AUTOSAR XML (schema 4-3-0)
package /MICROSAR/Dem_swc/DataTypes
  22 x impl type:
    Dem_EventIdType: range raw 1..65535, implementation-data-type=uint16
    Dem_RatioIdType: range raw 1..65535, implementation-data-type=uint16
    Dem_DTCStatusMaskType: range raw 0..255, implementation-data-type=uint8
    Dem_OperationCycleIdType: range raw 0..255, implementation-data-type=uint8
    Dem_DTCGroupType: range raw 0..16777215, implementation-data-type=uint32
    Dem_MaxDataValueType: category=ARRAY, sw-calibration-access=READ-ONLY
      element Dem_MaxDataValueTypeElement: array-size=1, array-size-semantics=FIXED-SIZE, implementation-data-type=uint8
    Dem_UdsStatusByteType: compu {mask 1: 1=DEM_UDS_STATUS_TF, mask 2: 2=DEM_UDS_STATUS_TFTOC, mask 4: 4=DEM_UDS_STATUS_PDTC, mask 8: 8=DEM_UDS_STATUS_CDTC, mask 16: 16=DEM_UDS_STATUS_TNCSLC, mask 32: 32=DEM_UDS_STATUS_TFSLC, mask 64: 64=DEM_UDS_STATUS_TNCTOC, mask 128: 128=DEM_UDS_STATUS_WIR}, range raw 0..255, implementation-data-type=uint8
    Dem_InitMonitorReasonType: compu {1=DEM_INIT_MONITOR_CLEAR, 2=DEM_INIT_MONITOR_RESTART, 3=DEM_INIT_MONITOR_REENABLED, 4=DEM_INIT_MONITOR_STORAGE_REENABLED}, implementation-data-type=uint8
    Dem_DTCFormatType: compu {0=DEM_DTC_FORMAT_OBD, 1=DEM_DTC_FORMAT_UDS, 2=DEM_DTC_FORMAT_J1939}, implementation-data-type=uint8
    Dem_OperationCycleStateType: compu {0=DEM_CYCLE_STATE_START, 1=DEM_CYCLE_STATE_END}, implementation-data-type=uint8
    Dem_IndicatorStatusType: compu {0=DEM_INDICATOR_OFF, 1=DEM_INDICATOR_CONTINUOUS, 2=DEM_INDICATOR_BLINKING, 3=DEM_INDICATOR_BLINK_CONT, 4=DEM_INDICATOR_SLOW_FLASH, 5=DEM_INDICATOR_FAST_FLASH, 6=DEM_INDICATOR_ON_DEMAND, 7=DEM_INDICATOR_SHORT}, implementation-data-type=uint8
    Dem_DTCKindType: compu {1=DEM_DTC_KIND_ALL_DTCS, 2=DEM_DTC_KIND_EMISSION_REL_DTCS}, implementation-data-type=uint8
    Dem_IumprDenomCondIdType: compu {1=DEM_IUMPR_GENERAL_DENOMINATOR, 2=DEM_IUMPR_DEN_COND_COLDSTART, 3=DEM_IUMPR_DEN_COND_EVAP, 4=DEM_IUMPR_DEN_COND_500MI}, implementation-data-type=uint8
    Dem_IumprDenomCondStatusType: compu {0=DEM_IUMPR_DEN_STATUS_NOT_REACHED, 1=DEM_IUMPR_DEN_STATUS_REACHED, 2=DEM_IUMPR_DEN_STATUS_INHIBITED}, implementation-data-type=uint8
    Dem_DebounceResetStatusType: compu {0=DEM_DEBOUNCE_STATUS_FREEZE, 1=DEM_DEBOUNCE_STATUS_RESET}, implementation-data-type=uint8
    Dem_DebouncingStateType: compu {mask 1: 1=DEM_TEMPORARILY_DEFECTIVE, mask 2: 2=DEM_FINALLY_DEFECTIVE, mask 4: 4=DEM_TEMPORARILY_HEALED, mask 8: 8=DEM_TEST_COMPLETE, mask 16: 16=DEM_DTR_UPDATE}, range raw 0..255, implementation-data-type=uint8
    Dem_EventStatusType: compu {0=DEM_EVENT_STATUS_PASSED, 1=DEM_EVENT_STATUS_FAILED, 2=DEM_EVENT_STATUS_PREPASSED, 3=DEM_EVENT_STATUS_PREFAILED, 4=DEM_EVENT_STATUS_FDC_THRESHOLD_REACHED, 5=DEM_EVENT_STATUS_PASSED_CONDITIONS_NOT_FULFILLED, 6=DEM_EVENT_STATUS_FAILED_CONDITIONS_NOT_FULFILLED, 7=DEM_EVENT_STATUS_PREPASSED_CONDITIONS_NOT_FULFILLED, 8=DEM_EVENT_STATUS_PREFAILED_CONDITIONS_NOT_FULFILLED}, implementation-data-type=uint8
    Dem_DTCOriginType: compu {1=DEM_DTC_ORIGIN_PRIMARY_MEMORY, 2=DEM_DTC_ORIGIN_MIRROR_MEMORY, 3=DEM_DTC_ORIGIN_PERMANENT_MEMORY, 4=DEM_DTC_ORIGIN_OBD_RELEVANT_MEMORY, 5=DEM_DTC_ORIGIN_SECONDARY_MEMORY, 5=DEM_DTC_ORIGIN_USERDEFINED_MEMORY_10, 5=DEM_DTC_ORIGIN_USERDEFINED_MEMORY_11, 5=DEM_DTC_ORIGIN_USERDEFINED_MEMORY_12, 5=DEM_DTC_ORIGIN_USERDEFINED_MEMORY_13, 5=DEM_DTC_ORIGIN_USERDEFINED_MEMORY_14, 5=DEM_DTC_ORIGIN_USERDEFINED_MEMORY_15, 5=DEM_DTC_ORIGIN_USERDEFINED_MEMORY_16, 5=DEM_DTC_ORIGIN_USERDEFINED_MEMORY_17, 5=DEM_DTC_ORIGIN_USERDEFINED_MEMORY_18, 5=DEM_DTC_ORIGIN_USERDEFINED_MEMORY_19, 5=DEM_DTC_ORIGIN_USERDEFINED_MEMORY_1A, 5=DEM_DTC_ORIGIN_USERDEFINED_MEMORY_1B, 5=DEM_DTC_ORIGIN_USERDEFINED_MEMORY_1C, 5=DEM_DTC_ORIGIN_USERDEFINED_MEMORY_1D, 5=DEM_DTC_ORIGIN_USERDEFINED_MEMORY_1E, 5=DEM_DTC_ORIGIN_USERDEFINED_MEMORY_1F, 5=DEM_DTC_ORIGIN_USERDEFINED_MEMORY_20, 5=DEM_DTC_ORIGIN_USERDEFINED_MEMORY_21, 5=DEM_DTC_ORIGIN_USERDEFINED_MEMORY_22, 5=DEM_DTC_ORIGIN_USERDEFINED_MEMORY_23, 5=DEM_DTC_ORIGIN_USERDEFINED_MEMORY_24, 5=DEM_DTC_ORIGIN_USERDEFINED_MEMORY_25, 5=DEM_DTC_ORIGIN_USERDEFINED_MEMORY_26, 5=DEM_DTC_ORIGIN_USERDEFINED_MEMORY_27, 5=DEM_DTC_ORIGIN_USERDEFINED_MEMORY_28, 5=DEM_DTC_ORIGIN_USERDEFINED_MEMORY_29, 5=DEM_DTC_ORIGIN_USERDEFINED_MEMORY_2A, 5=DEM_DTC_ORIGIN_USERDEFINED_MEMORY_2B, 5=DEM_DTC_ORIGIN_USERDEFINED_MEMORY_2C, 5=DEM_DTC_ORIGIN_USERDEFINED_MEMORY_2D, 5=DEM_DTC_ORIGIN_USERDEFINED_MEMORY_2E, 5=DEM_DTC_ORIGIN_USERDEFINED_MEMORY_2F, 5=DEM_DTC_ORIGIN_USERDEFINED_MEMORY_30, 5=DEM_DTC_ORIGIN_USERDEFINED_MEMORY_31, 5=DEM_DTC_ORIGIN_USERDEFINED_MEMORY_32, 5=DEM_DTC_ORIGIN_USERDEFINED_MEMORY_33, 5=DEM_DTC_ORIGIN_USERDEFINED_MEMORY_34, 5=DEM_DTC_ORIGIN_USERDEFINED_MEMORY_35, 5=DEM_DTC_ORIGIN_USERDEFINED_MEMORY_36, 5=DEM_DTC_ORIGIN_USERDEFINED_MEMORY_37, 5=DEM_DTC_ORIGIN_USERDEFINED_MEMORY_38, 5=DEM_DTC_ORIGIN_USERDEFINED_MEMORY_39, 5=DEM_DTC_ORIGIN_USERDEFINED_MEMORY_3A, 5=DEM_DTC_ORIGIN_USERDEFINED_MEMORY_3B, 5=DEM_DTC_ORIGIN_USERDEFINED_MEMORY_3C, 5=DEM_DTC_ORIGIN_USERDEFINED_MEMORY_3D, 5=DEM_DTC_ORIGIN_USERDEFINED_MEMORY_3E, 5=DEM_DTC_ORIGIN_USERDEFINED_MEMORY_3F, 5=DEM_DTC_ORIGIN_USERDEFINED_MEMORY_40, 5=DEM_DTC_ORIGIN_USERDEFINED_MEMORY_41, 5=DEM_DTC_ORIGIN_USERDEFINED_MEMORY_42, 5=DEM_DTC_ORIGIN_USERDEFINED_MEMORY_43, 5=DEM_DTC_ORIGIN_USERDEFINED_MEMORY_44, 5=DEM_DTC_ORIGIN_USERDEFINED_MEMORY_45, 5=DEM_DTC_ORIGIN_USERDEFINED_MEMORY_46, 5=DEM_DTC_ORIGIN_USERDEFINED_MEMORY_47, 5=DEM_DTC_ORIGIN_USERDEFINED_MEMORY_48, 5=DEM_DTC_ORIGIN_USERDEFINED_MEMORY_49, 5=DEM_DTC_ORIGIN_USERDEFINED_MEMORY_4A, 5=DEM_DTC_ORIGIN_USERDEFINED_MEMORY_4B, 5=DEM_DTC_ORIGIN_USERDEFINED_MEMORY_4C, 5=DEM_DTC_ORIGIN_USERDEFINED_MEMORY_4D, 5=DEM_DTC_ORIGIN_USERDEFINED_MEMORY_4E, 5=DEM_DTC_ORIGIN_USERDEFINED_MEMORY_4F, 5=DEM_DTC_ORIGIN_USERDEFINED_MEMORY_50, 5=DEM_DTC_ORIGIN_USERDEFINED_MEMORY_51, 5=DEM_DTC_ORIGIN_USERDEFINED_MEMORY_52, 5=DEM_DTC_ORIGIN_USERDEFINED_MEMORY_53, 5=DEM_DTC_ORIGIN_USERDEFINED_MEMORY_54, 5=DEM_DTC_ORIGIN_USERDEFINED_MEMORY_55, 5=DEM_DTC_ORIGIN_USERDEFINED_MEMORY_56, 5=DEM_DTC_ORIGIN_USERDEFINED_MEMORY_57, 5=DEM_DTC_ORIGIN_USERDEFINED_MEMORY_58, 5=DEM_DTC_ORIGIN_USERDEFINED_MEMORY_59, 5=DEM_DTC_ORIGIN_USERDEFINED_MEMORY_5A, 5=DEM_DTC_ORIGIN_USERDEFINED_MEMORY_5B, 5=DEM_DTC_ORIGIN_USERDEFINED_MEMORY_5C, 5=DEM_DTC_ORIGIN_USERDEFINED_MEMORY_5D, 5=DEM_DTC_ORIGIN_USERDEFINED_MEMORY_5E, 5=DEM_DTC_ORIGIN_USERDEFINED_MEMORY_5F, 5=DEM_DTC_ORIGIN_USERDEFINED_MEMORY_60, 5=DEM_DTC_ORIGIN_USERDEFINED_MEMORY_61, 5=DEM_DTC_ORIGIN_USERDEFINED_MEMORY_62, 5=DEM_DTC_ORIGIN_USERDEFINED_MEMORY_63, 5=DEM_DTC_ORIGIN_USERDEFINED_MEMORY_64, 5=DEM_DTC_ORIGIN_USERDEFINED_MEMORY_65, 5=DEM_DTC_ORIGIN_USERDEFINED_MEMORY_66, 5=DEM_DTC_ORIGIN_USERDEFINED_MEMORY_67, 5=DEM_DTC_ORIGIN_USERDEFINED_MEMORY_68, 5=DEM_DTC_ORIGIN_USERDEFINED_MEMORY_69, 5=DEM_DTC_ORIGIN_USERDEFINED_MEMORY_6A, 5=DEM_DTC_ORIGIN_USERDEFINED_MEMORY_6B, 5=DEM_DTC_ORIGIN_USERDEFINED_MEMORY_6C, 5=DEM_DTC_ORIGIN_USERDEFINED_MEMORY_6D, 5=DEM_DTC_ORIGIN_USERDEFINED_MEMORY_6E, 5=DEM_DTC_ORIGIN_USERDEFINED_MEMORY_6F, 5=DEM_DTC_ORIGIN_USERDEFINED_MEMORY_70, 5=DEM_DTC_ORIGIN_USERDEFINED_MEMORY_71, 5=DEM_DTC_ORIGIN_USERDEFINED_MEMORY_72, 5=DEM_DTC_ORIGIN_USERDEFINED_MEMORY_73, 5=DEM_DTC_ORIGIN_USERDEFINED_MEMORY_74, 5=DEM_DTC_ORIGIN_USERDEFINED_MEMORY_75, 5=DEM_DTC_ORIGIN_USERDEFINED_MEMORY_76, 5=DEM_DTC_ORIGIN_USERDEFINED_MEMORY_77, 5=DEM_DTC_ORIGIN_USERDEFINED_MEMORY_78, 5=DEM_DTC_ORIGIN_USERDEFINED_MEMORY_79, 5=DEM_DTC_ORIGIN_USERDEFINED_MEMORY_7A, 5=DEM_DTC_ORIGIN_USERDEFINED_MEMORY_7B, 5=DEM_DTC_ORIGIN_USERDEFINED_MEMORY_7C, 5=DEM_DTC_ORIGIN_USERDEFINED_MEMORY_7D, 5=DEM_DTC_ORIGIN_USERDEFINED_MEMORY_7E, 5=DEM_DTC_ORIGIN_USERDEFINED_MEMORY_7F, 5=DEM_DTC_ORIGIN_USERDEFINED_MEMORY_80, 5=DEM_DTC_ORIGIN_USERDEFINED_MEMORY_81, 5=DEM_DTC_ORIGIN_USERDEFINED_MEMORY_82, 5=DEM_DTC_ORIGIN_USERDEFINED_MEMORY_83, 5=DEM_DTC_ORIGIN_USERDEFINED_MEMORY_84, 5=DEM_DTC_ORIGIN_USERDEFINED_MEMORY_85, 5=DEM_DTC_ORIGIN_USERDEFINED_MEMORY_86, 5=DEM_DTC_ORIGIN_USERDEFINED_MEMORY_87, 5=DEM_DTC_ORIGIN_USERDEFINED_MEMORY_88, 5=DEM_DTC_ORIGIN_USERDEFINED_MEMORY_89, 5=DEM_DTC_ORIGIN_USERDEFINED_MEMORY_8A, 5=DEM_DTC_ORIGIN_USERDEFINED_MEMORY_8B, 5=DEM_DTC_ORIGIN_USERDEFINED_MEMORY_8C, 5=DEM_DTC_ORIGIN_USERDEFINED_MEMORY_8D, 5=DEM_DTC_ORIGIN_USERDEFINED_MEMORY_8E, 5=DEM_DTC_ORIGIN_USERDEFINED_MEMORY_8F, 5=DEM_DTC_ORIGIN_USERDEFINED_MEMORY_90, 5=DEM_DTC_ORIGIN_USERDEFINED_MEMORY_91, 5=DEM_DTC_ORIGIN_USERDEFINED_MEMORY_92, 5=DEM_DTC_ORIGIN_USERDEFINED_MEMORY_93, 5=DEM_DTC_ORIGIN_USERDEFINED_MEMORY_94, 5=DEM_DTC_ORIGIN_USERDEFINED_MEMORY_95, 5=DEM_DTC_ORIGIN_USERDEFINED_MEMORY_96, 5=DEM_DTC_ORIGIN_USERDEFINED_MEMORY_97, 5=DEM_DTC_ORIGIN_USERDEFINED_MEMORY_98, 5=DEM_DTC_ORIGIN_USERDEFINED_MEMORY_99, 5=DEM_DTC_ORIGIN_USERDEFINED_MEMORY_9A, 5=DEM_DTC_ORIGIN_USERDEFINED_MEMORY_9B, 5=DEM_DTC_ORIGIN_USERDEFINED_MEMORY_9C, 5=DEM_DTC_ORIGIN_USERDEFINED_MEMORY_9D, 5=DEM_DTC_ORIGIN_USERDEFINED_MEMORY_9E, 5=DEM_DTC_ORIGIN_USERDEFINED_MEMORY_9F, 5=DEM_DTC_ORIGIN_USERDEFINED_MEMORY_A0, 5=DEM_DTC_ORIGIN_USERDEFINED_MEMORY_A1, 5=DEM_DTC_ORIGIN_USERDEFINED_MEMORY_A2, 5=DEM_DTC_ORIGIN_USERDEFINED_MEMORY_A3, 5=DEM_DTC_ORIGIN_USERDEFINED_MEMORY_A4, 5=DEM_DTC_ORIGIN_USERDEFINED_MEMORY_A5, 5=DEM_DTC_ORIGIN_USERDEFINED_MEMORY_A6, 5=DEM_DTC_ORIGIN_USERDEFINED_MEMORY_A7, 5=DEM_DTC_ORIGIN_USERDEFINED_MEMORY_A8, 5=DEM_DTC_ORIGIN_USERDEFINED_MEMORY_A9, 5=DEM_DTC_ORIGIN_USERDEFINED_MEMORY_AA, 5=DEM_DTC_ORIGIN_USERDEFINED_MEMORY_AB, 5=DEM_DTC_ORIGIN_USERDEFINED_MEMORY_AC, 5=DEM_DTC_ORIGIN_USERDEFINED_MEMORY_AD, 5=DEM_DTC_ORIGIN_USERDEFINED_MEMORY_AE, 5=DEM_DTC_ORIGIN_USERDEFINED_MEMORY_AF, 5=DEM_DTC_ORIGIN_USERDEFINED_MEMORY_B0, 5=DEM_DTC_ORIGIN_USERDEFINED_MEMORY_B1, 5=DEM_DTC_ORIGIN_USERDEFINED_MEMORY_B2, 5=DEM_DTC_ORIGIN_USERDEFINED_MEMORY_B3, 5=DEM_DTC_ORIGIN_USERDEFINED_MEMORY_B4, 5=DEM_DTC_ORIGIN_USERDEFINED_MEMORY_B5, 5=DEM_DTC_ORIGIN_USERDEFINED_MEMORY_B6, 5=DEM_DTC_ORIGIN_USERDEFINED_MEMORY_B7, 5=DEM_DTC_ORIGIN_USERDEFINED_MEMORY_B8, 5=DEM_DTC_ORIGIN_USERDEFINED_MEMORY_B9, 5=DEM_DTC_ORIGIN_USERDEFINED_MEMORY_BA, 5=DEM_DTC_ORIGIN_USERDEFINED_MEMORY_BB, 5=DEM_DTC_ORIGIN_USERDEFINED_MEMORY_BC, 5=DEM_DTC_ORIGIN_USERDEFINED_MEMORY_BD, 5=DEM_DTC_ORIGIN_USERDEFINED_MEMORY_BE, 5=DEM_DTC_ORIGIN_USERDEFINED_MEMORY_BF, 5=DEM_DTC_ORIGIN_USERDEFINED_MEMORY_C0, 5=DEM_DTC_ORIGIN_USERDEFINED_MEMORY_C1, 5=DEM_DTC_ORIGIN_USERDEFINED_MEMORY_C2, 5=DEM_DTC_ORIGIN_USERDEFINED_MEMORY_C3, 5=DEM_DTC_ORIGIN_USERDEFINED_MEMORY_C4, 5=DEM_DTC_ORIGIN_USERDEFINED_MEMORY_C5, 5=DEM_DTC_ORIGIN_USERDEFINED_MEMORY_C6, 5=DEM_DTC_ORIGIN_USERDEFINED_MEMORY_C7, 5=DEM_DTC_ORIGIN_USERDEFINED_MEMORY_C8, 5=DEM_DTC_ORIGIN_USERDEFINED_MEMORY_C9, 5=DEM_DTC_ORIGIN_USERDEFINED_MEMORY_CA, 5=DEM_DTC_ORIGIN_USERDEFINED_MEMORY_CB, 5=DEM_DTC_ORIGIN_USERDEFINED_MEMORY_CC, 5=DEM_DTC_ORIGIN_USERDEFINED_MEMORY_CD, 5=DEM_DTC_ORIGIN_USERDEFINED_MEMORY_CE, 5=DEM_DTC_ORIGIN_USERDEFINED_MEMORY_CF, 5=DEM_DTC_ORIGIN_USERDEFINED_MEMORY_D0, 5=DEM_DTC_ORIGIN_USERDEFINED_MEMORY_D1, 5=DEM_DTC_ORIGIN_USERDEFINED_MEMORY_D2, 5=DEM_DTC_ORIGIN_USERDEFINED_MEMORY_D3, 5=DEM_DTC_ORIGIN_USERDEFINED_MEMORY_D4, 5=DEM_DTC_ORIGIN_USERDEFINED_MEMORY_D5, 5=DEM_DTC_ORIGIN_USERDEFINED_MEMORY_D6, 5=DEM_DTC_ORIGIN_USERDEFINED_MEMORY_D7, 5=DEM_DTC_ORIGIN_USERDEFINED_MEMORY_D8, 5=DEM_DTC_ORIGIN_USERDEFINED_MEMORY_D9, 5=DEM_DTC_ORIGIN_USERDEFINED_MEMORY_DA, 5=DEM_DTC_ORIGIN_USERDEFINED_MEMORY_DB, 5=DEM_DTC_ORIGIN_USERDEFINED_MEMORY_DC, 5=DEM_DTC_ORIGIN_USERDEFINED_MEMORY_DD, 5=DEM_DTC_ORIGIN_USERDEFINED_MEMORY_DE, 5=DEM_DTC_ORIGIN_USERDEFINED_MEMORY_DF, 5=DEM_DTC_ORIGIN_USERDEFINED_MEMORY_E0, 5=DEM_DTC_ORIGIN_USERDEFINED_MEMORY_E1, 5=DEM_DTC_ORIGIN_USERDEFINED_MEMORY_E2, 5=DEM_DTC_ORIGIN_USERDEFINED_MEMORY_E3, 5=DEM_DTC_ORIGIN_USERDEFINED_MEMORY_E4, 5=DEM_DTC_ORIGIN_USERDEFINED_MEMORY_E5, 5=DEM_DTC_ORIGIN_USERDEFINED_MEMORY_E6, 5=DEM_DTC_ORIGIN_USERDEFINED_MEMORY_E7, 5=DEM_DTC_ORIGIN_USERDEFINED_MEMORY_E8, 5=DEM_DTC_ORIGIN_USERDEFINED_MEMORY_E9, 5=DEM_DTC_ORIGIN_USERDEFINED_MEMORY_EA, 5=DEM_DTC_ORIGIN_USERDEFINED_MEMORY_EB, 5=DEM_DTC_ORIGIN_USERDEFINED_MEMORY_EC, 5=DEM_DTC_ORIGIN_USERDEFINED_MEMORY_ED, 5=DEM_DTC_ORIGIN_USERDEFINED_MEMORY_EE, 5=DEM_DTC_ORIGIN_USERDEFINED_MEMORY_EF, 5=DEM_DTC_ORIGIN_USERDEFINED_MEMORY_F0, 5=DEM_DTC_ORIGIN_USERDEFINED_MEMORY_F1, 5=DEM_DTC_ORIGIN_USERDEFINED_MEMORY_F2, 5=DEM_DTC_ORIGIN_USERDEFINED_MEMORY_F3, 5=DEM_DTC_ORIGIN_USERDEFINED_MEMORY_F4, 5=DEM_DTC_ORIGIN_USERDEFINED_MEMORY_F5, 5=DEM_DTC_ORIGIN_USERDEFINED_MEMORY_F6, 5=DEM_DTC_ORIGIN_USERDEFINED_MEMORY_F7, 5=DEM_DTC_ORIGIN_USERDEFINED_MEMORY_F8, 5=DEM_DTC_ORIGIN_USERDEFINED_MEMORY_F9, 5=DEM_DTC_ORIGIN_USERDEFINED_MEMORY_FA, 5=DEM_DTC_ORIGIN_USERDEFINED_MEMORY_FB, 5=DEM_DTC_ORIGIN_USERDEFINED_MEMORY_FC, 5=DEM_DTC_ORIGIN_USERDEFINED_MEMORY_FD, 5=DEM_DTC_ORIGIN_USERDEFINED_MEMORY_FE, 5=DEM_DTC_ORIGIN_USERDEFINED_MEMORY_FF}, implementation-data-type=uint16
    Dem_IumprReadinessGroupType: compu {0=DEM_IUMPR_BOOSTPRS, 1=DEM_IUMPR_CAT1, 2=DEM_IUMPR_CAT2, 3=DEM_IUMPR_EGR, 4=DEM_IUMPR_EGSENSOR, 5=DEM_IUMPR_EVAP, 6=DEM_IUMPR_NMHCCAT, 7=DEM_IUMPR_NOXADSORB, 8=DEM_IUMPR_NOXCAT, 9=DEM_IUMPR_OXS1, 10=DEM_IUMPR_OXS2, 11=DEM_IUMPR_PMFILTER, 12=DEM_IUMPR_PRIVATE, 13=DEM_IUMPR_SAIR, 14=DEM_IUMPR_SECOXS1, 15=DEM_IUMPR_SECOXS2, 16=DEM_IUMPR_FLSYS, 255=DEM_IUMPR_ALLGROUPS}, implementation-data-type=uint8
    Dem_DTRControlType: compu {0=DEM_DTR_CTL_NORMAL, 1=DEM_DTR_CTL_NO_MAX, 2=DEM_DTR_CTL_NO_MIN, 3=DEM_DTR_CTL_RESET, 4=DEM_DTR_CTL_INVISIBLE}, implementation-data-type=uint8
    Dem_DTCSeverityType:
      compu {mask 255: 0=DEM_SEVERITY_NO_SEVERITY, mask 31: 2=DEM_SEVERITY_WWHOBD_CLASS_A, mask 31: 4=DEM_SEVERITY_WWHOBD_CLASS_B1, mask 31: 8=DEM_SEVERITY_WWHOBD_CLASS_B2, mask 31: 16=DEM_SEVERITY_WWHOBD_CLASS_C, mask 31: 1=DEM_SEVERITY_WWHOBD_CLASS_NO_CLASS, mask 224: 64=DEM_SEVERITY_CHECK_AT_NEXT_HALT, mask 224: 128=DEM_SEVERITY_CHECK_IMMEDIATELY, mask 224: 32=DEM_SEVERITY_MAINTENANCE_ONLY}
      range raw 0..255
      implementation-data-type=uint8
    Dem_MonitorStatusType: compu {mask 1: 1=DEM_MONITOR_STATUS_TF, mask 2: 2=DEM_MONITOR_STATUS_TNCTOC}, range raw 0..255, implementation-data-type=uint8
package /MICROSAR/Dem_swc/Interfaces
  7 x client server interface, all with is-service=true, service-kind=DIAGNOSTIC-EVENT-MANAGER:
    DemServices
      operation GetPostRunRequested: possible-error=DemServices/E_NOT_OK
        arg IsRequested: type=boolean, direction=OUT
      operation GetDTCStatusAvailabilityMask: possible-error=DemServices/E_NOT_OK
        arg ClientId: type=uint8, direction=IN
        arg DTCStatusMask: type=uint8, direction=OUT
      error E_NOT_OK: error-code=1
    EvMemOverflowIndication
      operation GetEventMemoryOverflow: possible-error=EvMemOverflowIndication/E_NOT_OK
        arg OverflowIndication: type=boolean, direction=OUT
      operation GetNumberOfEventMemoryEntries: possible-error=EvMemOverflowIndication/E_NOT_OK
        arg NumberOfEventMemoryEntries: type=uint8, direction=OUT
      error E_NOT_OK: error-code=1
    GeneralDiagnosticInfo
      11 x operation:
        GetEventStatus: possible-error=GeneralDiagnosticInfo/E_NOT_OK
          arg EventId: type=Dem_EventIdType, direction=IN
          arg UDSStatusByte: type=Dem_UdsStatusByteType, direction=OUT
        GetEventFailed: possible-error=GeneralDiagnosticInfo/E_NOT_OK
          arg EventId: type=Dem_EventIdType, direction=IN
          arg EventFailed: type=boolean, direction=OUT
        GetEventTested: possible-error=GeneralDiagnosticInfo/E_NOT_OK
          arg EventId: type=Dem_EventIdType, direction=IN
          arg EventTested: type=boolean, direction=OUT
        GetDTCOfEvent: possible-error=[GeneralDiagnosticInfo/E_NOT_OK, GeneralDiagnosticInfo/DEM_E_NO_DTC_AVAILABLE]
          arg EventId: type=Dem_EventIdType, direction=IN
          arg DTCFormat: type=Dem_DTCFormatType, direction=IN
          arg DTCOfEvent: type=uint32, direction=OUT
        GetFaultDetectionCounter: possible-error=[GeneralDiagnosticInfo/E_NOT_OK, GeneralDiagnosticInfo/DEM_E_NO_FDC_AVAILABLE]
          arg EventId: type=Dem_EventIdType, direction=IN
          arg FaultDetectionCounter: type=sint8, direction=OUT
        GetEventEnableCondition: possible-error=GeneralDiagnosticInfo/E_NOT_OK
          arg EventId: type=Dem_EventIdType, direction=IN
          arg ConditionFullfilled: type=boolean, direction=OUT
        GetDebouncingOfEvent: possible-error=GeneralDiagnosticInfo/E_NOT_OK
          arg EventId: type=Dem_EventIdType, direction=IN
          arg DebouncingState: type=Dem_DebouncingStateType, direction=OUT
        GetEventUdsStatus: possible-error=GeneralDiagnosticInfo/E_NOT_OK
          arg EventId: type=Dem_EventIdType, direction=IN
          arg UDSStatusByte: type=Dem_UdsStatusByteType, direction=OUT
        GetEventFreezeFrameDataEx: possible-error=[GeneralDiagnosticInfo/E_NOT_OK, GeneralDiagnosticInfo/DEM_BUFFER_TOO_SMALL, GeneralDiagnosticInfo/DEM_NO_SUCH_ELEMENT]
          5 x arg:
            EventId: type=Dem_EventIdType, direction=IN
            RecordNumber: type=uint8, direction=IN
            DataId: type=uint16, direction=IN
            DestBuffer: type=Dem_MaxDataValueType, direction=OUT
            BufSize: type=uint16, direction=INOUT
        GetEventExtendedDataRecordEx: possible-error=[GeneralDiagnosticInfo/E_NOT_OK, GeneralDiagnosticInfo/DEM_BUFFER_TOO_SMALL, GeneralDiagnosticInfo/DEM_NO_SUCH_ELEMENT]
          4 x arg:
            EventId: type=Dem_EventIdType, direction=IN
            RecordNumber: type=uint8, direction=IN
            DestBuffer: type=Dem_MaxDataValueType, direction=OUT
            BufSize: type=uint16, direction=INOUT
        GetMonitorStatus: possible-error=GeneralDiagnosticInfo/E_NOT_OK
          arg EventId: type=Dem_EventIdType, direction=IN
          arg MonitorStatus: type=Dem_MonitorStatusType, direction=OUT
      5 x error:
        E_NOT_OK: error-code=1
        DEM_E_NO_DTC_AVAILABLE: error-code=10
        DEM_E_NO_FDC_AVAILABLE: error-code=14
        DEM_BUFFER_TOO_SMALL: error-code=21
        DEM_NO_SUCH_ELEMENT: error-code=48
    DiagnosticInfo
      11 x operation:
        GetEventStatus: possible-error=DiagnosticInfo/E_NOT_OK
          arg UDSStatusByte: type=Dem_UdsStatusByteType, direction=OUT
        GetEventFailed: possible-error=DiagnosticInfo/E_NOT_OK
          arg EventFailed: type=boolean, direction=OUT
        GetEventTested: possible-error=DiagnosticInfo/E_NOT_OK
          arg EventTested: type=boolean, direction=OUT
        GetDTCOfEvent: possible-error=[DiagnosticInfo/E_NOT_OK, DiagnosticInfo/DEM_E_NO_DTC_AVAILABLE]
          arg DTCFormat: type=Dem_DTCFormatType, direction=IN
          arg DTCOfEvent: type=uint32, direction=OUT
        GetFaultDetectionCounter: possible-error=[DiagnosticInfo/E_NOT_OK, DiagnosticInfo/DEM_E_NO_FDC_AVAILABLE]
          arg FaultDetectionCounter: type=sint8, direction=OUT
        GetEventEnableCondition: possible-error=DiagnosticInfo/E_NOT_OK
          arg ConditionFullfilled: type=boolean, direction=OUT
        GetDebouncingOfEvent: possible-error=DiagnosticInfo/E_NOT_OK
          arg DebouncingState: type=Dem_DebouncingStateType, direction=OUT
        GetEventUdsStatus: possible-error=DiagnosticInfo/E_NOT_OK
          arg UDSStatusByte: type=Dem_UdsStatusByteType, direction=OUT
        GetEventFreezeFrameDataEx: possible-error=[DiagnosticInfo/E_NOT_OK, DiagnosticInfo/DEM_BUFFER_TOO_SMALL, DiagnosticInfo/DEM_NO_SUCH_ELEMENT]
          4 x arg:
            RecordNumber: type=uint8, direction=IN
            DataId: type=uint16, direction=IN
            DestBuffer: type=Dem_MaxDataValueType, direction=OUT
            BufSize: type=uint16, direction=INOUT
        GetEventExtendedDataRecordEx: possible-error=[DiagnosticInfo/E_NOT_OK, DiagnosticInfo/DEM_BUFFER_TOO_SMALL, DiagnosticInfo/DEM_NO_SUCH_ELEMENT]
          arg RecordNumber: type=uint8, direction=IN
          arg DestBuffer: type=Dem_MaxDataValueType, direction=OUT
          arg BufSize: type=uint16, direction=INOUT
        GetMonitorStatus: possible-error=DiagnosticInfo/E_NOT_OK
          arg MonitorStatus: type=Dem_MonitorStatusType, direction=OUT
      5 x error:
        E_NOT_OK: error-code=1
        DEM_E_NO_DTC_AVAILABLE: error-code=10
        DEM_E_NO_FDC_AVAILABLE: error-code=14
        DEM_BUFFER_TOO_SMALL: error-code=21
        DEM_NO_SUCH_ELEMENT: error-code=48
    OperationCycle
      operation SetOperationCycleState: possible-error=[OperationCycle/E_OK, OperationCycle/E_NOT_OK]
        arg CycleState: type=Dem_OperationCycleStateType, direction=IN
      operation GetOperationCycleState: possible-error=[OperationCycle/E_OK, OperationCycle/E_NOT_OK]
        arg CycleState: type=Dem_OperationCycleStateType, direction=OUT
      error E_NOT_OK: error-code=1
      error E_OK: error-code=0
    ClearDTC
      operation ClearDTC: possible-error=[ClearDTC/E_NOT_OK, DEM_CLEAR_FAILED, DEM_PENDING, DEM_CLEAR_BUSY, DEM_CLEAR_MEMORY_ERROR, DEM_WRONG_DTC, DEM_WRONG_DTCORIGIN]
      operation SelectDTC: possible-error=[ClearDTC/E_OK, ClearDTC/E_NOT_OK]
        arg DTC: type=uint32, direction=IN
        arg DTCFormat: type=Dem_DTCFormatType, direction=IN
        arg DTCOrigin: type=Dem_DTCOriginType, direction=IN
      8 x error:
        E_OK: error-code=0
        E_NOT_OK: error-code=1
        DEM_CLEAR_FAILED: error-code=7
        DEM_PENDING: error-code=4
        DEM_CLEAR_BUSY: error-code=5
        DEM_CLEAR_MEMORY_ERROR: error-code=6
        DEM_WRONG_DTC: error-code=8
        DEM_WRONG_DTCORIGIN: error-code=9
    DiagnosticMonitor
      11 x operation:
        SetEventStatus: possible-error=DiagnosticMonitor/E_NOT_OK
          arg EventStatus: type=Dem_EventStatusType, direction=IN
        ResetEventStatus: possible-error=DiagnosticMonitor/E_NOT_OK
        ResetEventDebounceStatus: possible-error=DiagnosticMonitor/E_NOT_OK
          arg DebounceResetStatus: type=Dem_DebounceResetStatusType, direction=IN
        GetEventUdsStatus: possible-error=DiagnosticMonitor/E_NOT_OK
          arg UDSStatusByte: type=Dem_UdsStatusByteType, direction=OUT
        GetEventStatus: possible-error=DiagnosticMonitor/E_NOT_OK
          arg UDSStatusByte: type=Dem_UdsStatusByteType, direction=OUT
        GetEventFailed: possible-error=DiagnosticMonitor/E_NOT_OK
          arg EventFailed: type=boolean, direction=OUT
        GetEventTested: possible-error=DiagnosticMonitor/E_NOT_OK
          arg EventTested: type=boolean, direction=OUT
        GetDTCOfEvent: possible-error=[DiagnosticMonitor/E_NOT_OK, DiagnosticMonitor/DEM_E_NO_DTC_AVAILABLE]
          arg DTCFormat: type=Dem_DTCFormatType, direction=IN
          arg DTCOfEvent: type=uint32, direction=OUT
        GetFaultDetectionCounter: possible-error=[DiagnosticMonitor/E_NOT_OK, DiagnosticMonitor/DEM_E_NO_FDC_AVAILABLE]
          arg FaultDetectionCounter: type=sint8, direction=OUT
        GetEventFreezeFrameDataEx: possible-error=[DiagnosticMonitor/E_NOT_OK, DiagnosticMonitor/DEM_BUFFER_TOO_SMALL, DiagnosticMonitor/DEM_NO_SUCH_ELEMENT]
          4 x arg:
            RecordNumber: type=uint8, direction=IN
            DataId: type=uint16, direction=IN
            DestBuffer: type=Dem_MaxDataValueType, direction=OUT
            BufSize: type=uint16, direction=INOUT
        GetEventExtendedDataRecordEx: possible-error=[DiagnosticMonitor/E_NOT_OK, DiagnosticMonitor/DEM_BUFFER_TOO_SMALL, DiagnosticMonitor/DEM_NO_SUCH_ELEMENT]
          arg RecordNumber: type=uint8, direction=IN
          arg DestBuffer: type=Dem_MaxDataValueType, direction=OUT
          arg BufSize: type=uint16, direction=INOUT
      5 x error:
        E_NOT_OK: error-code=1
        DEM_E_NO_DTC_AVAILABLE: error-code=10
        DEM_E_NO_FDC_AVAILABLE: error-code=14
        DEM_BUFFER_TOO_SMALL: error-code=21
        DEM_NO_SUCH_ELEMENT: error-code=48
package /MICROSAR/Dem_swc/ComponentTypes
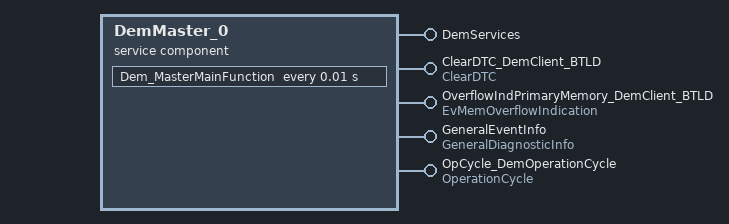
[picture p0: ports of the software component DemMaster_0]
  service sw component type DemMaster_0: category=SERVICE_COMPONENT
    5 x provide port:
      DemServices: provided-interface=DemServices
      ClearDTC_DemClient_BTLD: provided-interface=ClearDTC
      OverflowIndPrimaryMemory_DemClient_BTLD: provided-interface=EvMemOverflowIndication
      GeneralEventInfo: provided-interface=GeneralDiagnosticInfo
      OpCycle_DemOperationCycle: provided-interface=OperationCycle
    behavior DemMaster_0InternalBehavior: handle-termination-and-restart=NO-SUPPORT, included-data-type-set=data-type=[Dem_EventIdType, Dem_RatioIdType, Dem_EventStatusType, Dem_UdsStatusByteType, Dem_DTCFormatType, Dem_InitMonitorReasonType, Dem_OperationCycleStateType, Dem_DTCStatusMaskType, Dem_IndicatorStatusType, Dem_MaxDataValueType, Dem_DTCKindType, Dem_DTCGroupType, Dem_IumprDenomCondIdType, Dem_IumprDenomCondStatusType, Dem_DebounceResetStatusType, Dem_DebouncingStateType, Dem_IumprReadinessGroupType, Dem_DTRControlType, Dem_DTCSeverityType, Dem_MonitorStatusType]
      timing event Timer_Dem_MasterMainFunction: start-on-event=Dem_MasterMainFunction, period=0.01
      19 x operation invoked event:
        OpEventPostRunRequested_GetPostRunRequested_DemServices: start-on-event=PostRunRequested, operation=DemServices.GetPostRunRequested
        OpEventGetDTCStatusAvailabilityMask_GetDTCStatusAvailabilityMask_DemServices: start-on-event=GetDTCStatusAvailabilityMask, operation=DemServices.GetDTCStatusAvailabilityMask
        OpEventClearDTC_ClearDTC_ClearDTC_DemClient_BTLD: start-on-event=ClearDTC, operation=ClearDTC_DemClient_BTLD.ClearDTC
        OpEventSelectDTC_SelectDTC_ClearDTC_DemClient_BTLD: start-on-event=SelectDTC, operation=ClearDTC_DemClient_BTLD.SelectDTC
        OpEventGetEventMemoryOverflow_GetEventMemoryOverflow_OverflowIndPrimaryMemory_DemClient_BTLD: start-on-event=GetEventMemoryOverflow, operation=OverflowIndPrimaryMemory_DemClient_BTLD.GetEventMemoryOverflow
        OpEventGetNumberOfEventMemoryEntries_GetNumberOfEventMemoryEntries_OverflowIndPrimaryMemory_DemClient_BTLD: start-on-event=GetNumberOfEventMemoryEntries, operation=OverflowIndPrimaryMemory_DemClient_BTLD.GetNumberOfEventMemoryEntries
        OpEventGetEventUdsStatus_GetEventUdsStatus_GeneralEventInfo: start-on-event=DemMaster_0InternalBehavior/GetEventUdsStatus, operation=GeneralEventInfo.GetEventUdsStatus
        OpEventGetEventStatus_GetEventStatus_GeneralEventInfo: start-on-event=DemMaster_0InternalBehavior/GetEventStatus, operation=GeneralEventInfo.GetEventStatus
        OpEventGetEventFailed_GetEventFailed_GeneralEventInfo: start-on-event=DemMaster_0InternalBehavior/GetEventFailed, operation=GeneralEventInfo.GetEventFailed
        OpEventGetEventTested_GetEventTested_GeneralEventInfo: start-on-event=DemMaster_0InternalBehavior/GetEventTested, operation=GeneralEventInfo.GetEventTested
        OpEventGetDTCOfEvent_GetDTCOfEvent_GeneralEventInfo: start-on-event=DemMaster_0InternalBehavior/GetDTCOfEvent, operation=GeneralEventInfo.GetDTCOfEvent
        OpEventGetFaultDetectionCounter_GetFaultDetectionCounter_GeneralEventInfo: start-on-event=DemMaster_0InternalBehavior/GetFaultDetectionCounter, operation=GeneralEventInfo.GetFaultDetectionCounter
        OpEventGetEventFreezeFrameDataEx_GetEventFreezeFrameDataEx_GeneralEventInfo: start-on-event=DemMaster_0InternalBehavior/GetEventFreezeFrameDataEx, operation=GeneralEventInfo.GetEventFreezeFrameDataEx
        OpEventGetEventExtendedDataRecordEx_GetEventExtendedDataRecordEx_GeneralEventInfo: start-on-event=DemMaster_0InternalBehavior/GetEventExtendedDataRecordEx, operation=GeneralEventInfo.GetEventExtendedDataRecordEx
        OpEventGetEventEnableCondition_GetEventEnableCondition_GeneralEventInfo: start-on-event=DemMaster_0InternalBehavior/GetEventEnableCondition, operation=GeneralEventInfo.GetEventEnableCondition
        OpEventGetDebouncingOfEvent_GetDebouncingOfEvent_GeneralEventInfo: start-on-event=DemMaster_0InternalBehavior/GetDebouncingOfEvent, operation=GeneralEventInfo.GetDebouncingOfEvent
        OpEventGetMonitorStatus_GetMonitorStatus_GeneralEventInfo: start-on-event=DemMaster_0InternalBehavior/GetMonitorStatus, operation=GeneralEventInfo.GetMonitorStatus
        OpEventGetOperationCycleState_GetOperationCycleState_OpCycle_DemOperationCycle: start-on-event=GetOperationCycleState, operation=OpCycle_DemOperationCycle.GetOperationCycleState
        OpEventSetOperationCycleState_SetOperationCycleState_OpCycle_DemOperationCycle: start-on-event=SetOperationCycleState, operation=OpCycle_DemOperationCycle.SetOperationCycleState
      port-api-options:
        enable-take-address=true, indirect-api=false, port=DemServices
        {enable-take-address=true, indirect-api=false, port-defined-argument-value{value=0, value-type=uint8}, port=ClearDTC_DemClient_BTLD}
        {enable-take-address=true, indirect-api=false, port-arg-values=[{value=0, value-type=uint8}, {value=1, value-type=Dem_DTCOriginType}], port=OverflowIndPrimaryMemory_DemClient_BTLD}
        enable-take-address=true, indirect-api=false, port=DemMaster_0/GeneralEventInfo
        {enable-take-address=true, indirect-api=false, port-defined-argument-value{value=0, value-type=Dem_OperationCycleIdType}, port=OpCycle_DemOperationCycle}
      20 x runnable:
        Dem_MasterMainFunction
        PostRunRequested: can-be-invoked-concurrently=true, symbol=Dem_PostRunRequested
        GetDTCStatusAvailabilityMask: can-be-invoked-concurrently=true, symbol=Dem_GetDTCStatusAvailabilityMask
        ClearDTC: can-be-invoked-concurrently=true, symbol=Dem_ClearDTC
        SelectDTC: can-be-invoked-concurrently=true, symbol=Dem_SelectDTC
        GetEventMemoryOverflow: can-be-invoked-concurrently=true, symbol=Dem_GetEventMemoryOverflow
        GetNumberOfEventMemoryEntries: can-be-invoked-concurrently=true, symbol=Dem_GetNumberOfEventMemoryEntries
        GetEventUdsStatus: can-be-invoked-concurrently=true, symbol=Dem_GetEventUdsStatus
        GetEventStatus: can-be-invoked-concurrently=true, symbol=Dem_GetEventUdsStatus
        GetEventFailed: can-be-invoked-concurrently=true, symbol=Dem_GetEventFailed
        GetEventTested: can-be-invoked-concurrently=true, symbol=Dem_GetEventTested
        GetDTCOfEvent: can-be-invoked-concurrently=true, symbol=Dem_GetDTCOfEvent
        GetFaultDetectionCounter: can-be-invoked-concurrently=true, symbol=Dem_GetFaultDetectionCounter
        GetEventFreezeFrameDataEx: can-be-invoked-concurrently=true, symbol=Dem_GetEventFreezeFrameDataEx
        GetEventExtendedDataRecordEx: can-be-invoked-concurrently=true, symbol=Dem_GetEventExtendedDataRecordEx
        GetEventEnableCondition: can-be-invoked-concurrently=true, symbol=Dem_GetEventEnableCondition
        GetDebouncingOfEvent: can-be-invoked-concurrently=true, symbol=Dem_GetDebouncingOfEvent
        GetMonitorStatus: can-be-invoked-concurrently=true, symbol=Dem_GetMonitorStatus
        GetOperationCycleState: can-be-invoked-concurrently=true, symbol=Dem_GetOperationCycleState
        SetOperationCycleState: can-be-invoked-concurrently=true, symbol=Dem_SetOperationCycleState
  swc implementation DemMaster_0Implementation: programming-language=C, behavior=DemMaster_0InternalBehavior
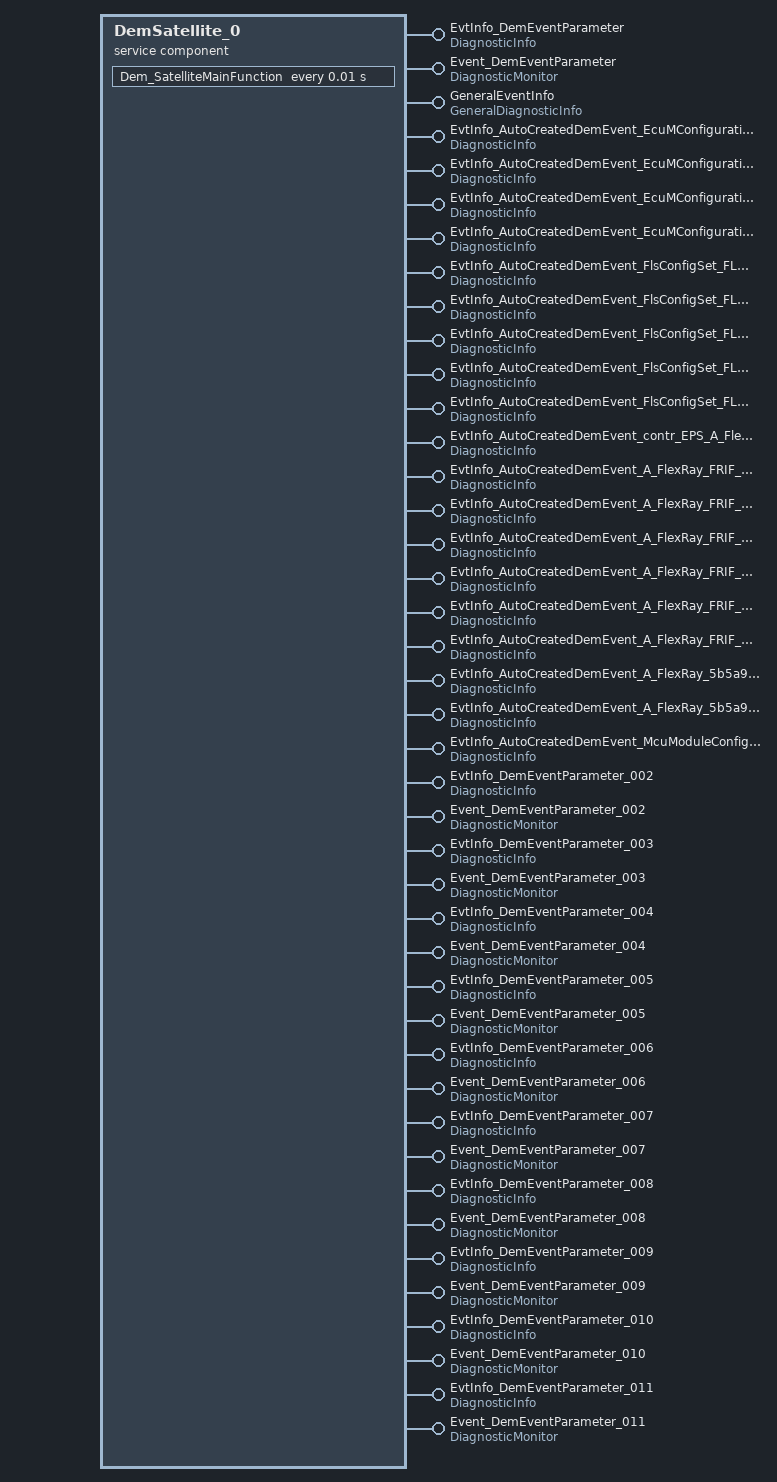
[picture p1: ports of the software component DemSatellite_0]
  service sw component type DemSatellite_0: category=SERVICE_COMPONENT
    42 x provide port:
      EvtInfo_DemEventParameter: provided-interface=DiagnosticInfo
      Event_DemEventParameter: provided-interface=DiagnosticMonitor
      GeneralEventInfo: provided-interface=GeneralDiagnosticInfo
      EvtInfo_AutoCreatedDemEvent_EcuMConfiguration_ECUM_E_ALL_RUN_REQUESTS_KILLED: provided-interface=DiagnosticInfo
      EvtInfo_AutoCreatedDemEvent_EcuMConfiguration_ECUM_E_CONFIGURATION_DATA_INCONSISTENT: provided-interface=DiagnosticInfo
      EvtInfo_AutoCreatedDemEvent_EcuMConfiguration_ECUM_E_RAM_CHECK_FAILED: provided-interface=DiagnosticInfo
      EvtInfo_AutoCreatedDemEvent_EcuMConfiguration_ECUM_E_IMPROPER_CALLER: provided-interface=DiagnosticInfo
      EvtInfo_AutoCreatedDemEvent_FlsConfigSet_FLS_E_COMPARE_FAILED: provided-interface=DiagnosticInfo
      EvtInfo_AutoCreatedDemEvent_FlsConfigSet_FLS_E_ERASE_FAILED: provided-interface=DiagnosticInfo
      EvtInfo_AutoCreatedDemEvent_FlsConfigSet_FLS_E_READ_FAILED: provided-interface=DiagnosticInfo
      EvtInfo_AutoCreatedDemEvent_FlsConfigSet_FLS_E_UNEXPECTED_FLASH_ID: provided-interface=DiagnosticInfo
      EvtInfo_AutoCreatedDemEvent_FlsConfigSet_FLS_E_WRITE_FAILED: provided-interface=DiagnosticInfo
      EvtInfo_AutoCreatedDemEvent_contr_EPS_A_FlexRay_FrDemCtrlTestResultRef: provided-interface=DiagnosticInfo
      EvtInfo_AutoCreatedDemEvent_A_FlexRay_FRIF_E_ACS_CH_A: provided-interface=DiagnosticInfo
      EvtInfo_AutoCreatedDemEvent_A_FlexRay_FRIF_E_ACS_CH_B: provided-interface=DiagnosticInfo
      EvtInfo_AutoCreatedDemEvent_A_FlexRay_FRIF_E_NIT_CH_A: provided-interface=DiagnosticInfo
      EvtInfo_AutoCreatedDemEvent_A_FlexRay_FRIF_E_NIT_CH_B: provided-interface=DiagnosticInfo
      EvtInfo_AutoCreatedDemEvent_A_FlexRay_FRIF_E_SW_CH_A: provided-interface=DiagnosticInfo
      EvtInfo_AutoCreatedDemEvent_A_FlexRay_FRIF_E_SW_CH_B: provided-interface=DiagnosticInfo
      EvtInfo_AutoCreatedDemEvent_A_FlexRay_5b5a9ac2_FRSM_E_CLUSTER_STARTUP: provided-interface=DiagnosticInfo
      EvtInfo_AutoCreatedDemEvent_A_FlexRay_5b5a9ac2_FRSM_E_CLUSTER_SYNC_LOSS: provided-interface=DiagnosticInfo
      EvtInfo_AutoCreatedDemEvent_McuModuleConfiguration_MCU_E_CLOCK_FAILURE: provided-interface=DiagnosticInfo
      EvtInfo_DemEventParameter_002: provided-interface=DiagnosticInfo
      Event_DemEventParameter_002: provided-interface=DiagnosticMonitor
      EvtInfo_DemEventParameter_003: provided-interface=DiagnosticInfo
      Event_DemEventParameter_003: provided-interface=DiagnosticMonitor
      EvtInfo_DemEventParameter_004: provided-interface=DiagnosticInfo
      Event_DemEventParameter_004: provided-interface=DiagnosticMonitor
      EvtInfo_DemEventParameter_005: provided-interface=DiagnosticInfo
      Event_DemEventParameter_005: provided-interface=DiagnosticMonitor
      EvtInfo_DemEventParameter_006: provided-interface=DiagnosticInfo
      Event_DemEventParameter_006: provided-interface=DiagnosticMonitor
      EvtInfo_DemEventParameter_007: provided-interface=DiagnosticInfo
      Event_DemEventParameter_007: provided-interface=DiagnosticMonitor
      EvtInfo_DemEventParameter_008: provided-interface=DiagnosticInfo
      Event_DemEventParameter_008: provided-interface=DiagnosticMonitor
      EvtInfo_DemEventParameter_009: provided-interface=DiagnosticInfo
      Event_DemEventParameter_009: provided-interface=DiagnosticMonitor
      EvtInfo_DemEventParameter_010: provided-interface=DiagnosticInfo
      Event_DemEventParameter_010: provided-interface=DiagnosticMonitor
      EvtInfo_DemEventParameter_011: provided-interface=DiagnosticInfo
      Event_DemEventParameter_011: provided-interface=DiagnosticMonitor
    behavior DemSatellite_0InternalBehavior: handle-termination-and-restart=NO-SUPPORT, included-data-type-set=data-type=[Dem_EventIdType, Dem_RatioIdType, Dem_EventStatusType, Dem_UdsStatusByteType, Dem_DTCFormatType, Dem_InitMonitorReasonType, Dem_OperationCycleStateType, Dem_DTCStatusMaskType, Dem_IndicatorStatusType, Dem_MaxDataValueType, Dem_DTCKindType, Dem_DTCGroupType, Dem_IumprDenomCondIdType, Dem_IumprDenomCondStatusType, Dem_DebounceResetStatusType, Dem_DebouncingStateType, Dem_IumprReadinessGroupType, Dem_DTRControlType, Dem_DTCSeverityType, Dem_MonitorStatusType]
      timing event Timer_Dem_SatelliteMainFunction: start-on-event=Dem_SatelliteMainFunction, period=0.01
      462 x operation invoked event:
        OpEventGetEventUdsStatus_GetEventUdsStatus_EvtInfo_DemEventParameter: start-on-event=DemSatellite_0InternalBehavior/GetEventUdsStatus, operation=EvtInfo_DemEventParameter.GetEventUdsStatus
        OpEventGetEventUdsStatus_GetEventUdsStatus_Event_DemEventParameter: start-on-event=DemSatellite_0InternalBehavior/GetEventUdsStatus, operation=Event_DemEventParameter.GetEventUdsStatus
        OpEventGetEventUdsStatus_GetEventUdsStatus_GeneralEventInfo: start-on-event=DemSatellite_0InternalBehavior/GetEventUdsStatus, operation=GeneralEventInfo.GetEventUdsStatus
        OpEventGetEventStatus_GetEventStatus_EvtInfo_DemEventParameter: start-on-event=DemSatellite_0InternalBehavior/GetEventStatus, operation=EvtInfo_DemEventParameter.GetEventStatus
        OpEventGetEventStatus_GetEventStatus_Event_DemEventParameter: start-on-event=DemSatellite_0InternalBehavior/GetEventStatus, operation=Event_DemEventParameter.GetEventStatus
        OpEventGetEventStatus_GetEventStatus_GeneralEventInfo: start-on-event=DemSatellite_0InternalBehavior/GetEventStatus, operation=GeneralEventInfo.GetEventStatus
        OpEventGetEventFailed_GetEventFailed_EvtInfo_DemEventParameter: start-on-event=DemSatellite_0InternalBehavior/GetEventFailed, operation=EvtInfo_DemEventParameter.GetEventFailed
        OpEventGetEventFailed_GetEventFailed_Event_DemEventParameter: start-on-event=DemSatellite_0InternalBehavior/GetEventFailed, operation=Event_DemEventParameter.GetEventFailed
        OpEventGetEventFailed_GetEventFailed_GeneralEventInfo: start-on-event=DemSatellite_0InternalBehavior/GetEventFailed, operation=GeneralEventInfo.GetEventFailed
        OpEventGetEventTested_GetEventTested_EvtInfo_DemEventParameter: start-on-event=DemSatellite_0InternalBehavior/GetEventTested, operation=EvtInfo_DemEventParameter.GetEventTested
        OpEventGetEventTested_GetEventTested_Event_DemEventParameter: start-on-event=DemSatellite_0InternalBehavior/GetEventTested, operation=Event_DemEventParameter.GetEventTested
        OpEventGetEventTested_GetEventTested_GeneralEventInfo: start-on-event=DemSatellite_0InternalBehavior/GetEventTested, operation=GeneralEventInfo.GetEventTested
        OpEventGetDTCOfEvent_GetDTCOfEvent_EvtInfo_DemEventParameter: start-on-event=DemSatellite_0InternalBehavior/GetDTCOfEvent, operation=EvtInfo_DemEventParameter.GetDTCOfEvent
        OpEventGetDTCOfEvent_GetDTCOfEvent_Event_DemEventParameter: start-on-event=DemSatellite_0InternalBehavior/GetDTCOfEvent, operation=Event_DemEventParameter.GetDTCOfEvent
        OpEventGetDTCOfEvent_GetDTCOfEvent_GeneralEventInfo: start-on-event=DemSatellite_0InternalBehavior/GetDTCOfEvent, operation=GeneralEventInfo.GetDTCOfEvent
        OpEventGetFaultDetectionCounter_GetFaultDetectionCounter_EvtInfo_DemEventParameter: start-on-event=DemSatellite_0InternalBehavior/GetFaultDetectionCounter, operation=EvtInfo_DemEventParameter.GetFaultDetectionCounter
        OpEventGetFaultDetectionCounter_GetFaultDetectionCounter_Event_DemEventParameter: start-on-event=DemSatellite_0InternalBehavior/GetFaultDetectionCounter, operation=Event_DemEventParameter.GetFaultDetectionCounter
        OpEventGetFaultDetectionCounter_GetFaultDetectionCounter_GeneralEventInfo: start-on-event=DemSatellite_0InternalBehavior/GetFaultDetectionCounter, operation=GeneralEventInfo.GetFaultDetectionCounter
        OpEventGetEventFreezeFrameDataEx_GetEventFreezeFrameDataEx_EvtInfo_DemEventParameter: start-on-event=DemSatellite_0InternalBehavior/GetEventFreezeFrameDataEx, operation=EvtInfo_DemEventParameter.GetEventFreezeFrameDataEx
        OpEventGetEventFreezeFrameDataEx_GetEventFreezeFrameDataEx_Event_DemEventParameter: start-on-event=DemSatellite_0InternalBehavior/GetEventFreezeFrameDataEx, operation=Event_DemEventParameter.GetEventFreezeFrameDataEx
        OpEventGetEventFreezeFrameDataEx_GetEventFreezeFrameDataEx_GeneralEventInfo: start-on-event=DemSatellite_0InternalBehavior/GetEventFreezeFrameDataEx, operation=GeneralEventInfo.GetEventFreezeFrameDataEx
        OpEventGetEventExtendedDataRecordEx_GetEventExtendedDataRecordEx_EvtInfo_DemEventParameter: start-on-event=DemSatellite_0InternalBehavior/GetEventExtendedDataRecordEx, operation=EvtInfo_DemEventParameter.GetEventExtendedDataRecordEx
        OpEventGetEventExtendedDataRecordEx_GetEventExtendedDataRecordEx_Event_DemEventParameter: start-on-event=DemSatellite_0InternalBehavior/GetEventExtendedDataRecordEx, operation=Event_DemEventParameter.GetEventExtendedDataRecordEx
        OpEventGetEventExtendedDataRecordEx_GetEventExtendedDataRecordEx_GeneralEventInfo: start-on-event=DemSatellite_0InternalBehavior/GetEventExtendedDataRecordEx, operation=GeneralEventInfo.GetEventExtendedDataRecordEx
        OpEventGetEventEnableCondition_GetEventEnableCondition_EvtInfo_DemEventParameter: start-on-event=DemSatellite_0InternalBehavior/GetEventEnableCondition, operation=EvtInfo_DemEventParameter.GetEventEnableCondition
        OpEventGetEventEnableCondition_GetEventEnableCondition_GeneralEventInfo: start-on-event=DemSatellite_0InternalBehavior/GetEventEnableCondition, operation=GeneralEventInfo.GetEventEnableCondition
        OpEventGetDebouncingOfEvent_GetDebouncingOfEvent_EvtInfo_DemEventParameter: start-on-event=DemSatellite_0InternalBehavior/GetDebouncingOfEvent, operation=EvtInfo_DemEventParameter.GetDebouncingOfEvent
        OpEventGetDebouncingOfEvent_GetDebouncingOfEvent_GeneralEventInfo: start-on-event=DemSatellite_0InternalBehavior/GetDebouncingOfEvent, operation=GeneralEventInfo.GetDebouncingOfEvent
        OpEventGetMonitorStatus_GetMonitorStatus_EvtInfo_DemEventParameter: start-on-event=DemSatellite_0InternalBehavior/GetMonitorStatus, operation=EvtInfo_DemEventParameter.GetMonitorStatus
        OpEventGetMonitorStatus_GetMonitorStatus_GeneralEventInfo: start-on-event=DemSatellite_0InternalBehavior/GetMonitorStatus, operation=GeneralEventInfo.GetMonitorStatus
        OpEventSetEventStatus_SetEventStatus_Event_DemEventParameter: start-on-event=SetEventStatus, operation=Event_DemEventParameter.SetEventStatus
        OpEventResetEventStatus_ResetEventStatus_Event_DemEventParameter: start-on-event=ResetEventStatus, operation=Event_DemEventParameter.ResetEventStatus
        OpEventResetEventDebounceStatus_ResetEventDebounceStatus_Event_DemEventParameter: start-on-event=ResetEventDebounceStatus, operation=Event_DemEventParameter.ResetEventDebounceStatus
        OpEventGetEventUdsStatus_GetEventUdsStatus_EvtInfo_AutoCreatedDemEvent_EcuMConfiguration_ECUM_E_ALL_RUN_REQUESTS_KILLED: start-on-event=DemSatellite_0InternalBehavior/GetEventUdsStatus, operation=EvtInfo_AutoCreatedDemEvent_EcuMConfiguration_ECUM_E_ALL_RUN_REQUESTS_KILLED.GetEventUdsStatus
        OpEventGetEventUdsStatus_GetEventUdsStatus_EvtInfo_AutoCreatedDemEvent_EcuMConfiguration_ECUM_E_CONFIGURATION_DATA_INCONSISTENT: start-on-event=DemSatellite_0InternalBehavior/GetEventUdsStatus, operation=EvtInfo_AutoCreatedDemEvent_EcuMConfiguration_ECUM_E_CONFIGURATION_DATA_INCONSISTENT.GetEventUdsStatus
        OpEventGetEventUdsStatus_GetEventUdsStatus_EvtInfo_AutoCreatedDemEvent_EcuMConfiguration_ECUM_E_RAM_CHECK_FAILED: start-on-event=DemSatellite_0InternalBehavior/GetEventUdsStatus, operation=EvtInfo_AutoCreatedDemEvent_EcuMConfiguration_ECUM_E_RAM_CHECK_FAILED.GetEventUdsStatus
        OpEventGetEventUdsStatus_GetEventUdsStatus_EvtInfo_AutoCreatedDemEvent_EcuMConfiguration_ECUM_E_IMPROPER_CALLER: start-on-event=DemSatellite_0InternalBehavior/GetEventUdsStatus, operation=EvtInfo_AutoCreatedDemEvent_EcuMConfiguration_ECUM_E_IMPROPER_CALLER.GetEventUdsStatus
        OpEventGetEventUdsStatus_GetEventUdsStatus_EvtInfo_AutoCreatedDemEvent_FlsConfigSet_FLS_E_COMPARE_FAILED: start-on-event=DemSatellite_0InternalBehavior/GetEventUdsStatus, operation=EvtInfo_AutoCreatedDemEvent_FlsConfigSet_FLS_E_COMPARE_FAILED.GetEventUdsStatus
        OpEventGetEventUdsStatus_GetEventUdsStatus_EvtInfo_AutoCreatedDemEvent_FlsConfigSet_FLS_E_ERASE_FAILED: start-on-event=DemSatellite_0InternalBehavior/GetEventUdsStatus, operation=EvtInfo_AutoCreatedDemEvent_FlsConfigSet_FLS_E_ERASE_FAILED.GetEventUdsStatus
        OpEventGetEventUdsStatus_GetEventUdsStatus_EvtInfo_AutoCreatedDemEvent_FlsConfigSet_FLS_E_READ_FAILED: start-on-event=DemSatellite_0InternalBehavior/GetEventUdsStatus, operation=EvtInfo_AutoCreatedDemEvent_FlsConfigSet_FLS_E_READ_FAILED.GetEventUdsStatus
        OpEventGetEventUdsStatus_GetEventUdsStatus_EvtInfo_AutoCreatedDemEvent_FlsConfigSet_FLS_E_UNEXPECTED_FLASH_ID: start-on-event=DemSatellite_0InternalBehavior/GetEventUdsStatus, operation=EvtInfo_AutoCreatedDemEvent_FlsConfigSet_FLS_E_UNEXPECTED_FLASH_ID.GetEventUdsStatus
        OpEventGetEventUdsStatus_GetEventUdsStatus_EvtInfo_AutoCreatedDemEvent_FlsConfigSet_FLS_E_WRITE_FAILED: start-on-event=DemSatellite_0InternalBehavior/GetEventUdsStatus, operation=EvtInfo_AutoCreatedDemEvent_FlsConfigSet_FLS_E_WRITE_FAILED.GetEventUdsStatus
        OpEventGetEventUdsStatus_GetEventUdsStatus_EvtInfo_AutoCreatedDemEvent_contr_EPS_A_FlexRay_FrDemCtrlTestResultRef: start-on-event=DemSatellite_0InternalBehavior/GetEventUdsStatus, operation=EvtInfo_AutoCreatedDemEvent_contr_EPS_A_FlexRay_FrDemCtrlTestResultRef.GetEventUdsStatus
        OpEventGetEventUdsStatus_GetEventUdsStatus_EvtInfo_AutoCreatedDemEvent_A_FlexRay_FRIF_E_ACS_CH_A: start-on-event=DemSatellite_0InternalBehavior/GetEventUdsStatus, operation=EvtInfo_AutoCreatedDemEvent_A_FlexRay_FRIF_E_ACS_CH_A.GetEventUdsStatus
        OpEventGetEventUdsStatus_GetEventUdsStatus_EvtInfo_AutoCreatedDemEvent_A_FlexRay_FRIF_E_ACS_CH_B: start-on-event=DemSatellite_0InternalBehavior/GetEventUdsStatus, operation=EvtInfo_AutoCreatedDemEvent_A_FlexRay_FRIF_E_ACS_CH_B.GetEventUdsStatus
        OpEventGetEventUdsStatus_GetEventUdsStatus_EvtInfo_AutoCreatedDemEvent_A_FlexRay_FRIF_E_NIT_CH_A: start-on-event=DemSatellite_0InternalBehavior/GetEventUdsStatus, operation=EvtInfo_AutoCreatedDemEvent_A_FlexRay_FRIF_E_NIT_CH_A.GetEventUdsStatus
        OpEventGetEventUdsStatus_GetEventUdsStatus_EvtInfo_AutoCreatedDemEvent_A_FlexRay_FRIF_E_NIT_CH_B: start-on-event=DemSatellite_0InternalBehavior/GetEventUdsStatus, operation=EvtInfo_AutoCreatedDemEvent_A_FlexRay_FRIF_E_NIT_CH_B.GetEventUdsStatus
        OpEventGetEventUdsStatus_GetEventUdsStatus_EvtInfo_AutoCreatedDemEvent_A_FlexRay_FRIF_E_SW_CH_A: start-on-event=DemSatellite_0InternalBehavior/GetEventUdsStatus, operation=EvtInfo_AutoCreatedDemEvent_A_FlexRay_FRIF_E_SW_CH_A.GetEventUdsStatus
        OpEventGetEventUdsStatus_GetEventUdsStatus_EvtInfo_AutoCreatedDemEvent_A_FlexRay_FRIF_E_SW_CH_B: start-on-event=DemSatellite_0InternalBehavior/GetEventUdsStatus, operation=EvtInfo_AutoCreatedDemEvent_A_FlexRay_FRIF_E_SW_CH_B.GetEventUdsStatus
        OpEventGetEventUdsStatus_GetEventUdsStatus_EvtInfo_AutoCreatedDemEvent_A_FlexRay_5b5a9ac2_FRSM_E_CLUSTER_STARTUP: start-on-event=DemSatellite_0InternalBehavior/GetEventUdsStatus, operation=EvtInfo_AutoCreatedDemEvent_A_FlexRay_5b5a9ac2_FRSM_E_CLUSTER_STARTUP.GetEventUdsStatus
        OpEventGetEventUdsStatus_GetEventUdsStatus_EvtInfo_AutoCreatedDemEvent_A_FlexRay_5b5a9ac2_FRSM_E_CLUSTER_SYNC_LOSS: start-on-event=DemSatellite_0InternalBehavior/GetEventUdsStatus, operation=EvtInfo_AutoCreatedDemEvent_A_FlexRay_5b5a9ac2_FRSM_E_CLUSTER_SYNC_LOSS.GetEventUdsStatus
        OpEventGetEventUdsStatus_GetEventUdsStatus_EvtInfo_AutoCreatedDemEvent_McuModuleConfiguration_MCU_E_CLOCK_FAILURE: start-on-event=DemSatellite_0InternalBehavior/GetEventUdsStatus, operation=EvtInfo_AutoCreatedDemEvent_McuModuleConfiguration_MCU_E_CLOCK_FAILURE.GetEventUdsStatus
        OpEventGetEventStatus_GetEventStatus_EvtInfo_AutoCreatedDemEvent_EcuMConfiguration_ECUM_E_ALL_RUN_REQUESTS_KILLED: start-on-event=DemSatellite_0InternalBehavior/GetEventStatus, operation=EvtInfo_AutoCreatedDemEvent_EcuMConfiguration_ECUM_E_ALL_RUN_REQUESTS_KILLED.GetEventStatus
        OpEventGetEventStatus_GetEventStatus_EvtInfo_AutoCreatedDemEvent_EcuMConfiguration_ECUM_E_CONFIGURATION_DATA_INCONSISTENT: start-on-event=DemSatellite_0InternalBehavior/GetEventStatus, operation=EvtInfo_AutoCreatedDemEvent_EcuMConfiguration_ECUM_E_CONFIGURATION_DATA_INCONSISTENT.GetEventStatus
        OpEventGetEventStatus_GetEventStatus_EvtInfo_AutoCreatedDemEvent_EcuMConfiguration_ECUM_E_RAM_CHECK_FAILED: start-on-event=DemSatellite_0InternalBehavior/GetEventStatus, operation=EvtInfo_AutoCreatedDemEvent_EcuMConfiguration_ECUM_E_RAM_CHECK_FAILED.GetEventStatus
        OpEventGetEventStatus_GetEventStatus_EvtInfo_AutoCreatedDemEvent_EcuMConfiguration_ECUM_E_IMPROPER_CALLER: start-on-event=DemSatellite_0InternalBehavior/GetEventStatus, operation=EvtInfo_AutoCreatedDemEvent_EcuMConfiguration_ECUM_E_IMPROPER_CALLER.GetEventStatus
        OpEventGetEventStatus_GetEventStatus_EvtInfo_AutoCreatedDemEvent_FlsConfigSet_FLS_E_COMPARE_FAILED: start-on-event=DemSatellite_0InternalBehavior/GetEventStatus, operation=EvtInfo_AutoCreatedDemEvent_FlsConfigSet_FLS_E_COMPARE_FAILED.GetEventStatus
        OpEventGetEventStatus_GetEventStatus_EvtInfo_AutoCreatedDemEvent_FlsConfigSet_FLS_E_ERASE_FAILED: start-on-event=DemSatellite_0InternalBehavior/GetEventStatus, operation=EvtInfo_AutoCreatedDemEvent_FlsConfigSet_FLS_E_ERASE_FAILED.GetEventStatus
        OpEventGetEventStatus_GetEventStatus_EvtInfo_AutoCreatedDemEvent_FlsConfigSet_FLS_E_READ_FAILED: start-on-event=DemSatellite_0InternalBehavior/GetEventStatus, operation=EvtInfo_AutoCreatedDemEvent_FlsConfigSet_FLS_E_READ_FAILED.GetEventStatus
        OpEventGetEventStatus_GetEventStatus_EvtInfo_AutoCreatedDemEvent_FlsConfigSet_FLS_E_UNEXPECTED_FLASH_ID: start-on-event=DemSatellite_0InternalBehavior/GetEventStatus, operation=EvtInfo_AutoCreatedDemEvent_FlsConfigSet_FLS_E_UNEXPECTED_FLASH_ID.GetEventStatus
        OpEventGetEventStatus_GetEventStatus_EvtInfo_AutoCreatedDemEvent_FlsConfigSet_FLS_E_WRITE_FAILED: start-on-event=DemSatellite_0InternalBehavior/GetEventStatus, operation=EvtInfo_AutoCreatedDemEvent_FlsConfigSet_FLS_E_WRITE_FAILED.GetEventStatus
        OpEventGetEventStatus_GetEventStatus_EvtInfo_AutoCreatedDemEvent_contr_EPS_A_FlexRay_FrDemCtrlTestResultRef: start-on-event=DemSatellite_0InternalBehavior/GetEventStatus, operation=EvtInfo_AutoCreatedDemEvent_contr_EPS_A_FlexRay_FrDemCtrlTestResultRef.GetEventStatus
        OpEventGetEventStatus_GetEventStatus_EvtInfo_AutoCreatedDemEvent_A_FlexRay_FRIF_E_ACS_CH_A: start-on-event=DemSatellite_0InternalBehavior/GetEventStatus, operation=EvtInfo_AutoCreatedDemEvent_A_FlexRay_FRIF_E_ACS_CH_A.GetEventStatus
        OpEventGetEventStatus_GetEventStatus_EvtInfo_AutoCreatedDemEvent_A_FlexRay_FRIF_E_ACS_CH_B: start-on-event=DemSatellite_0InternalBehavior/GetEventStatus, operation=EvtInfo_AutoCreatedDemEvent_A_FlexRay_FRIF_E_ACS_CH_B.GetEventStatus
        OpEventGetEventStatus_GetEventStatus_EvtInfo_AutoCreatedDemEvent_A_FlexRay_FRIF_E_NIT_CH_A: start-on-event=DemSatellite_0InternalBehavior/GetEventStatus, operation=EvtInfo_AutoCreatedDemEvent_A_FlexRay_FRIF_E_NIT_CH_A.GetEventStatus
        OpEventGetEventStatus_GetEventStatus_EvtInfo_AutoCreatedDemEvent_A_FlexRay_FRIF_E_NIT_CH_B: start-on-event=DemSatellite_0InternalBehavior/GetEventStatus, operation=EvtInfo_AutoCreatedDemEvent_A_FlexRay_FRIF_E_NIT_CH_B.GetEventStatus
        OpEventGetEventStatus_GetEventStatus_EvtInfo_AutoCreatedDemEvent_A_FlexRay_FRIF_E_SW_CH_A: start-on-event=DemSatellite_0InternalBehavior/GetEventStatus, operation=EvtInfo_AutoCreatedDemEvent_A_FlexRay_FRIF_E_SW_CH_A.GetEventStatus
        OpEventGetEventStatus_GetEventStatus_EvtInfo_AutoCreatedDemEvent_A_FlexRay_FRIF_E_SW_CH_B: start-on-event=DemSatellite_0InternalBehavior/GetEventStatus, operation=EvtInfo_AutoCreatedDemEvent_A_FlexRay_FRIF_E_SW_CH_B.GetEventStatus
        OpEventGetEventStatus_GetEventStatus_EvtInfo_AutoCreatedDemEvent_A_FlexRay_5b5a9ac2_FRSM_E_CLUSTER_STARTUP: start-on-event=DemSatellite_0InternalBehavior/GetEventStatus, operation=EvtInfo_AutoCreatedDemEvent_A_FlexRay_5b5a9ac2_FRSM_E_CLUSTER_STARTUP.GetEventStatus
        OpEventGetEventStatus_GetEventStatus_EvtInfo_AutoCreatedDemEvent_A_FlexRay_5b5a9ac2_FRSM_E_CLUSTER_SYNC_LOSS: start-on-event=DemSatellite_0InternalBehavior/GetEventStatus, operation=EvtInfo_AutoCreatedDemEvent_A_FlexRay_5b5a9ac2_FRSM_E_CLUSTER_SYNC_LOSS.GetEventStatus
        OpEventGetEventStatus_GetEventStatus_EvtInfo_AutoCreatedDemEvent_McuModuleConfiguration_MCU_E_CLOCK_FAILURE: start-on-event=DemSatellite_0InternalBehavior/GetEventStatus, operation=EvtInfo_AutoCreatedDemEvent_McuModuleConfiguration_MCU_E_CLOCK_FAILURE.GetEventStatus
        OpEventGetEventFailed_GetEventFailed_EvtInfo_AutoCreatedDemEvent_EcuMConfiguration_ECUM_E_ALL_RUN_REQUESTS_KILLED: start-on-event=DemSatellite_0InternalBehavior/GetEventFailed, operation=EvtInfo_AutoCreatedDemEvent_EcuMConfiguration_ECUM_E_ALL_RUN_REQUESTS_KILLED.GetEventFailed
        OpEventGetEventFailed_GetEventFailed_EvtInfo_AutoCreatedDemEvent_EcuMConfiguration_ECUM_E_CONFIGURATION_DATA_INCONSISTENT: start-on-event=DemSatellite_0InternalBehavior/GetEventFailed, operation=EvtInfo_AutoCreatedDemEvent_EcuMConfiguration_ECUM_E_CONFIGURATION_DATA_INCONSISTENT.GetEventFailed
        OpEventGetEventFailed_GetEventFailed_EvtInfo_AutoCreatedDemEvent_EcuMConfiguration_ECUM_E_RAM_CHECK_FAILED: start-on-event=DemSatellite_0InternalBehavior/GetEventFailed, operation=EvtInfo_AutoCreatedDemEvent_EcuMConfiguration_ECUM_E_RAM_CHECK_FAILED.GetEventFailed
        OpEventGetEventFailed_GetEventFailed_EvtInfo_AutoCreatedDemEvent_EcuMConfiguration_ECUM_E_IMPROPER_CALLER: start-on-event=DemSatellite_0InternalBehavior/GetEventFailed, operation=EvtInfo_AutoCreatedDemEvent_EcuMConfiguration_ECUM_E_IMPROPER_CALLER.GetEventFailed
        OpEventGetEventFailed_GetEventFailed_EvtInfo_AutoCreatedDemEvent_FlsConfigSet_FLS_E_COMPARE_FAILED: start-on-event=DemSatellite_0InternalBehavior/GetEventFailed, operation=EvtInfo_AutoCreatedDemEvent_FlsConfigSet_FLS_E_COMPARE_FAILED.GetEventFailed
        OpEventGetEventFailed_GetEventFailed_EvtInfo_AutoCreatedDemEvent_FlsConfigSet_FLS_E_ERASE_FAILED: start-on-event=DemSatellite_0InternalBehavior/GetEventFailed, operation=EvtInfo_AutoCreatedDemEvent_FlsConfigSet_FLS_E_ERASE_FAILED.GetEventFailed
        OpEventGetEventFailed_GetEventFailed_EvtInfo_AutoCreatedDemEvent_FlsConfigSet_FLS_E_READ_FAILED: start-on-event=DemSatellite_0InternalBehavior/GetEventFailed, operation=EvtInfo_AutoCreatedDemEvent_FlsConfigSet_FLS_E_READ_FAILED.GetEventFailed
        OpEventGetEventFailed_GetEventFailed_EvtInfo_AutoCreatedDemEvent_FlsConfigSet_FLS_E_UNEXPECTED_FLASH_ID: start-on-event=DemSatellite_0InternalBehavior/GetEventFailed, operation=EvtInfo_AutoCreatedDemEvent_FlsConfigSet_FLS_E_UNEXPECTED_FLASH_ID.GetEventFailed
        OpEventGetEventFailed_GetEventFailed_EvtInfo_AutoCreatedDemEvent_FlsConfigSet_FLS_E_WRITE_FAILED: start-on-event=DemSatellite_0InternalBehavior/GetEventFailed, operation=EvtInfo_AutoCreatedDemEvent_FlsConfigSet_FLS_E_WRITE_FAILED.GetEventFailed
        OpEventGetEventFailed_GetEventFailed_EvtInfo_AutoCreatedDemEvent_contr_EPS_A_FlexRay_FrDemCtrlTestResultRef: start-on-event=DemSatellite_0InternalBehavior/GetEventFailed, operation=EvtInfo_AutoCreatedDemEvent_contr_EPS_A_FlexRay_FrDemCtrlTestResultRef.GetEventFailed
        OpEventGetEventFailed_GetEventFailed_EvtInfo_AutoCreatedDemEvent_A_FlexRay_FRIF_E_ACS_CH_A: start-on-event=DemSatellite_0InternalBehavior/GetEventFailed, operation=EvtInfo_AutoCreatedDemEvent_A_FlexRay_FRIF_E_ACS_CH_A.GetEventFailed
        OpEventGetEventFailed_GetEventFailed_EvtInfo_AutoCreatedDemEvent_A_FlexRay_FRIF_E_ACS_CH_B: start-on-event=DemSatellite_0InternalBehavior/GetEventFailed, operation=EvtInfo_AutoCreatedDemEvent_A_FlexRay_FRIF_E_ACS_CH_B.GetEventFailed
        OpEventGetEventFailed_GetEventFailed_EvtInfo_AutoCreatedDemEvent_A_FlexRay_FRIF_E_NIT_CH_A: start-on-event=DemSatellite_0InternalBehavior/GetEventFailed, operation=EvtInfo_AutoCreatedDemEvent_A_FlexRay_FRIF_E_NIT_CH_A.GetEventFailed
        OpEventGetEventFailed_GetEventFailed_EvtInfo_AutoCreatedDemEvent_A_FlexRay_FRIF_E_NIT_CH_B: start-on-event=DemSatellite_0InternalBehavior/GetEventFailed, operation=EvtInfo_AutoCreatedDemEvent_A_FlexRay_FRIF_E_NIT_CH_B.GetEventFailed
        OpEventGetEventFailed_GetEventFailed_EvtInfo_AutoCreatedDemEvent_A_FlexRay_FRIF_E_SW_CH_A: start-on-event=DemSatellite_0InternalBehavior/GetEventFailed, operation=EvtInfo_AutoCreatedDemEvent_A_FlexRay_FRIF_E_SW_CH_A.GetEventFailed
        OpEventGetEventFailed_GetEventFailed_EvtInfo_AutoCreatedDemEvent_A_FlexRay_FRIF_E_SW_CH_B: start-on-event=DemSatellite_0InternalBehavior/GetEventFailed, operation=EvtInfo_AutoCreatedDemEvent_A_FlexRay_FRIF_E_SW_CH_B.GetEventFailed
        OpEventGetEventFailed_GetEventFailed_EvtInfo_AutoCreatedDemEvent_A_FlexRay_5b5a9ac2_FRSM_E_CLUSTER_STARTUP: start-on-event=DemSatellite_0InternalBehavior/GetEventFailed, operation=EvtInfo_AutoCreatedDemEvent_A_FlexRay_5b5a9ac2_FRSM_E_CLUSTER_STARTUP.GetEventFailed
        OpEventGetEventFailed_GetEventFailed_EvtInfo_AutoCreatedDemEvent_A_FlexRay_5b5a9ac2_FRSM_E_CLUSTER_SYNC_LOSS: start-on-event=DemSatellite_0InternalBehavior/GetEventFailed, operation=EvtInfo_AutoCreatedDemEvent_A_FlexRay_5b5a9ac2_FRSM_E_CLUSTER_SYNC_LOSS.GetEventFailed
        OpEventGetEventFailed_GetEventFailed_EvtInfo_AutoCreatedDemEvent_McuModuleConfiguration_MCU_E_CLOCK_FAILURE: start-on-event=DemSatellite_0InternalBehavior/GetEventFailed, operation=EvtInfo_AutoCreatedDemEvent_McuModuleConfiguration_MCU_E_CLOCK_FAILURE.GetEventFailed
        OpEventGetEventTested_GetEventTested_EvtInfo_AutoCreatedDemEvent_EcuMConfiguration_ECUM_E_ALL_RUN_REQUESTS_KILLED: start-on-event=DemSatellite_0InternalBehavior/GetEventTested, operation=EvtInfo_AutoCreatedDemEvent_EcuMConfiguration_ECUM_E_ALL_RUN_REQUESTS_KILLED.GetEventTested
        OpEventGetEventTested_GetEventTested_EvtInfo_AutoCreatedDemEvent_EcuMConfiguration_ECUM_E_CONFIGURATION_DATA_INCONSISTENT: start-on-event=DemSatellite_0InternalBehavior/GetEventTested, operation=EvtInfo_AutoCreatedDemEvent_EcuMConfiguration_ECUM_E_CONFIGURATION_DATA_INCONSISTENT.GetEventTested
        OpEventGetEventTested_GetEventTested_EvtInfo_AutoCreatedDemEvent_EcuMConfiguration_ECUM_E_RAM_CHECK_FAILED: start-on-event=DemSatellite_0InternalBehavior/GetEventTested, operation=EvtInfo_AutoCreatedDemEvent_EcuMConfiguration_ECUM_E_RAM_CHECK_FAILED.GetEventTested
        OpEventGetEventTested_GetEventTested_EvtInfo_AutoCreatedDemEvent_EcuMConfiguration_ECUM_E_IMPROPER_CALLER: start-on-event=DemSatellite_0InternalBehavior/GetEventTested, operation=EvtInfo_AutoCreatedDemEvent_EcuMConfiguration_ECUM_E_IMPROPER_CALLER.GetEventTested
        OpEventGetEventTested_GetEventTested_EvtInfo_AutoCreatedDemEvent_FlsConfigSet_FLS_E_COMPARE_FAILED: start-on-event=DemSatellite_0InternalBehavior/GetEventTested, operation=EvtInfo_AutoCreatedDemEvent_FlsConfigSet_FLS_E_COMPARE_FAILED.GetEventTested
        OpEventGetEventTested_GetEventTested_EvtInfo_AutoCreatedDemEvent_FlsConfigSet_FLS_E_ERASE_FAILED: start-on-event=DemSatellite_0InternalBehavior/GetEventTested, operation=EvtInfo_AutoCreatedDemEvent_FlsConfigSet_FLS_E_ERASE_FAILED.GetEventTested
        OpEventGetEventTested_GetEventTested_EvtInfo_AutoCreatedDemEvent_FlsConfigSet_FLS_E_READ_FAILED: start-on-event=DemSatellite_0InternalBehavior/GetEventTested, operation=EvtInfo_AutoCreatedDemEvent_FlsConfigSet_FLS_E_READ_FAILED.GetEventTested
        OpEventGetEventTested_GetEventTested_EvtInfo_AutoCreatedDemEvent_FlsConfigSet_FLS_E_UNEXPECTED_FLASH_ID: start-on-event=DemSatellite_0InternalBehavior/GetEventTested, operation=EvtInfo_AutoCreatedDemEvent_FlsConfigSet_FLS_E_UNEXPECTED_FLASH_ID.GetEventTested
        OpEventGetEventTested_GetEventTested_EvtInfo_AutoCreatedDemEvent_FlsConfigSet_FLS_E_WRITE_FAILED: start-on-event=DemSatellite_0InternalBehavior/GetEventTested, operation=EvtInfo_AutoCreatedDemEvent_FlsConfigSet_FLS_E_WRITE_FAILED.GetEventTested
        OpEventGetEventTested_GetEventTested_EvtInfo_AutoCreatedDemEvent_contr_EPS_A_FlexRay_FrDemCtrlTestResultRef: start-on-event=DemSatellite_0InternalBehavior/GetEventTested, operation=EvtInfo_AutoCreatedDemEvent_contr_EPS_A_FlexRay_FrDemCtrlTestResultRef.GetEventTested
        OpEventGetEventTested_GetEventTested_EvtInfo_AutoCreatedDemEvent_A_FlexRay_FRIF_E_ACS_CH_A: start-on-event=DemSatellite_0InternalBehavior/GetEventTested, operation=EvtInfo_AutoCreatedDemEvent_A_FlexRay_FRIF_E_ACS_CH_A.GetEventTested
        OpEventGetEventTested_GetEventTested_EvtInfo_AutoCreatedDemEvent_A_FlexRay_FRIF_E_ACS_CH_B: start-on-event=DemSatellite_0InternalBehavior/GetEventTested, operation=EvtInfo_AutoCreatedDemEvent_A_FlexRay_FRIF_E_ACS_CH_B.GetEventTested
        OpEventGetEventTested_GetEventTested_EvtInfo_AutoCreatedDemEvent_A_FlexRay_FRIF_E_NIT_CH_A: start-on-event=DemSatellite_0InternalBehavior/GetEventTested, operation=EvtInfo_AutoCreatedDemEvent_A_FlexRay_FRIF_E_NIT_CH_A.GetEventTested
        OpEventGetEventTested_GetEventTested_EvtInfo_AutoCreatedDemEvent_A_FlexRay_FRIF_E_NIT_CH_B: start-on-event=DemSatellite_0InternalBehavior/GetEventTested, operation=EvtInfo_AutoCreatedDemEvent_A_FlexRay_FRIF_E_NIT_CH_B.GetEventTested
        OpEventGetEventTested_GetEventTested_EvtInfo_AutoCreatedDemEvent_A_FlexRay_FRIF_E_SW_CH_A: start-on-event=DemSatellite_0InternalBehavior/GetEventTested, operation=EvtInfo_AutoCreatedDemEvent_A_FlexRay_FRIF_E_SW_CH_A.GetEventTested
        OpEventGetEventTested_GetEventTested_EvtInfo_AutoCreatedDemEvent_A_FlexRay_FRIF_E_SW_CH_B: start-on-event=DemSatellite_0InternalBehavior/GetEventTested, operation=EvtInfo_AutoCreatedDemEvent_A_FlexRay_FRIF_E_SW_CH_B.GetEventTested
        OpEventGetEventTested_GetEventTested_EvtInfo_AutoCreatedDemEvent_A_FlexRay_5b5a9ac2_FRSM_E_CLUSTER_STARTUP: start-on-event=DemSatellite_0InternalBehavior/GetEventTested, operation=EvtInfo_AutoCreatedDemEvent_A_FlexRay_5b5a9ac2_FRSM_E_CLUSTER_STARTUP.GetEventTested
        OpEventGetEventTested_GetEventTested_EvtInfo_AutoCreatedDemEvent_A_FlexRay_5b5a9ac2_FRSM_E_CLUSTER_SYNC_LOSS: start-on-event=DemSatellite_0InternalBehavior/GetEventTested, operation=EvtInfo_AutoCreatedDemEvent_A_FlexRay_5b5a9ac2_FRSM_E_CLUSTER_SYNC_LOSS.GetEventTested
        OpEventGetEventTested_GetEventTested_EvtInfo_AutoCreatedDemEvent_McuModuleConfiguration_MCU_E_CLOCK_FAILURE: start-on-event=DemSatellite_0InternalBehavior/GetEventTested, operation=EvtInfo_AutoCreatedDemEvent_McuModuleConfiguration_MCU_E_CLOCK_FAILURE.GetEventTested
        OpEventGetDTCOfEvent_GetDTCOfEvent_EvtInfo_AutoCreatedDemEvent_EcuMConfiguration_ECUM_E_ALL_RUN_REQUESTS_KILLED: start-on-event=DemSatellite_0InternalBehavior/GetDTCOfEvent, operation=EvtInfo_AutoCreatedDemEvent_EcuMConfiguration_ECUM_E_ALL_RUN_REQUESTS_KILLED.GetDTCOfEvent
        OpEventGetDTCOfEvent_GetDTCOfEvent_EvtInfo_AutoCreatedDemEvent_EcuMConfiguration_ECUM_E_CONFIGURATION_DATA_INCONSISTENT: start-on-event=DemSatellite_0InternalBehavior/GetDTCOfEvent, operation=EvtInfo_AutoCreatedDemEvent_EcuMConfiguration_ECUM_E_CONFIGURATION_DATA_INCONSISTENT.GetDTCOfEvent
        OpEventGetDTCOfEvent_GetDTCOfEvent_EvtInfo_AutoCreatedDemEvent_EcuMConfiguration_ECUM_E_RAM_CHECK_FAILED: start-on-event=DemSatellite_0InternalBehavior/GetDTCOfEvent, operation=EvtInfo_AutoCreatedDemEvent_EcuMConfiguration_ECUM_E_RAM_CHECK_FAILED.GetDTCOfEvent
        OpEventGetDTCOfEvent_GetDTCOfEvent_EvtInfo_AutoCreatedDemEvent_EcuMConfiguration_ECUM_E_IMPROPER_CALLER: start-on-event=DemSatellite_0InternalBehavior/GetDTCOfEvent, operation=EvtInfo_AutoCreatedDemEvent_EcuMConfiguration_ECUM_E_IMPROPER_CALLER.GetDTCOfEvent
        OpEventGetDTCOfEvent_GetDTCOfEvent_EvtInfo_AutoCreatedDemEvent_FlsConfigSet_FLS_E_COMPARE_FAILED: start-on-event=DemSatellite_0InternalBehavior/GetDTCOfEvent, operation=EvtInfo_AutoCreatedDemEvent_FlsConfigSet_FLS_E_COMPARE_FAILED.GetDTCOfEvent
        OpEventGetDTCOfEvent_GetDTCOfEvent_EvtInfo_AutoCreatedDemEvent_FlsConfigSet_FLS_E_ERASE_FAILED: start-on-event=DemSatellite_0InternalBehavior/GetDTCOfEvent, operation=EvtInfo_AutoCreatedDemEvent_FlsConfigSet_FLS_E_ERASE_FAILED.GetDTCOfEvent
        OpEventGetDTCOfEvent_GetDTCOfEvent_EvtInfo_AutoCreatedDemEvent_FlsConfigSet_FLS_E_READ_FAILED: start-on-event=DemSatellite_0InternalBehavior/GetDTCOfEvent, operation=EvtInfo_AutoCreatedDemEvent_FlsConfigSet_FLS_E_READ_FAILED.GetDTCOfEvent
        OpEventGetDTCOfEvent_GetDTCOfEvent_EvtInfo_AutoCreatedDemEvent_FlsConfigSet_FLS_E_UNEXPECTED_FLASH_ID: start-on-event=DemSatellite_0InternalBehavior/GetDTCOfEvent, operation=EvtInfo_AutoCreatedDemEvent_FlsConfigSet_FLS_E_UNEXPECTED_FLASH_ID.GetDTCOfEvent
        OpEventGetDTCOfEvent_GetDTCOfEvent_EvtInfo_AutoCreatedDemEvent_FlsConfigSet_FLS_E_WRITE_FAILED: start-on-event=DemSatellite_0InternalBehavior/GetDTCOfEvent, operation=EvtInfo_AutoCreatedDemEvent_FlsConfigSet_FLS_E_WRITE_FAILED.GetDTCOfEvent
        OpEventGetDTCOfEvent_GetDTCOfEvent_EvtInfo_AutoCreatedDemEvent_contr_EPS_A_FlexRay_FrDemCtrlTestResultRef: start-on-event=DemSatellite_0InternalBehavior/GetDTCOfEvent, operation=EvtInfo_AutoCreatedDemEvent_contr_EPS_A_FlexRay_FrDemCtrlTestResultRef.GetDTCOfEvent
        OpEventGetDTCOfEvent_GetDTCOfEvent_EvtInfo_AutoCreatedDemEvent_A_FlexRay_FRIF_E_ACS_CH_A: start-on-event=DemSatellite_0InternalBehavior/GetDTCOfEvent, operation=EvtInfo_AutoCreatedDemEvent_A_FlexRay_FRIF_E_ACS_CH_A.GetDTCOfEvent
        OpEventGetDTCOfEvent_GetDTCOfEvent_EvtInfo_AutoCreatedDemEvent_A_FlexRay_FRIF_E_ACS_CH_B: start-on-event=DemSatellite_0InternalBehavior/GetDTCOfEvent, operation=EvtInfo_AutoCreatedDemEvent_A_FlexRay_FRIF_E_ACS_CH_B.GetDTCOfEvent
        OpEventGetDTCOfEvent_GetDTCOfEvent_EvtInfo_AutoCreatedDemEvent_A_FlexRay_FRIF_E_NIT_CH_A: start-on-event=DemSatellite_0InternalBehavior/GetDTCOfEvent, operation=EvtInfo_AutoCreatedDemEvent_A_FlexRay_FRIF_E_NIT_CH_A.GetDTCOfEvent
        OpEventGetDTCOfEvent_GetDTCOfEvent_EvtInfo_AutoCreatedDemEvent_A_FlexRay_FRIF_E_NIT_CH_B: start-on-event=DemSatellite_0InternalBehavior/GetDTCOfEvent, operation=EvtInfo_AutoCreatedDemEvent_A_FlexRay_FRIF_E_NIT_CH_B.GetDTCOfEvent
        OpEventGetDTCOfEvent_GetDTCOfEvent_EvtInfo_AutoCreatedDemEvent_A_FlexRay_FRIF_E_SW_CH_A: start-on-event=DemSatellite_0InternalBehavior/GetDTCOfEvent, operation=EvtInfo_AutoCreatedDemEvent_A_FlexRay_FRIF_E_SW_CH_A.GetDTCOfEvent
        OpEventGetDTCOfEvent_GetDTCOfEvent_EvtInfo_AutoCreatedDemEvent_A_FlexRay_FRIF_E_SW_CH_B: start-on-event=DemSatellite_0InternalBehavior/GetDTCOfEvent, operation=EvtInfo_AutoCreatedDemEvent_A_FlexRay_FRIF_E_SW_CH_B.GetDTCOfEvent
        OpEventGetDTCOfEvent_GetDTCOfEvent_EvtInfo_AutoCreatedDemEvent_A_FlexRay_5b5a9ac2_FRSM_E_CLUSTER_STARTUP: start-on-event=DemSatellite_0InternalBehavior/GetDTCOfEvent, operation=EvtInfo_AutoCreatedDemEvent_A_FlexRay_5b5a9ac2_FRSM_E_CLUSTER_STARTUP.GetDTCOfEvent
        OpEventGetDTCOfEvent_GetDTCOfEvent_EvtInfo_AutoCreatedDemEvent_A_FlexRay_5b5a9ac2_FRSM_E_CLUSTER_SYNC_LOSS: start-on-event=DemSatellite_0InternalBehavior/GetDTCOfEvent, operation=EvtInfo_AutoCreatedDemEvent_A_FlexRay_5b5a9ac2_FRSM_E_CLUSTER_SYNC_LOSS.GetDTCOfEvent
        OpEventGetDTCOfEvent_GetDTCOfEvent_EvtInfo_AutoCreatedDemEvent_McuModuleConfiguration_MCU_E_CLOCK_FAILURE: start-on-event=DemSatellite_0InternalBehavior/GetDTCOfEvent, operation=EvtInfo_AutoCreatedDemEvent_McuModuleConfiguration_MCU_E_CLOCK_FAILURE.GetDTCOfEvent
        OpEventGetFaultDetectionCounter_GetFaultDetectionCounter_EvtInfo_AutoCreatedDemEvent_EcuMConfiguration_ECUM_E_ALL_RUN_R_5c1d7bad: start-on-event=DemSatellite_0InternalBehavior/GetFaultDetectionCounter, operation=EvtInfo_AutoCreatedDemEvent_EcuMConfiguration_ECUM_E_ALL_RUN_REQUESTS_KILLED.GetFaultDetectionCounter
        OpEventGetFaultDetectionCounter_GetFaultDetectionCounter_EvtInfo_AutoCreatedDemEvent_EcuMConfiguration_ECUM_E_CONFIGURA_55d3b4f6: start-on-event=DemSatellite_0InternalBehavior/GetFaultDetectionCounter, operation=EvtInfo_AutoCreatedDemEvent_EcuMConfiguration_ECUM_E_CONFIGURATION_DATA_INCONSISTENT.GetFaultDetectionCounter
        OpEventGetFaultDetectionCounter_GetFaultDetectionCounter_EvtInfo_AutoCreatedDemEvent_EcuMConfiguration_ECUM_E_RAM_CHECK_FAILED: start-on-event=DemSatellite_0InternalBehavior/GetFaultDetectionCounter, operation=EvtInfo_AutoCreatedDemEvent_EcuMConfiguration_ECUM_E_RAM_CHECK_FAILED.GetFaultDetectionCounter
        OpEventGetFaultDetectionCounter_GetFaultDetectionCounter_EvtInfo_AutoCreatedDemEvent_EcuMConfiguration_ECUM_E_IMPROPER_CALLER: start-on-event=DemSatellite_0InternalBehavior/GetFaultDetectionCounter, operation=EvtInfo_AutoCreatedDemEvent_EcuMConfiguration_ECUM_E_IMPROPER_CALLER.GetFaultDetectionCounter
        OpEventGetFaultDetectionCounter_GetFaultDetectionCounter_EvtInfo_AutoCreatedDemEvent_FlsConfigSet_FLS_E_COMPARE_FAILED: start-on-event=DemSatellite_0InternalBehavior/GetFaultDetectionCounter, operation=EvtInfo_AutoCreatedDemEvent_FlsConfigSet_FLS_E_COMPARE_FAILED.GetFaultDetectionCounter
        OpEventGetFaultDetectionCounter_GetFaultDetectionCounter_EvtInfo_AutoCreatedDemEvent_FlsConfigSet_FLS_E_ERASE_FAILED: start-on-event=DemSatellite_0InternalBehavior/GetFaultDetectionCounter, operation=EvtInfo_AutoCreatedDemEvent_FlsConfigSet_FLS_E_ERASE_FAILED.GetFaultDetectionCounter
        OpEventGetFaultDetectionCounter_GetFaultDetectionCounter_EvtInfo_AutoCreatedDemEvent_FlsConfigSet_FLS_E_READ_FAILED: start-on-event=DemSatellite_0InternalBehavior/GetFaultDetectionCounter, operation=EvtInfo_AutoCreatedDemEvent_FlsConfigSet_FLS_E_READ_FAILED.GetFaultDetectionCounter
        OpEventGetFaultDetectionCounter_GetFaultDetectionCounter_EvtInfo_AutoCreatedDemEvent_FlsConfigSet_FLS_E_UNEXPECTED_FLASH_ID: start-on-event=DemSatellite_0InternalBehavior/GetFaultDetectionCounter, operation=EvtInfo_AutoCreatedDemEvent_FlsConfigSet_FLS_E_UNEXPECTED_FLASH_ID.GetFaultDetectionCounter
        OpEventGetFaultDetectionCounter_GetFaultDetectionCounter_EvtInfo_AutoCreatedDemEvent_FlsConfigSet_FLS_E_WRITE_FAILED: start-on-event=DemSatellite_0InternalBehavior/GetFaultDetectionCounter, operation=EvtInfo_AutoCreatedDemEvent_FlsConfigSet_FLS_E_WRITE_FAILED.GetFaultDetectionCounter
        OpEventGetFaultDetectionCounter_GetFaultDetectionCounter_EvtInfo_AutoCreatedDemEvent_contr_EPS_A_FlexRay_FrDemCtrlTestResultRef: start-on-event=DemSatellite_0InternalBehavior/GetFaultDetectionCounter, operation=EvtInfo_AutoCreatedDemEvent_contr_EPS_A_FlexRay_FrDemCtrlTestResultRef.GetFaultDetectionCounter
        OpEventGetFaultDetectionCounter_GetFaultDetectionCounter_EvtInfo_AutoCreatedDemEvent_A_FlexRay_FRIF_E_ACS_CH_A: start-on-event=DemSatellite_0InternalBehavior/GetFaultDetectionCounter, operation=EvtInfo_AutoCreatedDemEvent_A_FlexRay_FRIF_E_ACS_CH_A.GetFaultDetectionCounter
        OpEventGetFaultDetectionCounter_GetFaultDetectionCounter_EvtInfo_AutoCreatedDemEvent_A_FlexRay_FRIF_E_ACS_CH_B: start-on-event=DemSatellite_0InternalBehavior/GetFaultDetectionCounter, operation=EvtInfo_AutoCreatedDemEvent_A_FlexRay_FRIF_E_ACS_CH_B.GetFaultDetectionCounter
        OpEventGetFaultDetectionCounter_GetFaultDetectionCounter_EvtInfo_AutoCreatedDemEvent_A_FlexRay_FRIF_E_NIT_CH_A: start-on-event=DemSatellite_0InternalBehavior/GetFaultDetectionCounter, operation=EvtInfo_AutoCreatedDemEvent_A_FlexRay_FRIF_E_NIT_CH_A.GetFaultDetectionCounter
        OpEventGetFaultDetectionCounter_GetFaultDetectionCounter_EvtInfo_AutoCreatedDemEvent_A_FlexRay_FRIF_E_NIT_CH_B: start-on-event=DemSatellite_0InternalBehavior/GetFaultDetectionCounter, operation=EvtInfo_AutoCreatedDemEvent_A_FlexRay_FRIF_E_NIT_CH_B.GetFaultDetectionCounter
        OpEventGetFaultDetectionCounter_GetFaultDetectionCounter_EvtInfo_AutoCreatedDemEvent_A_FlexRay_FRIF_E_SW_CH_A: start-on-event=DemSatellite_0InternalBehavior/GetFaultDetectionCounter, operation=EvtInfo_AutoCreatedDemEvent_A_FlexRay_FRIF_E_SW_CH_A.GetFaultDetectionCounter
        OpEventGetFaultDetectionCounter_GetFaultDetectionCounter_EvtInfo_AutoCreatedDemEvent_A_FlexRay_FRIF_E_SW_CH_B: start-on-event=DemSatellite_0InternalBehavior/GetFaultDetectionCounter, operation=EvtInfo_AutoCreatedDemEvent_A_FlexRay_FRIF_E_SW_CH_B.GetFaultDetectionCounter
        OpEventGetFaultDetectionCounter_GetFaultDetectionCounter_EvtInfo_AutoCreatedDemEvent_A_FlexRay_5b5a9ac2_FRSM_E_CLUSTER_STARTUP: start-on-event=DemSatellite_0InternalBehavior/GetFaultDetectionCounter, operation=EvtInfo_AutoCreatedDemEvent_A_FlexRay_5b5a9ac2_FRSM_E_CLUSTER_STARTUP.GetFaultDetectionCounter
        OpEventGetFaultDetectionCounter_GetFaultDetectionCounter_EvtInfo_AutoCreatedDemEvent_A_FlexRay_5b5a9ac2_FRSM_E_CLUSTER_SYNC_LOSS: start-on-event=DemSatellite_0InternalBehavior/GetFaultDetectionCounter, operation=EvtInfo_AutoCreatedDemEvent_A_FlexRay_5b5a9ac2_FRSM_E_CLUSTER_SYNC_LOSS.GetFaultDetectionCounter
        OpEventGetFaultDetectionCounter_GetFaultDetectionCounter_EvtInfo_AutoCreatedDemEvent_McuModuleConfiguration_MCU_E_CLOCK_FAILURE: start-on-event=DemSatellite_0InternalBehavior/GetFaultDetectionCounter, operation=EvtInfo_AutoCreatedDemEvent_McuModuleConfiguration_MCU_E_CLOCK_FAILURE.GetFaultDetectionCounter
        OpEventGetEventFreezeFrameDataEx_GetEventFreezeFrameDataEx_EvtInfo_AutoCreatedDemEvent_EcuMConfiguration_ECUM_E_ALL_RUN_993f76de: start-on-event=DemSatellite_0InternalBehavior/GetEventFreezeFrameDataEx, operation=EvtInfo_AutoCreatedDemEvent_EcuMConfiguration_ECUM_E_ALL_RUN_REQUESTS_KILLED.GetEventFreezeFrameDataEx
        OpEventGetEventFreezeFrameDataEx_GetEventFreezeFrameDataEx_EvtInfo_AutoCreatedDemEvent_EcuMConfiguration_ECUM_E_CONFIGU_7d4a80d3: start-on-event=DemSatellite_0InternalBehavior/GetEventFreezeFrameDataEx, operation=EvtInfo_AutoCreatedDemEvent_EcuMConfiguration_ECUM_E_CONFIGURATION_DATA_INCONSISTENT.GetEventFreezeFrameDataEx
        OpEventGetEventFreezeFrameDataEx_GetEventFreezeFrameDataEx_EvtInfo_AutoCreatedDemEvent_EcuMConfiguration_ECUM_E_RAM_CHECK_FAILED: start-on-event=DemSatellite_0InternalBehavior/GetEventFreezeFrameDataEx, operation=EvtInfo_AutoCreatedDemEvent_EcuMConfiguration_ECUM_E_RAM_CHECK_FAILED.GetEventFreezeFrameDataEx
        OpEventGetEventFreezeFrameDataEx_GetEventFreezeFrameDataEx_EvtInfo_AutoCreatedDemEvent_EcuMConfiguration_ECUM_E_IMPROPER_CALLER: start-on-event=DemSatellite_0InternalBehavior/GetEventFreezeFrameDataEx, operation=EvtInfo_AutoCreatedDemEvent_EcuMConfiguration_ECUM_E_IMPROPER_CALLER.GetEventFreezeFrameDataEx
        OpEventGetEventFreezeFrameDataEx_GetEventFreezeFrameDataEx_EvtInfo_AutoCreatedDemEvent_FlsConfigSet_FLS_E_COMPARE_FAILED: start-on-event=DemSatellite_0InternalBehavior/GetEventFreezeFrameDataEx, operation=EvtInfo_AutoCreatedDemEvent_FlsConfigSet_FLS_E_COMPARE_FAILED.GetEventFreezeFrameDataEx
        OpEventGetEventFreezeFrameDataEx_GetEventFreezeFrameDataEx_EvtInfo_AutoCreatedDemEvent_FlsConfigSet_FLS_E_ERASE_FAILED: start-on-event=DemSatellite_0InternalBehavior/GetEventFreezeFrameDataEx, operation=EvtInfo_AutoCreatedDemEvent_FlsConfigSet_FLS_E_ERASE_FAILED.GetEventFreezeFrameDataEx
        OpEventGetEventFreezeFrameDataEx_GetEventFreezeFrameDataEx_EvtInfo_AutoCreatedDemEvent_FlsConfigSet_FLS_E_READ_FAILED: start-on-event=DemSatellite_0InternalBehavior/GetEventFreezeFrameDataEx, operation=EvtInfo_AutoCreatedDemEvent_FlsConfigSet_FLS_E_READ_FAILED.GetEventFreezeFrameDataEx
        OpEventGetEventFreezeFrameDataEx_GetEventFreezeFrameDataEx_EvtInfo_AutoCreatedDemEvent_FlsConfigSet_FLS_E_UNEXPECTED_FLASH_ID: start-on-event=DemSatellite_0InternalBehavior/GetEventFreezeFrameDataEx, operation=EvtInfo_AutoCreatedDemEvent_FlsConfigSet_FLS_E_UNEXPECTED_FLASH_ID.GetEventFreezeFrameDataEx
        OpEventGetEventFreezeFrameDataEx_GetEventFreezeFrameDataEx_EvtInfo_AutoCreatedDemEvent_FlsConfigSet_FLS_E_WRITE_FAILED: start-on-event=DemSatellite_0InternalBehavior/GetEventFreezeFrameDataEx, operation=EvtInfo_AutoCreatedDemEvent_FlsConfigSet_FLS_E_WRITE_FAILED.GetEventFreezeFrameDataEx
        OpEventGetEventFreezeFrameDataEx_GetEventFreezeFrameDataEx_EvtInfo_AutoCreatedDemEvent_contr_EPS_A_FlexRay_FrDemCtrlTes_921ee45e: start-on-event=DemSatellite_0InternalBehavior/GetEventFreezeFrameDataEx, operation=EvtInfo_AutoCreatedDemEvent_contr_EPS_A_FlexRay_FrDemCtrlTestResultRef.GetEventFreezeFrameDataEx
        OpEventGetEventFreezeFrameDataEx_GetEventFreezeFrameDataEx_EvtInfo_AutoCreatedDemEvent_A_FlexRay_FRIF_E_ACS_CH_A: start-on-event=DemSatellite_0InternalBehavior/GetEventFreezeFrameDataEx, operation=EvtInfo_AutoCreatedDemEvent_A_FlexRay_FRIF_E_ACS_CH_A.GetEventFreezeFrameDataEx
        OpEventGetEventFreezeFrameDataEx_GetEventFreezeFrameDataEx_EvtInfo_AutoCreatedDemEvent_A_FlexRay_FRIF_E_ACS_CH_B: start-on-event=DemSatellite_0InternalBehavior/GetEventFreezeFrameDataEx, operation=EvtInfo_AutoCreatedDemEvent_A_FlexRay_FRIF_E_ACS_CH_B.GetEventFreezeFrameDataEx
        OpEventGetEventFreezeFrameDataEx_GetEventFreezeFrameDataEx_EvtInfo_AutoCreatedDemEvent_A_FlexRay_FRIF_E_NIT_CH_A: start-on-event=DemSatellite_0InternalBehavior/GetEventFreezeFrameDataEx, operation=EvtInfo_AutoCreatedDemEvent_A_FlexRay_FRIF_E_NIT_CH_A.GetEventFreezeFrameDataEx
        OpEventGetEventFreezeFrameDataEx_GetEventFreezeFrameDataEx_EvtInfo_AutoCreatedDemEvent_A_FlexRay_FRIF_E_NIT_CH_B: start-on-event=DemSatellite_0InternalBehavior/GetEventFreezeFrameDataEx, operation=EvtInfo_AutoCreatedDemEvent_A_FlexRay_FRIF_E_NIT_CH_B.GetEventFreezeFrameDataEx
        OpEventGetEventFreezeFrameDataEx_GetEventFreezeFrameDataEx_EvtInfo_AutoCreatedDemEvent_A_FlexRay_FRIF_E_SW_CH_A: start-on-event=DemSatellite_0InternalBehavior/GetEventFreezeFrameDataEx, operation=EvtInfo_AutoCreatedDemEvent_A_FlexRay_FRIF_E_SW_CH_A.GetEventFreezeFrameDataEx
        OpEventGetEventFreezeFrameDataEx_GetEventFreezeFrameDataEx_EvtInfo_AutoCreatedDemEvent_A_FlexRay_FRIF_E_SW_CH_B: start-on-event=DemSatellite_0InternalBehavior/GetEventFreezeFrameDataEx, operation=EvtInfo_AutoCreatedDemEvent_A_FlexRay_FRIF_E_SW_CH_B.GetEventFreezeFrameDataEx
        OpEventGetEventFreezeFrameDataEx_GetEventFreezeFrameDataEx_EvtInfo_AutoCreatedDemEvent_A_FlexRay_5b5a9ac2_FRSM_E_CLUSTER_STARTUP: start-on-event=DemSatellite_0InternalBehavior/GetEventFreezeFrameDataEx, operation=EvtInfo_AutoCreatedDemEvent_A_FlexRay_5b5a9ac2_FRSM_E_CLUSTER_STARTUP.GetEventFreezeFrameDataEx
        OpEventGetEventFreezeFrameDataEx_GetEventFreezeFrameDataEx_EvtInfo_AutoCreatedDemEvent_A_FlexRay_5b5a9ac2_FRSM_E_CLUSTE_c423b8fc: start-on-event=DemSatellite_0InternalBehavior/GetEventFreezeFrameDataEx, operation=EvtInfo_AutoCreatedDemEvent_A_FlexRay_5b5a9ac2_FRSM_E_CLUSTER_SYNC_LOSS.GetEventFreezeFrameDataEx
        OpEventGetEventFreezeFrameDataEx_GetEventFreezeFrameDataEx_EvtInfo_AutoCreatedDemEvent_McuModuleConfiguration_MCU_E_CLO_23816e70: start-on-event=DemSatellite_0InternalBehavior/GetEventFreezeFrameDataEx, operation=EvtInfo_AutoCreatedDemEvent_McuModuleConfiguration_MCU_E_CLOCK_FAILURE.GetEventFreezeFrameDataEx
        OpEventGetEventExtendedDataRecordEx_GetEventExtendedDataRecordEx_EvtInfo_AutoCreatedDemEvent_EcuMConfiguration_ECUM_E_A_6cc04a27: start-on-event=DemSatellite_0InternalBehavior/GetEventExtendedDataRecordEx, operation=EvtInfo_AutoCreatedDemEvent_EcuMConfiguration_ECUM_E_ALL_RUN_REQUESTS_KILLED.GetEventExtendedDataRecordEx
        OpEventGetEventExtendedDataRecordEx_GetEventExtendedDataRecordEx_EvtInfo_AutoCreatedDemEvent_EcuMConfiguration_ECUM_E_C_96bd3475: start-on-event=DemSatellite_0InternalBehavior/GetEventExtendedDataRecordEx, operation=EvtInfo_AutoCreatedDemEvent_EcuMConfiguration_ECUM_E_CONFIGURATION_DATA_INCONSISTENT.GetEventExtendedDataRecordEx
        OpEventGetEventExtendedDataRecordEx_GetEventExtendedDataRecordEx_EvtInfo_AutoCreatedDemEvent_EcuMConfiguration_ECUM_E_R_25bd882a: start-on-event=DemSatellite_0InternalBehavior/GetEventExtendedDataRecordEx, operation=EvtInfo_AutoCreatedDemEvent_EcuMConfiguration_ECUM_E_RAM_CHECK_FAILED.GetEventExtendedDataRecordEx
        OpEventGetEventExtendedDataRecordEx_GetEventExtendedDataRecordEx_EvtInfo_AutoCreatedDemEvent_EcuMConfiguration_ECUM_E_I_7db075fd: start-on-event=DemSatellite_0InternalBehavior/GetEventExtendedDataRecordEx, operation=EvtInfo_AutoCreatedDemEvent_EcuMConfiguration_ECUM_E_IMPROPER_CALLER.GetEventExtendedDataRecordEx
        OpEventGetEventExtendedDataRecordEx_GetEventExtendedDataRecordEx_EvtInfo_AutoCreatedDemEvent_FlsConfigSet_FLS_E_COMPARE_FAILED: start-on-event=DemSatellite_0InternalBehavior/GetEventExtendedDataRecordEx, operation=EvtInfo_AutoCreatedDemEvent_FlsConfigSet_FLS_E_COMPARE_FAILED.GetEventExtendedDataRecordEx
        OpEventGetEventExtendedDataRecordEx_GetEventExtendedDataRecordEx_EvtInfo_AutoCreatedDemEvent_FlsConfigSet_FLS_E_ERASE_FAILED: start-on-event=DemSatellite_0InternalBehavior/GetEventExtendedDataRecordEx, operation=EvtInfo_AutoCreatedDemEvent_FlsConfigSet_FLS_E_ERASE_FAILED.GetEventExtendedDataRecordEx
        OpEventGetEventExtendedDataRecordEx_GetEventExtendedDataRecordEx_EvtInfo_AutoCreatedDemEvent_FlsConfigSet_FLS_E_READ_FAILED: start-on-event=DemSatellite_0InternalBehavior/GetEventExtendedDataRecordEx, operation=EvtInfo_AutoCreatedDemEvent_FlsConfigSet_FLS_E_READ_FAILED.GetEventExtendedDataRecordEx
        OpEventGetEventExtendedDataRecordEx_GetEventExtendedDataRecordEx_EvtInfo_AutoCreatedDemEvent_FlsConfigSet_FLS_E_UNEXPEC_679fc3cc: start-on-event=DemSatellite_0InternalBehavior/GetEventExtendedDataRecordEx, operation=EvtInfo_AutoCreatedDemEvent_FlsConfigSet_FLS_E_UNEXPECTED_FLASH_ID.GetEventExtendedDataRecordEx
        OpEventGetEventExtendedDataRecordEx_GetEventExtendedDataRecordEx_EvtInfo_AutoCreatedDemEvent_FlsConfigSet_FLS_E_WRITE_FAILED: start-on-event=DemSatellite_0InternalBehavior/GetEventExtendedDataRecordEx, operation=EvtInfo_AutoCreatedDemEvent_FlsConfigSet_FLS_E_WRITE_FAILED.GetEventExtendedDataRecordEx
        OpEventGetEventExtendedDataRecordEx_GetEventExtendedDataRecordEx_EvtInfo_AutoCreatedDemEvent_contr_EPS_A_FlexRay_FrDemC_703d2ff5: start-on-event=DemSatellite_0InternalBehavior/GetEventExtendedDataRecordEx, operation=EvtInfo_AutoCreatedDemEvent_contr_EPS_A_FlexRay_FrDemCtrlTestResultRef.GetEventExtendedDataRecordEx
        OpEventGetEventExtendedDataRecordEx_GetEventExtendedDataRecordEx_EvtInfo_AutoCreatedDemEvent_A_FlexRay_FRIF_E_ACS_CH_A: start-on-event=DemSatellite_0InternalBehavior/GetEventExtendedDataRecordEx, operation=EvtInfo_AutoCreatedDemEvent_A_FlexRay_FRIF_E_ACS_CH_A.GetEventExtendedDataRecordEx
        OpEventGetEventExtendedDataRecordEx_GetEventExtendedDataRecordEx_EvtInfo_AutoCreatedDemEvent_A_FlexRay_FRIF_E_ACS_CH_B: start-on-event=DemSatellite_0InternalBehavior/GetEventExtendedDataRecordEx, operation=EvtInfo_AutoCreatedDemEvent_A_FlexRay_FRIF_E_ACS_CH_B.GetEventExtendedDataRecordEx
        OpEventGetEventExtendedDataRecordEx_GetEventExtendedDataRecordEx_EvtInfo_AutoCreatedDemEvent_A_FlexRay_FRIF_E_NIT_CH_A: start-on-event=DemSatellite_0InternalBehavior/GetEventExtendedDataRecordEx, operation=EvtInfo_AutoCreatedDemEvent_A_FlexRay_FRIF_E_NIT_CH_A.GetEventExtendedDataRecordEx
        OpEventGetEventExtendedDataRecordEx_GetEventExtendedDataRecordEx_EvtInfo_AutoCreatedDemEvent_A_FlexRay_FRIF_E_NIT_CH_B: start-on-event=DemSatellite_0InternalBehavior/GetEventExtendedDataRecordEx, operation=EvtInfo_AutoCreatedDemEvent_A_FlexRay_FRIF_E_NIT_CH_B.GetEventExtendedDataRecordEx
        OpEventGetEventExtendedDataRecordEx_GetEventExtendedDataRecordEx_EvtInfo_AutoCreatedDemEvent_A_FlexRay_FRIF_E_SW_CH_A: start-on-event=DemSatellite_0InternalBehavior/GetEventExtendedDataRecordEx, operation=EvtInfo_AutoCreatedDemEvent_A_FlexRay_FRIF_E_SW_CH_A.GetEventExtendedDataRecordEx
        OpEventGetEventExtendedDataRecordEx_GetEventExtendedDataRecordEx_EvtInfo_AutoCreatedDemEvent_A_FlexRay_FRIF_E_SW_CH_B: start-on-event=DemSatellite_0InternalBehavior/GetEventExtendedDataRecordEx, operation=EvtInfo_AutoCreatedDemEvent_A_FlexRay_FRIF_E_SW_CH_B.GetEventExtendedDataRecordEx
        OpEventGetEventExtendedDataRecordEx_GetEventExtendedDataRecordEx_EvtInfo_AutoCreatedDemEvent_A_FlexRay_5b5a9ac2_FRSM_E_72b8e425: start-on-event=DemSatellite_0InternalBehavior/GetEventExtendedDataRecordEx, operation=EvtInfo_AutoCreatedDemEvent_A_FlexRay_5b5a9ac2_FRSM_E_CLUSTER_STARTUP.GetEventExtendedDataRecordEx
        OpEventGetEventExtendedDataRecordEx_GetEventExtendedDataRecordEx_EvtInfo_AutoCreatedDemEvent_A_FlexRay_5b5a9ac2_FRSM_E_85c5e157: start-on-event=DemSatellite_0InternalBehavior/GetEventExtendedDataRecordEx, operation=EvtInfo_AutoCreatedDemEvent_A_FlexRay_5b5a9ac2_FRSM_E_CLUSTER_SYNC_LOSS.GetEventExtendedDataRecordEx
        OpEventGetEventExtendedDataRecordEx_GetEventExtendedDataRecordEx_EvtInfo_AutoCreatedDemEvent_McuModuleConfiguration_MCU_c1a2a5db: start-on-event=DemSatellite_0InternalBehavior/GetEventExtendedDataRecordEx, operation=EvtInfo_AutoCreatedDemEvent_McuModuleConfiguration_MCU_E_CLOCK_FAILURE.GetEventExtendedDataRecordEx
        OpEventGetEventEnableCondition_GetEventEnableCondition_EvtInfo_AutoCreatedDemEvent_EcuMConfiguration_ECUM_E_ALL_RUN_REQ_5b1f807c: start-on-event=DemSatellite_0InternalBehavior/GetEventEnableCondition, operation=EvtInfo_AutoCreatedDemEvent_EcuMConfiguration_ECUM_E_ALL_RUN_REQUESTS_KILLED.GetEventEnableCondition
        OpEventGetEventEnableCondition_GetEventEnableCondition_EvtInfo_AutoCreatedDemEvent_EcuMConfiguration_ECUM_E_CONFIGURATI_06f5d14c: start-on-event=DemSatellite_0InternalBehavior/GetEventEnableCondition, operation=EvtInfo_AutoCreatedDemEvent_EcuMConfiguration_ECUM_E_CONFIGURATION_DATA_INCONSISTENT.GetEventEnableCondition
        OpEventGetEventEnableCondition_GetEventEnableCondition_EvtInfo_AutoCreatedDemEvent_EcuMConfiguration_ECUM_E_RAM_CHECK_FAILED: start-on-event=DemSatellite_0InternalBehavior/GetEventEnableCondition, operation=EvtInfo_AutoCreatedDemEvent_EcuMConfiguration_ECUM_E_RAM_CHECK_FAILED.GetEventEnableCondition
        OpEventGetEventEnableCondition_GetEventEnableCondition_EvtInfo_AutoCreatedDemEvent_EcuMConfiguration_ECUM_E_IMPROPER_CALLER: start-on-event=DemSatellite_0InternalBehavior/GetEventEnableCondition, operation=EvtInfo_AutoCreatedDemEvent_EcuMConfiguration_ECUM_E_IMPROPER_CALLER.GetEventEnableCondition
        OpEventGetEventEnableCondition_GetEventEnableCondition_EvtInfo_AutoCreatedDemEvent_FlsConfigSet_FLS_E_COMPARE_FAILED: start-on-event=DemSatellite_0InternalBehavior/GetEventEnableCondition, operation=EvtInfo_AutoCreatedDemEvent_FlsConfigSet_FLS_E_COMPARE_FAILED.GetEventEnableCondition
        OpEventGetEventEnableCondition_GetEventEnableCondition_EvtInfo_AutoCreatedDemEvent_FlsConfigSet_FLS_E_ERASE_FAILED: start-on-event=DemSatellite_0InternalBehavior/GetEventEnableCondition, operation=EvtInfo_AutoCreatedDemEvent_FlsConfigSet_FLS_E_ERASE_FAILED.GetEventEnableCondition
        OpEventGetEventEnableCondition_GetEventEnableCondition_EvtInfo_AutoCreatedDemEvent_FlsConfigSet_FLS_E_READ_FAILED: start-on-event=DemSatellite_0InternalBehavior/GetEventEnableCondition, operation=EvtInfo_AutoCreatedDemEvent_FlsConfigSet_FLS_E_READ_FAILED.GetEventEnableCondition
        OpEventGetEventEnableCondition_GetEventEnableCondition_EvtInfo_AutoCreatedDemEvent_FlsConfigSet_FLS_E_UNEXPECTED_FLASH_ID: start-on-event=DemSatellite_0InternalBehavior/GetEventEnableCondition, operation=EvtInfo_AutoCreatedDemEvent_FlsConfigSet_FLS_E_UNEXPECTED_FLASH_ID.GetEventEnableCondition
        OpEventGetEventEnableCondition_GetEventEnableCondition_EvtInfo_AutoCreatedDemEvent_FlsConfigSet_FLS_E_WRITE_FAILED: start-on-event=DemSatellite_0InternalBehavior/GetEventEnableCondition, operation=EvtInfo_AutoCreatedDemEvent_FlsConfigSet_FLS_E_WRITE_FAILED.GetEventEnableCondition
        OpEventGetEventEnableCondition_GetEventEnableCondition_EvtInfo_AutoCreatedDemEvent_contr_EPS_A_FlexRay_FrDemCtrlTestResultRef: start-on-event=DemSatellite_0InternalBehavior/GetEventEnableCondition, operation=EvtInfo_AutoCreatedDemEvent_contr_EPS_A_FlexRay_FrDemCtrlTestResultRef.GetEventEnableCondition
        OpEventGetEventEnableCondition_GetEventEnableCondition_EvtInfo_AutoCreatedDemEvent_A_FlexRay_FRIF_E_ACS_CH_A: start-on-event=DemSatellite_0InternalBehavior/GetEventEnableCondition, operation=EvtInfo_AutoCreatedDemEvent_A_FlexRay_FRIF_E_ACS_CH_A.GetEventEnableCondition
        OpEventGetEventEnableCondition_GetEventEnableCondition_EvtInfo_AutoCreatedDemEvent_A_FlexRay_FRIF_E_ACS_CH_B: start-on-event=DemSatellite_0InternalBehavior/GetEventEnableCondition, operation=EvtInfo_AutoCreatedDemEvent_A_FlexRay_FRIF_E_ACS_CH_B.GetEventEnableCondition
        OpEventGetEventEnableCondition_GetEventEnableCondition_EvtInfo_AutoCreatedDemEvent_A_FlexRay_FRIF_E_NIT_CH_A: start-on-event=DemSatellite_0InternalBehavior/GetEventEnableCondition, operation=EvtInfo_AutoCreatedDemEvent_A_FlexRay_FRIF_E_NIT_CH_A.GetEventEnableCondition
        OpEventGetEventEnableCondition_GetEventEnableCondition_EvtInfo_AutoCreatedDemEvent_A_FlexRay_FRIF_E_NIT_CH_B: start-on-event=DemSatellite_0InternalBehavior/GetEventEnableCondition, operation=EvtInfo_AutoCreatedDemEvent_A_FlexRay_FRIF_E_NIT_CH_B.GetEventEnableCondition
        OpEventGetEventEnableCondition_GetEventEnableCondition_EvtInfo_AutoCreatedDemEvent_A_FlexRay_FRIF_E_SW_CH_A: start-on-event=DemSatellite_0InternalBehavior/GetEventEnableCondition, operation=EvtInfo_AutoCreatedDemEvent_A_FlexRay_FRIF_E_SW_CH_A.GetEventEnableCondition
        OpEventGetEventEnableCondition_GetEventEnableCondition_EvtInfo_AutoCreatedDemEvent_A_FlexRay_FRIF_E_SW_CH_B: start-on-event=DemSatellite_0InternalBehavior/GetEventEnableCondition, operation=EvtInfo_AutoCreatedDemEvent_A_FlexRay_FRIF_E_SW_CH_B.GetEventEnableCondition
        OpEventGetEventEnableCondition_GetEventEnableCondition_EvtInfo_AutoCreatedDemEvent_A_FlexRay_5b5a9ac2_FRSM_E_CLUSTER_STARTUP: start-on-event=DemSatellite_0InternalBehavior/GetEventEnableCondition, operation=EvtInfo_AutoCreatedDemEvent_A_FlexRay_5b5a9ac2_FRSM_E_CLUSTER_STARTUP.GetEventEnableCondition
        OpEventGetEventEnableCondition_GetEventEnableCondition_EvtInfo_AutoCreatedDemEvent_A_FlexRay_5b5a9ac2_FRSM_E_CLUSTER_SYNC_LOSS: start-on-event=DemSatellite_0InternalBehavior/GetEventEnableCondition, operation=EvtInfo_AutoCreatedDemEvent_A_FlexRay_5b5a9ac2_FRSM_E_CLUSTER_SYNC_LOSS.GetEventEnableCondition
        OpEventGetEventEnableCondition_GetEventEnableCondition_EvtInfo_AutoCreatedDemEvent_McuModuleConfiguration_MCU_E_CLOCK_FAILURE: start-on-event=DemSatellite_0InternalBehavior/GetEventEnableCondition, operation=EvtInfo_AutoCreatedDemEvent_McuModuleConfiguration_MCU_E_CLOCK_FAILURE.GetEventEnableCondition
        OpEventGetDebouncingOfEvent_GetDebouncingOfEvent_EvtInfo_AutoCreatedDemEvent_EcuMConfiguration_ECUM_E_ALL_RUN_REQUESTS_KILLED: start-on-event=DemSatellite_0InternalBehavior/GetDebouncingOfEvent, operation=EvtInfo_AutoCreatedDemEvent_EcuMConfiguration_ECUM_E_ALL_RUN_REQUESTS_KILLED.GetDebouncingOfEvent
        OpEventGetDebouncingOfEvent_GetDebouncingOfEvent_EvtInfo_AutoCreatedDemEvent_EcuMConfiguration_ECUM_E_CONFIGURATION_DAT_7642b2c3: start-on-event=DemSatellite_0InternalBehavior/GetDebouncingOfEvent, operation=EvtInfo_AutoCreatedDemEvent_EcuMConfiguration_ECUM_E_CONFIGURATION_DATA_INCONSISTENT.GetDebouncingOfEvent
        OpEventGetDebouncingOfEvent_GetDebouncingOfEvent_EvtInfo_AutoCreatedDemEvent_EcuMConfiguration_ECUM_E_RAM_CHECK_FAILED: start-on-event=DemSatellite_0InternalBehavior/GetDebouncingOfEvent, operation=EvtInfo_AutoCreatedDemEvent_EcuMConfiguration_ECUM_E_RAM_CHECK_FAILED.GetDebouncingOfEvent
        OpEventGetDebouncingOfEvent_GetDebouncingOfEvent_EvtInfo_AutoCreatedDemEvent_EcuMConfiguration_ECUM_E_IMPROPER_CALLER: start-on-event=DemSatellite_0InternalBehavior/GetDebouncingOfEvent, operation=EvtInfo_AutoCreatedDemEvent_EcuMConfiguration_ECUM_E_IMPROPER_CALLER.GetDebouncingOfEvent
        OpEventGetDebouncingOfEvent_GetDebouncingOfEvent_EvtInfo_AutoCreatedDemEvent_FlsConfigSet_FLS_E_COMPARE_FAILED: start-on-event=DemSatellite_0InternalBehavior/GetDebouncingOfEvent, operation=EvtInfo_AutoCreatedDemEvent_FlsConfigSet_FLS_E_COMPARE_FAILED.GetDebouncingOfEvent
        OpEventGetDebouncingOfEvent_GetDebouncingOfEvent_EvtInfo_AutoCreatedDemEvent_FlsConfigSet_FLS_E_ERASE_FAILED: start-on-event=DemSatellite_0InternalBehavior/GetDebouncingOfEvent, operation=EvtInfo_AutoCreatedDemEvent_FlsConfigSet_FLS_E_ERASE_FAILED.GetDebouncingOfEvent
        OpEventGetDebouncingOfEvent_GetDebouncingOfEvent_EvtInfo_AutoCreatedDemEvent_FlsConfigSet_FLS_E_READ_FAILED: start-on-event=DemSatellite_0InternalBehavior/GetDebouncingOfEvent, operation=EvtInfo_AutoCreatedDemEvent_FlsConfigSet_FLS_E_READ_FAILED.GetDebouncingOfEvent
        OpEventGetDebouncingOfEvent_GetDebouncingOfEvent_EvtInfo_AutoCreatedDemEvent_FlsConfigSet_FLS_E_UNEXPECTED_FLASH_ID: start-on-event=DemSatellite_0InternalBehavior/GetDebouncingOfEvent, operation=EvtInfo_AutoCreatedDemEvent_FlsConfigSet_FLS_E_UNEXPECTED_FLASH_ID.GetDebouncingOfEvent
        OpEventGetDebouncingOfEvent_GetDebouncingOfEvent_EvtInfo_AutoCreatedDemEvent_FlsConfigSet_FLS_E_WRITE_FAILED: start-on-event=DemSatellite_0InternalBehavior/GetDebouncingOfEvent, operation=EvtInfo_AutoCreatedDemEvent_FlsConfigSet_FLS_E_WRITE_FAILED.GetDebouncingOfEvent
        OpEventGetDebouncingOfEvent_GetDebouncingOfEvent_EvtInfo_AutoCreatedDemEvent_contr_EPS_A_FlexRay_FrDemCtrlTestResultRef: start-on-event=DemSatellite_0InternalBehavior/GetDebouncingOfEvent, operation=EvtInfo_AutoCreatedDemEvent_contr_EPS_A_FlexRay_FrDemCtrlTestResultRef.GetDebouncingOfEvent
        OpEventGetDebouncingOfEvent_GetDebouncingOfEvent_EvtInfo_AutoCreatedDemEvent_A_FlexRay_FRIF_E_ACS_CH_A: start-on-event=DemSatellite_0InternalBehavior/GetDebouncingOfEvent, operation=EvtInfo_AutoCreatedDemEvent_A_FlexRay_FRIF_E_ACS_CH_A.GetDebouncingOfEvent
        OpEventGetDebouncingOfEvent_GetDebouncingOfEvent_EvtInfo_AutoCreatedDemEvent_A_FlexRay_FRIF_E_ACS_CH_B: start-on-event=DemSatellite_0InternalBehavior/GetDebouncingOfEvent, operation=EvtInfo_AutoCreatedDemEvent_A_FlexRay_FRIF_E_ACS_CH_B.GetDebouncingOfEvent
        OpEventGetDebouncingOfEvent_GetDebouncingOfEvent_EvtInfo_AutoCreatedDemEvent_A_FlexRay_FRIF_E_NIT_CH_A: start-on-event=DemSatellite_0InternalBehavior/GetDebouncingOfEvent, operation=EvtInfo_AutoCreatedDemEvent_A_FlexRay_FRIF_E_NIT_CH_A.GetDebouncingOfEvent
        OpEventGetDebouncingOfEvent_GetDebouncingOfEvent_EvtInfo_AutoCreatedDemEvent_A_FlexRay_FRIF_E_NIT_CH_B: start-on-event=DemSatellite_0InternalBehavior/GetDebouncingOfEvent, operation=EvtInfo_AutoCreatedDemEvent_A_FlexRay_FRIF_E_NIT_CH_B.GetDebouncingOfEvent
        OpEventGetDebouncingOfEvent_GetDebouncingOfEvent_EvtInfo_AutoCreatedDemEvent_A_FlexRay_FRIF_E_SW_CH_A: start-on-event=DemSatellite_0InternalBehavior/GetDebouncingOfEvent, operation=EvtInfo_AutoCreatedDemEvent_A_FlexRay_FRIF_E_SW_CH_A.GetDebouncingOfEvent
        OpEventGetDebouncingOfEvent_GetDebouncingOfEvent_EvtInfo_AutoCreatedDemEvent_A_FlexRay_FRIF_E_SW_CH_B: start-on-event=DemSatellite_0InternalBehavior/GetDebouncingOfEvent, operation=EvtInfo_AutoCreatedDemEvent_A_FlexRay_FRIF_E_SW_CH_B.GetDebouncingOfEvent
        OpEventGetDebouncingOfEvent_GetDebouncingOfEvent_EvtInfo_AutoCreatedDemEvent_A_FlexRay_5b5a9ac2_FRSM_E_CLUSTER_STARTUP: start-on-event=DemSatellite_0InternalBehavior/GetDebouncingOfEvent, operation=EvtInfo_AutoCreatedDemEvent_A_FlexRay_5b5a9ac2_FRSM_E_CLUSTER_STARTUP.GetDebouncingOfEvent
        OpEventGetDebouncingOfEvent_GetDebouncingOfEvent_EvtInfo_AutoCreatedDemEvent_A_FlexRay_5b5a9ac2_FRSM_E_CLUSTER_SYNC_LOSS: start-on-event=DemSatellite_0InternalBehavior/GetDebouncingOfEvent, operation=EvtInfo_AutoCreatedDemEvent_A_FlexRay_5b5a9ac2_FRSM_E_CLUSTER_SYNC_LOSS.GetDebouncingOfEvent
        OpEventGetDebouncingOfEvent_GetDebouncingOfEvent_EvtInfo_AutoCreatedDemEvent_McuModuleConfiguration_MCU_E_CLOCK_FAILURE: start-on-event=DemSatellite_0InternalBehavior/GetDebouncingOfEvent, operation=EvtInfo_AutoCreatedDemEvent_McuModuleConfiguration_MCU_E_CLOCK_FAILURE.GetDebouncingOfEvent
        OpEventGetMonitorStatus_GetMonitorStatus_EvtInfo_AutoCreatedDemEvent_EcuMConfiguration_ECUM_E_ALL_RUN_REQUESTS_KILLED: start-on-event=DemSatellite_0InternalBehavior/GetMonitorStatus, operation=EvtInfo_AutoCreatedDemEvent_EcuMConfiguration_ECUM_E_ALL_RUN_REQUESTS_KILLED.GetMonitorStatus
        OpEventGetMonitorStatus_GetMonitorStatus_EvtInfo_AutoCreatedDemEvent_EcuMConfiguration_ECUM_E_CONFIGURATION_DATA_INCONSISTENT: start-on-event=DemSatellite_0InternalBehavior/GetMonitorStatus, operation=EvtInfo_AutoCreatedDemEvent_EcuMConfiguration_ECUM_E_CONFIGURATION_DATA_INCONSISTENT.GetMonitorStatus
        OpEventGetMonitorStatus_GetMonitorStatus_EvtInfo_AutoCreatedDemEvent_EcuMConfiguration_ECUM_E_RAM_CHECK_FAILED: start-on-event=DemSatellite_0InternalBehavior/GetMonitorStatus, operation=EvtInfo_AutoCreatedDemEvent_EcuMConfiguration_ECUM_E_RAM_CHECK_FAILED.GetMonitorStatus
        OpEventGetMonitorStatus_GetMonitorStatus_EvtInfo_AutoCreatedDemEvent_EcuMConfiguration_ECUM_E_IMPROPER_CALLER: start-on-event=DemSatellite_0InternalBehavior/GetMonitorStatus, operation=EvtInfo_AutoCreatedDemEvent_EcuMConfiguration_ECUM_E_IMPROPER_CALLER.GetMonitorStatus
        OpEventGetMonitorStatus_GetMonitorStatus_EvtInfo_AutoCreatedDemEvent_FlsConfigSet_FLS_E_COMPARE_FAILED: start-on-event=DemSatellite_0InternalBehavior/GetMonitorStatus, operation=EvtInfo_AutoCreatedDemEvent_FlsConfigSet_FLS_E_COMPARE_FAILED.GetMonitorStatus
        OpEventGetMonitorStatus_GetMonitorStatus_EvtInfo_AutoCreatedDemEvent_FlsConfigSet_FLS_E_ERASE_FAILED: start-on-event=DemSatellite_0InternalBehavior/GetMonitorStatus, operation=EvtInfo_AutoCreatedDemEvent_FlsConfigSet_FLS_E_ERASE_FAILED.GetMonitorStatus
        OpEventGetMonitorStatus_GetMonitorStatus_EvtInfo_AutoCreatedDemEvent_FlsConfigSet_FLS_E_READ_FAILED: start-on-event=DemSatellite_0InternalBehavior/GetMonitorStatus, operation=EvtInfo_AutoCreatedDemEvent_FlsConfigSet_FLS_E_READ_FAILED.GetMonitorStatus
        OpEventGetMonitorStatus_GetMonitorStatus_EvtInfo_AutoCreatedDemEvent_FlsConfigSet_FLS_E_UNEXPECTED_FLASH_ID: start-on-event=DemSatellite_0InternalBehavior/GetMonitorStatus, operation=EvtInfo_AutoCreatedDemEvent_FlsConfigSet_FLS_E_UNEXPECTED_FLASH_ID.GetMonitorStatus
        OpEventGetMonitorStatus_GetMonitorStatus_EvtInfo_AutoCreatedDemEvent_FlsConfigSet_FLS_E_WRITE_FAILED: start-on-event=DemSatellite_0InternalBehavior/GetMonitorStatus, operation=EvtInfo_AutoCreatedDemEvent_FlsConfigSet_FLS_E_WRITE_FAILED.GetMonitorStatus
        OpEventGetMonitorStatus_GetMonitorStatus_EvtInfo_AutoCreatedDemEvent_contr_EPS_A_FlexRay_FrDemCtrlTestResultRef: start-on-event=DemSatellite_0InternalBehavior/GetMonitorStatus, operation=EvtInfo_AutoCreatedDemEvent_contr_EPS_A_FlexRay_FrDemCtrlTestResultRef.GetMonitorStatus
        OpEventGetMonitorStatus_GetMonitorStatus_EvtInfo_AutoCreatedDemEvent_A_FlexRay_FRIF_E_ACS_CH_A: start-on-event=DemSatellite_0InternalBehavior/GetMonitorStatus, operation=EvtInfo_AutoCreatedDemEvent_A_FlexRay_FRIF_E_ACS_CH_A.GetMonitorStatus
        OpEventGetMonitorStatus_GetMonitorStatus_EvtInfo_AutoCreatedDemEvent_A_FlexRay_FRIF_E_ACS_CH_B: start-on-event=DemSatellite_0InternalBehavior/GetMonitorStatus, operation=EvtInfo_AutoCreatedDemEvent_A_FlexRay_FRIF_E_ACS_CH_B.GetMonitorStatus
        OpEventGetMonitorStatus_GetMonitorStatus_EvtInfo_AutoCreatedDemEvent_A_FlexRay_FRIF_E_NIT_CH_A: start-on-event=DemSatellite_0InternalBehavior/GetMonitorStatus, operation=EvtInfo_AutoCreatedDemEvent_A_FlexRay_FRIF_E_NIT_CH_A.GetMonitorStatus
        OpEventGetMonitorStatus_GetMonitorStatus_EvtInfo_AutoCreatedDemEvent_A_FlexRay_FRIF_E_NIT_CH_B: start-on-event=DemSatellite_0InternalBehavior/GetMonitorStatus, operation=EvtInfo_AutoCreatedDemEvent_A_FlexRay_FRIF_E_NIT_CH_B.GetMonitorStatus
        OpEventGetMonitorStatus_GetMonitorStatus_EvtInfo_AutoCreatedDemEvent_A_FlexRay_FRIF_E_SW_CH_A: start-on-event=DemSatellite_0InternalBehavior/GetMonitorStatus, operation=EvtInfo_AutoCreatedDemEvent_A_FlexRay_FRIF_E_SW_CH_A.GetMonitorStatus
        OpEventGetMonitorStatus_GetMonitorStatus_EvtInfo_AutoCreatedDemEvent_A_FlexRay_FRIF_E_SW_CH_B: start-on-event=DemSatellite_0InternalBehavior/GetMonitorStatus, operation=EvtInfo_AutoCreatedDemEvent_A_FlexRay_FRIF_E_SW_CH_B.GetMonitorStatus
        OpEventGetMonitorStatus_GetMonitorStatus_EvtInfo_AutoCreatedDemEvent_A_FlexRay_5b5a9ac2_FRSM_E_CLUSTER_STARTUP: start-on-event=DemSatellite_0InternalBehavior/GetMonitorStatus, operation=EvtInfo_AutoCreatedDemEvent_A_FlexRay_5b5a9ac2_FRSM_E_CLUSTER_STARTUP.GetMonitorStatus
        OpEventGetMonitorStatus_GetMonitorStatus_EvtInfo_AutoCreatedDemEvent_A_FlexRay_5b5a9ac2_FRSM_E_CLUSTER_SYNC_LOSS: start-on-event=DemSatellite_0InternalBehavior/GetMonitorStatus, operation=EvtInfo_AutoCreatedDemEvent_A_FlexRay_5b5a9ac2_FRSM_E_CLUSTER_SYNC_LOSS.GetMonitorStatus
        OpEventGetMonitorStatus_GetMonitorStatus_EvtInfo_AutoCreatedDemEvent_McuModuleConfiguration_MCU_E_CLOCK_FAILURE: start-on-event=DemSatellite_0InternalBehavior/GetMonitorStatus, operation=EvtInfo_AutoCreatedDemEvent_McuModuleConfiguration_MCU_E_CLOCK_FAILURE.GetMonitorStatus
        OpEventGetEventUdsStatus_GetEventUdsStatus_EvtInfo_DemEventParameter_002: start-on-event=DemSatellite_0InternalBehavior/GetEventUdsStatus, operation=EvtInfo_DemEventParameter_002.GetEventUdsStatus
        OpEventGetEventUdsStatus_GetEventUdsStatus_Event_DemEventParameter_002: start-on-event=DemSatellite_0InternalBehavior/GetEventUdsStatus, operation=Event_DemEventParameter_002.GetEventUdsStatus
        OpEventGetEventUdsStatus_GetEventUdsStatus_EvtInfo_DemEventParameter_003: start-on-event=DemSatellite_0InternalBehavior/GetEventUdsStatus, operation=EvtInfo_DemEventParameter_003.GetEventUdsStatus
        OpEventGetEventUdsStatus_GetEventUdsStatus_Event_DemEventParameter_003: start-on-event=DemSatellite_0InternalBehavior/GetEventUdsStatus, operation=Event_DemEventParameter_003.GetEventUdsStatus
        OpEventGetEventUdsStatus_GetEventUdsStatus_EvtInfo_DemEventParameter_004: start-on-event=DemSatellite_0InternalBehavior/GetEventUdsStatus, operation=EvtInfo_DemEventParameter_004.GetEventUdsStatus
        OpEventGetEventUdsStatus_GetEventUdsStatus_Event_DemEventParameter_004: start-on-event=DemSatellite_0InternalBehavior/GetEventUdsStatus, operation=Event_DemEventParameter_004.GetEventUdsStatus
        OpEventGetEventUdsStatus_GetEventUdsStatus_EvtInfo_DemEventParameter_005: start-on-event=DemSatellite_0InternalBehavior/GetEventUdsStatus, operation=EvtInfo_DemEventParameter_005.GetEventUdsStatus
        OpEventGetEventUdsStatus_GetEventUdsStatus_Event_DemEventParameter_005: start-on-event=DemSatellite_0InternalBehavior/GetEventUdsStatus, operation=Event_DemEventParameter_005.GetEventUdsStatus
        OpEventGetEventUdsStatus_GetEventUdsStatus_EvtInfo_DemEventParameter_006: start-on-event=DemSatellite_0InternalBehavior/GetEventUdsStatus, operation=EvtInfo_DemEventParameter_006.GetEventUdsStatus
        OpEventGetEventUdsStatus_GetEventUdsStatus_Event_DemEventParameter_006: start-on-event=DemSatellite_0InternalBehavior/GetEventUdsStatus, operation=Event_DemEventParameter_006.GetEventUdsStatus
        OpEventGetEventUdsStatus_GetEventUdsStatus_EvtInfo_DemEventParameter_007: start-on-event=DemSatellite_0InternalBehavior/GetEventUdsStatus, operation=EvtInfo_DemEventParameter_007.GetEventUdsStatus
        OpEventGetEventUdsStatus_GetEventUdsStatus_Event_DemEventParameter_007: start-on-event=DemSatellite_0InternalBehavior/GetEventUdsStatus, operation=Event_DemEventParameter_007.GetEventUdsStatus
        OpEventGetEventUdsStatus_GetEventUdsStatus_EvtInfo_DemEventParameter_008: start-on-event=DemSatellite_0InternalBehavior/GetEventUdsStatus, operation=EvtInfo_DemEventParameter_008.GetEventUdsStatus
        OpEventGetEventUdsStatus_GetEventUdsStatus_Event_DemEventParameter_008: start-on-event=DemSatellite_0InternalBehavior/GetEventUdsStatus, operation=Event_DemEventParameter_008.GetEventUdsStatus
        OpEventGetEventUdsStatus_GetEventUdsStatus_EvtInfo_DemEventParameter_009: start-on-event=DemSatellite_0InternalBehavior/GetEventUdsStatus, operation=EvtInfo_DemEventParameter_009.GetEventUdsStatus
        OpEventGetEventUdsStatus_GetEventUdsStatus_Event_DemEventParameter_009: start-on-event=DemSatellite_0InternalBehavior/GetEventUdsStatus, operation=Event_DemEventParameter_009.GetEventUdsStatus
        OpEventGetEventUdsStatus_GetEventUdsStatus_EvtInfo_DemEventParameter_010: start-on-event=DemSatellite_0InternalBehavior/GetEventUdsStatus, operation=EvtInfo_DemEventParameter_010.GetEventUdsStatus
        OpEventGetEventUdsStatus_GetEventUdsStatus_Event_DemEventParameter_010: start-on-event=DemSatellite_0InternalBehavior/GetEventUdsStatus, operation=Event_DemEventParameter_010.GetEventUdsStatus
        OpEventGetEventUdsStatus_GetEventUdsStatus_EvtInfo_DemEventParameter_011: start-on-event=DemSatellite_0InternalBehavior/GetEventUdsStatus, operation=EvtInfo_DemEventParameter_011.GetEventUdsStatus
        OpEventGetEventUdsStatus_GetEventUdsStatus_Event_DemEventParameter_011: start-on-event=DemSatellite_0InternalBehavior/GetEventUdsStatus, operation=Event_DemEventParameter_011.GetEventUdsStatus
        OpEventGetEventStatus_GetEventStatus_EvtInfo_DemEventParameter_002: start-on-event=DemSatellite_0InternalBehavior/GetEventStatus, operation=EvtInfo_DemEventParameter_002.GetEventStatus
        OpEventGetEventStatus_GetEventStatus_Event_DemEventParameter_002: start-on-event=DemSatellite_0InternalBehavior/GetEventStatus, operation=Event_DemEventParameter_002.GetEventStatus
        OpEventGetEventStatus_GetEventStatus_EvtInfo_DemEventParameter_003: start-on-event=DemSatellite_0InternalBehavior/GetEventStatus, operation=EvtInfo_DemEventParameter_003.GetEventStatus
        OpEventGetEventStatus_GetEventStatus_Event_DemEventParameter_003: start-on-event=DemSatellite_0InternalBehavior/GetEventStatus, operation=Event_DemEventParameter_003.GetEventStatus
        OpEventGetEventStatus_GetEventStatus_EvtInfo_DemEventParameter_004: start-on-event=DemSatellite_0InternalBehavior/GetEventStatus, operation=EvtInfo_DemEventParameter_004.GetEventStatus
        OpEventGetEventStatus_GetEventStatus_Event_DemEventParameter_004: start-on-event=DemSatellite_0InternalBehavior/GetEventStatus, operation=Event_DemEventParameter_004.GetEventStatus
        OpEventGetEventStatus_GetEventStatus_EvtInfo_DemEventParameter_005: start-on-event=DemSatellite_0InternalBehavior/GetEventStatus, operation=EvtInfo_DemEventParameter_005.GetEventStatus
        OpEventGetEventStatus_GetEventStatus_Event_DemEventParameter_005: start-on-event=DemSatellite_0InternalBehavior/GetEventStatus, operation=Event_DemEventParameter_005.GetEventStatus
        OpEventGetEventStatus_GetEventStatus_EvtInfo_DemEventParameter_006: start-on-event=DemSatellite_0InternalBehavior/GetEventStatus, operation=EvtInfo_DemEventParameter_006.GetEventStatus
        OpEventGetEventStatus_GetEventStatus_Event_DemEventParameter_006: start-on-event=DemSatellite_0InternalBehavior/GetEventStatus, operation=Event_DemEventParameter_006.GetEventStatus
        OpEventGetEventStatus_GetEventStatus_EvtInfo_DemEventParameter_007: start-on-event=DemSatellite_0InternalBehavior/GetEventStatus, operation=EvtInfo_DemEventParameter_007.GetEventStatus
        OpEventGetEventStatus_GetEventStatus_Event_DemEventParameter_007: start-on-event=DemSatellite_0InternalBehavior/GetEventStatus, operation=Event_DemEventParameter_007.GetEventStatus
        OpEventGetEventStatus_GetEventStatus_EvtInfo_DemEventParameter_008: start-on-event=DemSatellite_0InternalBehavior/GetEventStatus, operation=EvtInfo_DemEventParameter_008.GetEventStatus
        OpEventGetEventStatus_GetEventStatus_Event_DemEventParameter_008: start-on-event=DemSatellite_0InternalBehavior/GetEventStatus, operation=Event_DemEventParameter_008.GetEventStatus
        OpEventGetEventStatus_GetEventStatus_EvtInfo_DemEventParameter_009: start-on-event=DemSatellite_0InternalBehavior/GetEventStatus, operation=EvtInfo_DemEventParameter_009.GetEventStatus
        OpEventGetEventStatus_GetEventStatus_Event_DemEventParameter_009: start-on-event=DemSatellite_0InternalBehavior/GetEventStatus, operation=Event_DemEventParameter_009.GetEventStatus
        OpEventGetEventStatus_GetEventStatus_EvtInfo_DemEventParameter_010: start-on-event=DemSatellite_0InternalBehavior/GetEventStatus, operation=EvtInfo_DemEventParameter_010.GetEventStatus
        OpEventGetEventStatus_GetEventStatus_Event_DemEventParameter_010: start-on-event=DemSatellite_0InternalBehavior/GetEventStatus, operation=Event_DemEventParameter_010.GetEventStatus
        OpEventGetEventStatus_GetEventStatus_EvtInfo_DemEventParameter_011: start-on-event=DemSatellite_0InternalBehavior/GetEventStatus, operation=EvtInfo_DemEventParameter_011.GetEventStatus
        OpEventGetEventStatus_GetEventStatus_Event_DemEventParameter_011: start-on-event=DemSatellite_0InternalBehavior/GetEventStatus, operation=Event_DemEventParameter_011.GetEventStatus
        OpEventGetEventFailed_GetEventFailed_EvtInfo_DemEventParameter_002: start-on-event=DemSatellite_0InternalBehavior/GetEventFailed, operation=EvtInfo_DemEventParameter_002.GetEventFailed
        OpEventGetEventFailed_GetEventFailed_Event_DemEventParameter_002: start-on-event=DemSatellite_0InternalBehavior/GetEventFailed, operation=Event_DemEventParameter_002.GetEventFailed
        OpEventGetEventFailed_GetEventFailed_EvtInfo_DemEventParameter_003: start-on-event=DemSatellite_0InternalBehavior/GetEventFailed, operation=EvtInfo_DemEventParameter_003.GetEventFailed
        OpEventGetEventFailed_GetEventFailed_Event_DemEventParameter_003: start-on-event=DemSatellite_0InternalBehavior/GetEventFailed, operation=Event_DemEventParameter_003.GetEventFailed
        OpEventGetEventFailed_GetEventFailed_EvtInfo_DemEventParameter_004: start-on-event=DemSatellite_0InternalBehavior/GetEventFailed, operation=EvtInfo_DemEventParameter_004.GetEventFailed
        OpEventGetEventFailed_GetEventFailed_Event_DemEventParameter_004: start-on-event=DemSatellite_0InternalBehavior/GetEventFailed, operation=Event_DemEventParameter_004.GetEventFailed
        OpEventGetEventFailed_GetEventFailed_EvtInfo_DemEventParameter_005: start-on-event=DemSatellite_0InternalBehavior/GetEventFailed, operation=EvtInfo_DemEventParameter_005.GetEventFailed
        OpEventGetEventFailed_GetEventFailed_Event_DemEventParameter_005: start-on-event=DemSatellite_0InternalBehavior/GetEventFailed, operation=Event_DemEventParameter_005.GetEventFailed
        OpEventGetEventFailed_GetEventFailed_EvtInfo_DemEventParameter_006: start-on-event=DemSatellite_0InternalBehavior/GetEventFailed, operation=EvtInfo_DemEventParameter_006.GetEventFailed
        OpEventGetEventFailed_GetEventFailed_Event_DemEventParameter_006: start-on-event=DemSatellite_0InternalBehavior/GetEventFailed, operation=Event_DemEventParameter_006.GetEventFailed
        OpEventGetEventFailed_GetEventFailed_EvtInfo_DemEventParameter_007: start-on-event=DemSatellite_0InternalBehavior/GetEventFailed, operation=EvtInfo_DemEventParameter_007.GetEventFailed
        OpEventGetEventFailed_GetEventFailed_Event_DemEventParameter_007: start-on-event=DemSatellite_0InternalBehavior/GetEventFailed, operation=Event_DemEventParameter_007.GetEventFailed
        OpEventGetEventFailed_GetEventFailed_EvtInfo_DemEventParameter_008: start-on-event=DemSatellite_0InternalBehavior/GetEventFailed, operation=EvtInfo_DemEventParameter_008.GetEventFailed
        OpEventGetEventFailed_GetEventFailed_Event_DemEventParameter_008: start-on-event=DemSatellite_0InternalBehavior/GetEventFailed, operation=Event_DemEventParameter_008.GetEventFailed
        OpEventGetEventFailed_GetEventFailed_EvtInfo_DemEventParameter_009: start-on-event=DemSatellite_0InternalBehavior/GetEventFailed, operation=EvtInfo_DemEventParameter_009.GetEventFailed
        OpEventGetEventFailed_GetEventFailed_Event_DemEventParameter_009: start-on-event=DemSatellite_0InternalBehavior/GetEventFailed, operation=Event_DemEventParameter_009.GetEventFailed
        OpEventGetEventFailed_GetEventFailed_EvtInfo_DemEventParameter_010: start-on-event=DemSatellite_0InternalBehavior/GetEventFailed, operation=EvtInfo_DemEventParameter_010.GetEventFailed
        OpEventGetEventFailed_GetEventFailed_Event_DemEventParameter_010: start-on-event=DemSatellite_0InternalBehavior/GetEventFailed, operation=Event_DemEventParameter_010.GetEventFailed
        OpEventGetEventFailed_GetEventFailed_EvtInfo_DemEventParameter_011: start-on-event=DemSatellite_0InternalBehavior/GetEventFailed, operation=EvtInfo_DemEventParameter_011.GetEventFailed
        OpEventGetEventFailed_GetEventFailed_Event_DemEventParameter_011: start-on-event=DemSatellite_0InternalBehavior/GetEventFailed, operation=Event_DemEventParameter_011.GetEventFailed
        OpEventGetEventTested_GetEventTested_EvtInfo_DemEventParameter_002: start-on-event=DemSatellite_0InternalBehavior/GetEventTested, operation=EvtInfo_DemEventParameter_002.GetEventTested
        OpEventGetEventTested_GetEventTested_Event_DemEventParameter_002: start-on-event=DemSatellite_0InternalBehavior/GetEventTested, operation=Event_DemEventParameter_002.GetEventTested
        OpEventGetEventTested_GetEventTested_EvtInfo_DemEventParameter_003: start-on-event=DemSatellite_0InternalBehavior/GetEventTested, operation=EvtInfo_DemEventParameter_003.GetEventTested
        OpEventGetEventTested_GetEventTested_Event_DemEventParameter_003: start-on-event=DemSatellite_0InternalBehavior/GetEventTested, operation=Event_DemEventParameter_003.GetEventTested
        OpEventGetEventTested_GetEventTested_EvtInfo_DemEventParameter_004: start-on-event=DemSatellite_0InternalBehavior/GetEventTested, operation=EvtInfo_DemEventParameter_004.GetEventTested
        OpEventGetEventTested_GetEventTested_Event_DemEventParameter_004: start-on-event=DemSatellite_0InternalBehavior/GetEventTested, operation=Event_DemEventParameter_004.GetEventTested
        OpEventGetEventTested_GetEventTested_EvtInfo_DemEventParameter_005: start-on-event=DemSatellite_0InternalBehavior/GetEventTested, operation=EvtInfo_DemEventParameter_005.GetEventTested
        OpEventGetEventTested_GetEventTested_Event_DemEventParameter_005: start-on-event=DemSatellite_0InternalBehavior/GetEventTested, operation=Event_DemEventParameter_005.GetEventTested
        OpEventGetEventTested_GetEventTested_EvtInfo_DemEventParameter_006: start-on-event=DemSatellite_0InternalBehavior/GetEventTested, operation=EvtInfo_DemEventParameter_006.GetEventTested
        OpEventGetEventTested_GetEventTested_Event_DemEventParameter_006: start-on-event=DemSatellite_0InternalBehavior/GetEventTested, operation=Event_DemEventParameter_006.GetEventTested
        OpEventGetEventTested_GetEventTested_EvtInfo_DemEventParameter_007: start-on-event=DemSatellite_0InternalBehavior/GetEventTested, operation=EvtInfo_DemEventParameter_007.GetEventTested
        OpEventGetEventTested_GetEventTested_Event_DemEventParameter_007: start-on-event=DemSatellite_0InternalBehavior/GetEventTested, operation=Event_DemEventParameter_007.GetEventTested
        OpEventGetEventTested_GetEventTested_EvtInfo_DemEventParameter_008: start-on-event=DemSatellite_0InternalBehavior/GetEventTested, operation=EvtInfo_DemEventParameter_008.GetEventTested
        OpEventGetEventTested_GetEventTested_Event_DemEventParameter_008: start-on-event=DemSatellite_0InternalBehavior/GetEventTested, operation=Event_DemEventParameter_008.GetEventTested
        OpEventGetEventTested_GetEventTested_EvtInfo_DemEventParameter_009: start-on-event=DemSatellite_0InternalBehavior/GetEventTested, operation=EvtInfo_DemEventParameter_009.GetEventTested
        OpEventGetEventTested_GetEventTested_Event_DemEventParameter_009: start-on-event=DemSatellite_0InternalBehavior/GetEventTested, operation=Event_DemEventParameter_009.GetEventTested
        OpEventGetEventTested_GetEventTested_EvtInfo_DemEventParameter_010: start-on-event=DemSatellite_0InternalBehavior/GetEventTested, operation=EvtInfo_DemEventParameter_010.GetEventTested
        OpEventGetEventTested_GetEventTested_Event_DemEventParameter_010: start-on-event=DemSatellite_0InternalBehavior/GetEventTested, operation=Event_DemEventParameter_010.GetEventTested
        OpEventGetEventTested_GetEventTested_EvtInfo_DemEventParameter_011: start-on-event=DemSatellite_0InternalBehavior/GetEventTested, operation=EvtInfo_DemEventParameter_011.GetEventTested
        OpEventGetEventTested_GetEventTested_Event_DemEventParameter_011: start-on-event=DemSatellite_0InternalBehavior/GetEventTested, operation=Event_DemEventParameter_011.GetEventTested
        OpEventGetDTCOfEvent_GetDTCOfEvent_EvtInfo_DemEventParameter_002: start-on-event=DemSatellite_0InternalBehavior/GetDTCOfEvent, operation=EvtInfo_DemEventParameter_002.GetDTCOfEvent
        OpEventGetDTCOfEvent_GetDTCOfEvent_Event_DemEventParameter_002: start-on-event=DemSatellite_0InternalBehavior/GetDTCOfEvent, operation=Event_DemEventParameter_002.GetDTCOfEvent
        OpEventGetDTCOfEvent_GetDTCOfEvent_EvtInfo_DemEventParameter_003: start-on-event=DemSatellite_0InternalBehavior/GetDTCOfEvent, operation=EvtInfo_DemEventParameter_003.GetDTCOfEvent
        OpEventGetDTCOfEvent_GetDTCOfEvent_Event_DemEventParameter_003: start-on-event=DemSatellite_0InternalBehavior/GetDTCOfEvent, operation=Event_DemEventParameter_003.GetDTCOfEvent
        OpEventGetDTCOfEvent_GetDTCOfEvent_EvtInfo_DemEventParameter_004: start-on-event=DemSatellite_0InternalBehavior/GetDTCOfEvent, operation=EvtInfo_DemEventParameter_004.GetDTCOfEvent
        OpEventGetDTCOfEvent_GetDTCOfEvent_Event_DemEventParameter_004: start-on-event=DemSatellite_0InternalBehavior/GetDTCOfEvent, operation=Event_DemEventParameter_004.GetDTCOfEvent
        OpEventGetDTCOfEvent_GetDTCOfEvent_EvtInfo_DemEventParameter_005: start-on-event=DemSatellite_0InternalBehavior/GetDTCOfEvent, operation=EvtInfo_DemEventParameter_005.GetDTCOfEvent
        OpEventGetDTCOfEvent_GetDTCOfEvent_Event_DemEventParameter_005: start-on-event=DemSatellite_0InternalBehavior/GetDTCOfEvent, operation=Event_DemEventParameter_005.GetDTCOfEvent
        OpEventGetDTCOfEvent_GetDTCOfEvent_EvtInfo_DemEventParameter_006: start-on-event=DemSatellite_0InternalBehavior/GetDTCOfEvent, operation=EvtInfo_DemEventParameter_006.GetDTCOfEvent
        OpEventGetDTCOfEvent_GetDTCOfEvent_Event_DemEventParameter_006: start-on-event=DemSatellite_0InternalBehavior/GetDTCOfEvent, operation=Event_DemEventParameter_006.GetDTCOfEvent
        OpEventGetDTCOfEvent_GetDTCOfEvent_EvtInfo_DemEventParameter_007: start-on-event=DemSatellite_0InternalBehavior/GetDTCOfEvent, operation=EvtInfo_DemEventParameter_007.GetDTCOfEvent
        OpEventGetDTCOfEvent_GetDTCOfEvent_Event_DemEventParameter_007: start-on-event=DemSatellite_0InternalBehavior/GetDTCOfEvent, operation=Event_DemEventParameter_007.GetDTCOfEvent
        OpEventGetDTCOfEvent_GetDTCOfEvent_EvtInfo_DemEventParameter_008: start-on-event=DemSatellite_0InternalBehavior/GetDTCOfEvent, operation=EvtInfo_DemEventParameter_008.GetDTCOfEvent
        OpEventGetDTCOfEvent_GetDTCOfEvent_Event_DemEventParameter_008: start-on-event=DemSatellite_0InternalBehavior/GetDTCOfEvent, operation=Event_DemEventParameter_008.GetDTCOfEvent
        OpEventGetDTCOfEvent_GetDTCOfEvent_EvtInfo_DemEventParameter_009: start-on-event=DemSatellite_0InternalBehavior/GetDTCOfEvent, operation=EvtInfo_DemEventParameter_009.GetDTCOfEvent
        OpEventGetDTCOfEvent_GetDTCOfEvent_Event_DemEventParameter_009: start-on-event=DemSatellite_0InternalBehavior/GetDTCOfEvent, operation=Event_DemEventParameter_009.GetDTCOfEvent
        OpEventGetDTCOfEvent_GetDTCOfEvent_EvtInfo_DemEventParameter_010: start-on-event=DemSatellite_0InternalBehavior/GetDTCOfEvent, operation=EvtInfo_DemEventParameter_010.GetDTCOfEvent
        OpEventGetDTCOfEvent_GetDTCOfEvent_Event_DemEventParameter_010: start-on-event=DemSatellite_0InternalBehavior/GetDTCOfEvent, operation=Event_DemEventParameter_010.GetDTCOfEvent
        OpEventGetDTCOfEvent_GetDTCOfEvent_EvtInfo_DemEventParameter_011: start-on-event=DemSatellite_0InternalBehavior/GetDTCOfEvent, operation=EvtInfo_DemEventParameter_011.GetDTCOfEvent
        OpEventGetDTCOfEvent_GetDTCOfEvent_Event_DemEventParameter_011: start-on-event=DemSatellite_0InternalBehavior/GetDTCOfEvent, operation=Event_DemEventParameter_011.GetDTCOfEvent
        OpEventGetFaultDetectionCounter_GetFaultDetectionCounter_EvtInfo_DemEventParameter_002: start-on-event=DemSatellite_0InternalBehavior/GetFaultDetectionCounter, operation=EvtInfo_DemEventParameter_002.GetFaultDetectionCounter
        OpEventGetFaultDetectionCounter_GetFaultDetectionCounter_Event_DemEventParameter_002: start-on-event=DemSatellite_0InternalBehavior/GetFaultDetectionCounter, operation=Event_DemEventParameter_002.GetFaultDetectionCounter
        OpEventGetFaultDetectionCounter_GetFaultDetectionCounter_EvtInfo_DemEventParameter_003: start-on-event=DemSatellite_0InternalBehavior/GetFaultDetectionCounter, operation=EvtInfo_DemEventParameter_003.GetFaultDetectionCounter
        OpEventGetFaultDetectionCounter_GetFaultDetectionCounter_Event_DemEventParameter_003: start-on-event=DemSatellite_0InternalBehavior/GetFaultDetectionCounter, operation=Event_DemEventParameter_003.GetFaultDetectionCounter
        OpEventGetFaultDetectionCounter_GetFaultDetectionCounter_EvtInfo_DemEventParameter_004: start-on-event=DemSatellite_0InternalBehavior/GetFaultDetectionCounter, operation=EvtInfo_DemEventParameter_004.GetFaultDetectionCounter
        OpEventGetFaultDetectionCounter_GetFaultDetectionCounter_Event_DemEventParameter_004: start-on-event=DemSatellite_0InternalBehavior/GetFaultDetectionCounter, operation=Event_DemEventParameter_004.GetFaultDetectionCounter
        OpEventGetFaultDetectionCounter_GetFaultDetectionCounter_EvtInfo_DemEventParameter_005: start-on-event=DemSatellite_0InternalBehavior/GetFaultDetectionCounter, operation=EvtInfo_DemEventParameter_005.GetFaultDetectionCounter
        OpEventGetFaultDetectionCounter_GetFaultDetectionCounter_Event_DemEventParameter_005: start-on-event=DemSatellite_0InternalBehavior/GetFaultDetectionCounter, operation=Event_DemEventParameter_005.GetFaultDetectionCounter
        OpEventGetFaultDetectionCounter_GetFaultDetectionCounter_EvtInfo_DemEventParameter_006: start-on-event=DemSatellite_0InternalBehavior/GetFaultDetectionCounter, operation=EvtInfo_DemEventParameter_006.GetFaultDetectionCounter
        OpEventGetFaultDetectionCounter_GetFaultDetectionCounter_Event_DemEventParameter_006: start-on-event=DemSatellite_0InternalBehavior/GetFaultDetectionCounter, operation=Event_DemEventParameter_006.GetFaultDetectionCounter
        OpEventGetFaultDetectionCounter_GetFaultDetectionCounter_EvtInfo_DemEventParameter_007: start-on-event=DemSatellite_0InternalBehavior/GetFaultDetectionCounter, operation=EvtInfo_DemEventParameter_007.GetFaultDetectionCounter
        OpEventGetFaultDetectionCounter_GetFaultDetectionCounter_Event_DemEventParameter_007: start-on-event=DemSatellite_0InternalBehavior/GetFaultDetectionCounter, operation=Event_DemEventParameter_007.GetFaultDetectionCounter
        OpEventGetFaultDetectionCounter_GetFaultDetectionCounter_EvtInfo_DemEventParameter_008: start-on-event=DemSatellite_0InternalBehavior/GetFaultDetectionCounter, operation=EvtInfo_DemEventParameter_008.GetFaultDetectionCounter
        OpEventGetFaultDetectionCounter_GetFaultDetectionCounter_Event_DemEventParameter_008: start-on-event=DemSatellite_0InternalBehavior/GetFaultDetectionCounter, operation=Event_DemEventParameter_008.GetFaultDetectionCounter
        OpEventGetFaultDetectionCounter_GetFaultDetectionCounter_EvtInfo_DemEventParameter_009: start-on-event=DemSatellite_0InternalBehavior/GetFaultDetectionCounter, operation=EvtInfo_DemEventParameter_009.GetFaultDetectionCounter
        OpEventGetFaultDetectionCounter_GetFaultDetectionCounter_Event_DemEventParameter_009: start-on-event=DemSatellite_0InternalBehavior/GetFaultDetectionCounter, operation=Event_DemEventParameter_009.GetFaultDetectionCounter
        OpEventGetFaultDetectionCounter_GetFaultDetectionCounter_EvtInfo_DemEventParameter_010: start-on-event=DemSatellite_0InternalBehavior/GetFaultDetectionCounter, operation=EvtInfo_DemEventParameter_010.GetFaultDetectionCounter
        OpEventGetFaultDetectionCounter_GetFaultDetectionCounter_Event_DemEventParameter_010: start-on-event=DemSatellite_0InternalBehavior/GetFaultDetectionCounter, operation=Event_DemEventParameter_010.GetFaultDetectionCounter
        OpEventGetFaultDetectionCounter_GetFaultDetectionCounter_EvtInfo_DemEventParameter_011: start-on-event=DemSatellite_0InternalBehavior/GetFaultDetectionCounter, operation=EvtInfo_DemEventParameter_011.GetFaultDetectionCounter
        OpEventGetFaultDetectionCounter_GetFaultDetectionCounter_Event_DemEventParameter_011: start-on-event=DemSatellite_0InternalBehavior/GetFaultDetectionCounter, operation=Event_DemEventParameter_011.GetFaultDetectionCounter
        OpEventGetEventFreezeFrameDataEx_GetEventFreezeFrameDataEx_EvtInfo_DemEventParameter_002: start-on-event=DemSatellite_0InternalBehavior/GetEventFreezeFrameDataEx, operation=EvtInfo_DemEventParameter_002.GetEventFreezeFrameDataEx
        OpEventGetEventFreezeFrameDataEx_GetEventFreezeFrameDataEx_Event_DemEventParameter_002: start-on-event=DemSatellite_0InternalBehavior/GetEventFreezeFrameDataEx, operation=Event_DemEventParameter_002.GetEventFreezeFrameDataEx
        OpEventGetEventFreezeFrameDataEx_GetEventFreezeFrameDataEx_EvtInfo_DemEventParameter_003: start-on-event=DemSatellite_0InternalBehavior/GetEventFreezeFrameDataEx, operation=EvtInfo_DemEventParameter_003.GetEventFreezeFrameDataEx
        OpEventGetEventFreezeFrameDataEx_GetEventFreezeFrameDataEx_Event_DemEventParameter_003: start-on-event=DemSatellite_0InternalBehavior/GetEventFreezeFrameDataEx, operation=Event_DemEventParameter_003.GetEventFreezeFrameDataEx
        OpEventGetEventFreezeFrameDataEx_GetEventFreezeFrameDataEx_EvtInfo_DemEventParameter_004: start-on-event=DemSatellite_0InternalBehavior/GetEventFreezeFrameDataEx, operation=EvtInfo_DemEventParameter_004.GetEventFreezeFrameDataEx
        OpEventGetEventFreezeFrameDataEx_GetEventFreezeFrameDataEx_Event_DemEventParameter_004: start-on-event=DemSatellite_0InternalBehavior/GetEventFreezeFrameDataEx, operation=Event_DemEventParameter_004.GetEventFreezeFrameDataEx
        OpEventGetEventFreezeFrameDataEx_GetEventFreezeFrameDataEx_EvtInfo_DemEventParameter_005: start-on-event=DemSatellite_0InternalBehavior/GetEventFreezeFrameDataEx, operation=EvtInfo_DemEventParameter_005.GetEventFreezeFrameDataEx
        OpEventGetEventFreezeFrameDataEx_GetEventFreezeFrameDataEx_Event_DemEventParameter_005: start-on-event=DemSatellite_0InternalBehavior/GetEventFreezeFrameDataEx, operation=Event_DemEventParameter_005.GetEventFreezeFrameDataEx
        OpEventGetEventFreezeFrameDataEx_GetEventFreezeFrameDataEx_EvtInfo_DemEventParameter_006: start-on-event=DemSatellite_0InternalBehavior/GetEventFreezeFrameDataEx, operation=EvtInfo_DemEventParameter_006.GetEventFreezeFrameDataEx
        OpEventGetEventFreezeFrameDataEx_GetEventFreezeFrameDataEx_Event_DemEventParameter_006: start-on-event=DemSatellite_0InternalBehavior/GetEventFreezeFrameDataEx, operation=Event_DemEventParameter_006.GetEventFreezeFrameDataEx
        OpEventGetEventFreezeFrameDataEx_GetEventFreezeFrameDataEx_EvtInfo_DemEventParameter_007: start-on-event=DemSatellite_0InternalBehavior/GetEventFreezeFrameDataEx, operation=EvtInfo_DemEventParameter_007.GetEventFreezeFrameDataEx
        OpEventGetEventFreezeFrameDataEx_GetEventFreezeFrameDataEx_Event_DemEventParameter_007: start-on-event=DemSatellite_0InternalBehavior/GetEventFreezeFrameDataEx, operation=Event_DemEventParameter_007.GetEventFreezeFrameDataEx
        OpEventGetEventFreezeFrameDataEx_GetEventFreezeFrameDataEx_EvtInfo_DemEventParameter_008: start-on-event=DemSatellite_0InternalBehavior/GetEventFreezeFrameDataEx, operation=EvtInfo_DemEventParameter_008.GetEventFreezeFrameDataEx
        OpEventGetEventFreezeFrameDataEx_GetEventFreezeFrameDataEx_Event_DemEventParameter_008: start-on-event=DemSatellite_0InternalBehavior/GetEventFreezeFrameDataEx, operation=Event_DemEventParameter_008.GetEventFreezeFrameDataEx
        OpEventGetEventFreezeFrameDataEx_GetEventFreezeFrameDataEx_EvtInfo_DemEventParameter_009: start-on-event=DemSatellite_0InternalBehavior/GetEventFreezeFrameDataEx, operation=EvtInfo_DemEventParameter_009.GetEventFreezeFrameDataEx
        OpEventGetEventFreezeFrameDataEx_GetEventFreezeFrameDataEx_Event_DemEventParameter_009: start-on-event=DemSatellite_0InternalBehavior/GetEventFreezeFrameDataEx, operation=Event_DemEventParameter_009.GetEventFreezeFrameDataEx
        OpEventGetEventFreezeFrameDataEx_GetEventFreezeFrameDataEx_EvtInfo_DemEventParameter_010: start-on-event=DemSatellite_0InternalBehavior/GetEventFreezeFrameDataEx, operation=EvtInfo_DemEventParameter_010.GetEventFreezeFrameDataEx
        OpEventGetEventFreezeFrameDataEx_GetEventFreezeFrameDataEx_Event_DemEventParameter_010: start-on-event=DemSatellite_0InternalBehavior/GetEventFreezeFrameDataEx, operation=Event_DemEventParameter_010.GetEventFreezeFrameDataEx
        OpEventGetEventFreezeFrameDataEx_GetEventFreezeFrameDataEx_EvtInfo_DemEventParameter_011: start-on-event=DemSatellite_0InternalBehavior/GetEventFreezeFrameDataEx, operation=EvtInfo_DemEventParameter_011.GetEventFreezeFrameDataEx
        OpEventGetEventFreezeFrameDataEx_GetEventFreezeFrameDataEx_Event_DemEventParameter_011: start-on-event=DemSatellite_0InternalBehavior/GetEventFreezeFrameDataEx, operation=Event_DemEventParameter_011.GetEventFreezeFrameDataEx
        OpEventGetEventExtendedDataRecordEx_GetEventExtendedDataRecordEx_EvtInfo_DemEventParameter_002: start-on-event=DemSatellite_0InternalBehavior/GetEventExtendedDataRecordEx, operation=EvtInfo_DemEventParameter_002.GetEventExtendedDataRecordEx
        OpEventGetEventExtendedDataRecordEx_GetEventExtendedDataRecordEx_Event_DemEventParameter_002: start-on-event=DemSatellite_0InternalBehavior/GetEventExtendedDataRecordEx, operation=Event_DemEventParameter_002.GetEventExtendedDataRecordEx
        OpEventGetEventExtendedDataRecordEx_GetEventExtendedDataRecordEx_EvtInfo_DemEventParameter_003: start-on-event=DemSatellite_0InternalBehavior/GetEventExtendedDataRecordEx, operation=EvtInfo_DemEventParameter_003.GetEventExtendedDataRecordEx
        OpEventGetEventExtendedDataRecordEx_GetEventExtendedDataRecordEx_Event_DemEventParameter_003: start-on-event=DemSatellite_0InternalBehavior/GetEventExtendedDataRecordEx, operation=Event_DemEventParameter_003.GetEventExtendedDataRecordEx
        OpEventGetEventExtendedDataRecordEx_GetEventExtendedDataRecordEx_EvtInfo_DemEventParameter_004: start-on-event=DemSatellite_0InternalBehavior/GetEventExtendedDataRecordEx, operation=EvtInfo_DemEventParameter_004.GetEventExtendedDataRecordEx
        OpEventGetEventExtendedDataRecordEx_GetEventExtendedDataRecordEx_Event_DemEventParameter_004: start-on-event=DemSatellite_0InternalBehavior/GetEventExtendedDataRecordEx, operation=Event_DemEventParameter_004.GetEventExtendedDataRecordEx
        OpEventGetEventExtendedDataRecordEx_GetEventExtendedDataRecordEx_EvtInfo_DemEventParameter_005: start-on-event=DemSatellite_0InternalBehavior/GetEventExtendedDataRecordEx, operation=EvtInfo_DemEventParameter_005.GetEventExtendedDataRecordEx
        OpEventGetEventExtendedDataRecordEx_GetEventExtendedDataRecordEx_Event_DemEventParameter_005: start-on-event=DemSatellite_0InternalBehavior/GetEventExtendedDataRecordEx, operation=Event_DemEventParameter_005.GetEventExtendedDataRecordEx
        OpEventGetEventExtendedDataRecordEx_GetEventExtendedDataRecordEx_EvtInfo_DemEventParameter_006: start-on-event=DemSatellite_0InternalBehavior/GetEventExtendedDataRecordEx, operation=EvtInfo_DemEventParameter_006.GetEventExtendedDataRecordEx
        OpEventGetEventExtendedDataRecordEx_GetEventExtendedDataRecordEx_Event_DemEventParameter_006: start-on-event=DemSatellite_0InternalBehavior/GetEventExtendedDataRecordEx, operation=Event_DemEventParameter_006.GetEventExtendedDataRecordEx
        OpEventGetEventExtendedDataRecordEx_GetEventExtendedDataRecordEx_EvtInfo_DemEventParameter_007: start-on-event=DemSatellite_0InternalBehavior/GetEventExtendedDataRecordEx, operation=EvtInfo_DemEventParameter_007.GetEventExtendedDataRecordEx
        OpEventGetEventExtendedDataRecordEx_GetEventExtendedDataRecordEx_Event_DemEventParameter_007: start-on-event=DemSatellite_0InternalBehavior/GetEventExtendedDataRecordEx, operation=Event_DemEventParameter_007.GetEventExtendedDataRecordEx
        OpEventGetEventExtendedDataRecordEx_GetEventExtendedDataRecordEx_EvtInfo_DemEventParameter_008: start-on-event=DemSatellite_0InternalBehavior/GetEventExtendedDataRecordEx, operation=EvtInfo_DemEventParameter_008.GetEventExtendedDataRecordEx
        OpEventGetEventExtendedDataRecordEx_GetEventExtendedDataRecordEx_Event_DemEventParameter_008: start-on-event=DemSatellite_0InternalBehavior/GetEventExtendedDataRecordEx, operation=Event_DemEventParameter_008.GetEventExtendedDataRecordEx
        OpEventGetEventExtendedDataRecordEx_GetEventExtendedDataRecordEx_EvtInfo_DemEventParameter_009: start-on-event=DemSatellite_0InternalBehavior/GetEventExtendedDataRecordEx, operation=EvtInfo_DemEventParameter_009.GetEventExtendedDataRecordEx
        OpEventGetEventExtendedDataRecordEx_GetEventExtendedDataRecordEx_Event_DemEventParameter_009: start-on-event=DemSatellite_0InternalBehavior/GetEventExtendedDataRecordEx, operation=Event_DemEventParameter_009.GetEventExtendedDataRecordEx
        OpEventGetEventExtendedDataRecordEx_GetEventExtendedDataRecordEx_EvtInfo_DemEventParameter_010: start-on-event=DemSatellite_0InternalBehavior/GetEventExtendedDataRecordEx, operation=EvtInfo_DemEventParameter_010.GetEventExtendedDataRecordEx
        OpEventGetEventExtendedDataRecordEx_GetEventExtendedDataRecordEx_Event_DemEventParameter_010: start-on-event=DemSatellite_0InternalBehavior/GetEventExtendedDataRecordEx, operation=Event_DemEventParameter_010.GetEventExtendedDataRecordEx
        OpEventGetEventExtendedDataRecordEx_GetEventExtendedDataRecordEx_EvtInfo_DemEventParameter_011: start-on-event=DemSatellite_0InternalBehavior/GetEventExtendedDataRecordEx, operation=EvtInfo_DemEventParameter_011.GetEventExtendedDataRecordEx
        OpEventGetEventExtendedDataRecordEx_GetEventExtendedDataRecordEx_Event_DemEventParameter_011: start-on-event=DemSatellite_0InternalBehavior/GetEventExtendedDataRecordEx, operation=Event_DemEventParameter_011.GetEventExtendedDataRecordEx
        OpEventGetEventEnableCondition_GetEventEnableCondition_EvtInfo_DemEventParameter_{002..011}: start-on-event=DemSatellite_0InternalBehavior/GetEventEnableCondition, operation=EvtInfo_DemEventParameter_{002..011}.GetEventEnableCondition
        OpEventGetDebouncingOfEvent_GetDebouncingOfEvent_EvtInfo_DemEventParameter_{002..011}: start-on-event=DemSatellite_0InternalBehavior/GetDebouncingOfEvent, operation=EvtInfo_DemEventParameter_{002..011}.GetDebouncingOfEvent
        OpEventGetMonitorStatus_GetMonitorStatus_EvtInfo_DemEventParameter_{002..011}: start-on-event=DemSatellite_0InternalBehavior/GetMonitorStatus, operation=EvtInfo_DemEventParameter_{002..011}.GetMonitorStatus
        OpEventSetEventStatus_SetEventStatus_Event_DemEventParameter_{002..011}: start-on-event=SetEventStatus, operation=Event_DemEventParameter_{002..011}.SetEventStatus
        OpEventResetEventStatus_ResetEventStatus_Event_DemEventParameter_{002..011}: start-on-event=ResetEventStatus, operation=Event_DemEventParameter_{002..011}.ResetEventStatus
        OpEventResetEventDebounceStatus_ResetEventDebounceStatus_Event_DemEventParameter_{002..011}: start-on-event=ResetEventDebounceStatus, operation=Event_DemEventParameter_{002..011}.ResetEventDebounceStatus
      port-api-options:
        {enable-take-address=true, indirect-api=false, port-defined-argument-value{value=1, value-type=Dem_EventIdType}, port=EvtInfo_DemEventParameter}
        {enable-take-address=true, indirect-api=false, port-defined-argument-value{value=1, value-type=Dem_EventIdType}, port=Event_DemEventParameter}
        enable-take-address=true, indirect-api=false, port=DemSatellite_0/GeneralEventInfo
        {enable-take-address=true, indirect-api=false, port-defined-argument-value{value=20, value-type=Dem_EventIdType}, port=EvtInfo_AutoCreatedDemEvent_EcuMConfiguration_ECUM_E_ALL_RUN_REQUESTS_KILLED}
        {enable-take-address=true, indirect-api=false, port-defined-argument-value{value=21, value-type=Dem_EventIdType}, port=EvtInfo_AutoCreatedDemEvent_EcuMConfiguration_ECUM_E_CONFIGURATION_DATA_INCONSISTENT}
        {enable-take-address=true, indirect-api=false, port-defined-argument-value{value=23, value-type=Dem_EventIdType}, port=EvtInfo_AutoCreatedDemEvent_EcuMConfiguration_ECUM_E_RAM_CHECK_FAILED}
        {enable-take-address=true, indirect-api=false, port-defined-argument-value{value=22, value-type=Dem_EventIdType}, port=EvtInfo_AutoCreatedDemEvent_EcuMConfiguration_ECUM_E_IMPROPER_CALLER}
        {enable-take-address=true, indirect-api=false, port-defined-argument-value{value=24, value-type=Dem_EventIdType}, port=EvtInfo_AutoCreatedDemEvent_FlsConfigSet_FLS_E_COMPARE_FAILED}
        {enable-take-address=true, indirect-api=false, port-defined-argument-value{value=25, value-type=Dem_EventIdType}, port=EvtInfo_AutoCreatedDemEvent_FlsConfigSet_FLS_E_ERASE_FAILED}
        {enable-take-address=true, indirect-api=false, port-defined-argument-value{value=26, value-type=Dem_EventIdType}, port=EvtInfo_AutoCreatedDemEvent_FlsConfigSet_FLS_E_READ_FAILED}
        {enable-take-address=true, indirect-api=false, port-defined-argument-value{value=27, value-type=Dem_EventIdType}, port=EvtInfo_AutoCreatedDemEvent_FlsConfigSet_FLS_E_UNEXPECTED_FLASH_ID}
        {enable-take-address=true, indirect-api=false, port-defined-argument-value{value=28, value-type=Dem_EventIdType}, port=EvtInfo_AutoCreatedDemEvent_FlsConfigSet_FLS_E_WRITE_FAILED}
        {enable-take-address=true, indirect-api=false, port-defined-argument-value{value=30, value-type=Dem_EventIdType}, port=EvtInfo_AutoCreatedDemEvent_contr_EPS_A_FlexRay_FrDemCtrlTestResultRef}
        {enable-take-address=true, indirect-api=false, port-defined-argument-value{value=14, value-type=Dem_EventIdType}, port=EvtInfo_AutoCreatedDemEvent_A_FlexRay_FRIF_E_ACS_CH_A}
        {enable-take-address=true, indirect-api=false, port-defined-argument-value{value=15, value-type=Dem_EventIdType}, port=EvtInfo_AutoCreatedDemEvent_A_FlexRay_FRIF_E_ACS_CH_B}
        {enable-take-address=true, indirect-api=false, port-defined-argument-value{value=16, value-type=Dem_EventIdType}, port=EvtInfo_AutoCreatedDemEvent_A_FlexRay_FRIF_E_NIT_CH_A}
        {enable-take-address=true, indirect-api=false, port-defined-argument-value{value=17, value-type=Dem_EventIdType}, port=EvtInfo_AutoCreatedDemEvent_A_FlexRay_FRIF_E_NIT_CH_B}
        {enable-take-address=true, indirect-api=false, port-defined-argument-value{value=18, value-type=Dem_EventIdType}, port=EvtInfo_AutoCreatedDemEvent_A_FlexRay_FRIF_E_SW_CH_A}
        {enable-take-address=true, indirect-api=false, port-defined-argument-value{value=19, value-type=Dem_EventIdType}, port=EvtInfo_AutoCreatedDemEvent_A_FlexRay_FRIF_E_SW_CH_B}
        {enable-take-address=true, indirect-api=false, port-defined-argument-value{value=12, value-type=Dem_EventIdType}, port=EvtInfo_AutoCreatedDemEvent_A_FlexRay_5b5a9ac2_FRSM_E_CLUSTER_STARTUP}
        {enable-take-address=true, indirect-api=false, port-defined-argument-value{value=13, value-type=Dem_EventIdType}, port=EvtInfo_AutoCreatedDemEvent_A_FlexRay_5b5a9ac2_FRSM_E_CLUSTER_SYNC_LOSS}
        {enable-take-address=true, indirect-api=false, port-defined-argument-value{value=29, value-type=Dem_EventIdType}, port=EvtInfo_AutoCreatedDemEvent_McuModuleConfiguration_MCU_E_CLOCK_FAILURE}
        {enable-take-address=true, indirect-api=false, port-defined-argument-value{value=2, value-type=Dem_EventIdType}, port=EvtInfo_DemEventParameter_002}
        {enable-take-address=true, indirect-api=false, port-defined-argument-value{value=2, value-type=Dem_EventIdType}, port=Event_DemEventParameter_002}
        {enable-take-address=true, indirect-api=false, port-defined-argument-value{value=3, value-type=Dem_EventIdType}, port=EvtInfo_DemEventParameter_003}
        {enable-take-address=true, indirect-api=false, port-defined-argument-value{value=3, value-type=Dem_EventIdType}, port=Event_DemEventParameter_003}
        {enable-take-address=true, indirect-api=false, port-defined-argument-value{value=4, value-type=Dem_EventIdType}, port=EvtInfo_DemEventParameter_004}
        {enable-take-address=true, indirect-api=false, port-defined-argument-value{value=4, value-type=Dem_EventIdType}, port=Event_DemEventParameter_004}
        {enable-take-address=true, indirect-api=false, port-defined-argument-value{value=5, value-type=Dem_EventIdType}, port=EvtInfo_DemEventParameter_005}
        {enable-take-address=true, indirect-api=false, port-defined-argument-value{value=5, value-type=Dem_EventIdType}, port=Event_DemEventParameter_005}
        {enable-take-address=true, indirect-api=false, port-defined-argument-value{value=6, value-type=Dem_EventIdType}, port=EvtInfo_DemEventParameter_006}
        {enable-take-address=true, indirect-api=false, port-defined-argument-value{value=6, value-type=Dem_EventIdType}, port=Event_DemEventParameter_006}
        {enable-take-address=true, indirect-api=false, port-defined-argument-value{value=7, value-type=Dem_EventIdType}, port=EvtInfo_DemEventParameter_007}
        {enable-take-address=true, indirect-api=false, port-defined-argument-value{value=7, value-type=Dem_EventIdType}, port=Event_DemEventParameter_007}
        {enable-take-address=true, indirect-api=false, port-defined-argument-value{value=8, value-type=Dem_EventIdType}, port=EvtInfo_DemEventParameter_008}
        {enable-take-address=true, indirect-api=false, port-defined-argument-value{value=8, value-type=Dem_EventIdType}, port=Event_DemEventParameter_008}
        {enable-take-address=true, indirect-api=false, port-defined-argument-value{value=9, value-type=Dem_EventIdType}, port=EvtInfo_DemEventParameter_009}
        {enable-take-address=true, indirect-api=false, port-defined-argument-value{value=9, value-type=Dem_EventIdType}, port=Event_DemEventParameter_009}
        {enable-take-address=true, indirect-api=false, port-defined-argument-value{value=10, value-type=Dem_EventIdType}, port=EvtInfo_DemEventParameter_010}
        {enable-take-address=true, indirect-api=false, port-defined-argument-value{value=10, value-type=Dem_EventIdType}, port=Event_DemEventParameter_010}
        {enable-take-address=true, indirect-api=false, port-defined-argument-value{value=11, value-type=Dem_EventIdType}, port=EvtInfo_DemEventParameter_011}
        {enable-take-address=true, indirect-api=false, port-defined-argument-value{value=11, value-type=Dem_EventIdType}, port=Event_DemEventParameter_011}
      15 x runnable:
        Dem_SatelliteMainFunction
        GetEventUdsStatus: can-be-invoked-concurrently=true, symbol=Dem_GetEventUdsStatus
        GetEventStatus: can-be-invoked-concurrently=true, symbol=Dem_GetEventUdsStatus
        GetEventFailed: can-be-invoked-concurrently=true, symbol=Dem_GetEventFailed
        GetEventTested: can-be-invoked-concurrently=true, symbol=Dem_GetEventTested
        GetDTCOfEvent: can-be-invoked-concurrently=true, symbol=Dem_GetDTCOfEvent
        GetFaultDetectionCounter: can-be-invoked-concurrently=true, symbol=Dem_GetFaultDetectionCounter
        GetEventFreezeFrameDataEx: can-be-invoked-concurrently=true, symbol=Dem_GetEventFreezeFrameDataEx
        GetEventExtendedDataRecordEx: can-be-invoked-concurrently=true, symbol=Dem_GetEventExtendedDataRecordEx
        GetEventEnableCondition: can-be-invoked-concurrently=true, symbol=Dem_GetEventEnableCondition
        GetDebouncingOfEvent: can-be-invoked-concurrently=true, symbol=Dem_GetDebouncingOfEvent
        GetMonitorStatus: can-be-invoked-concurrently=true, symbol=Dem_GetMonitorStatus
        SetEventStatus: can-be-invoked-concurrently=true, symbol=Dem_SetEventStatus
        ResetEventStatus: can-be-invoked-concurrently=true, symbol=Dem_ResetEventStatus
        ResetEventDebounceStatus: can-be-invoked-concurrently=true, symbol=Dem_ResetEventDebounceStatus
  swc implementation DemSatellite_0Implementation: programming-language=C, behavior=DemSatellite_0InternalBehavior
